VERSION ""

NS_ :

BS_:

BU_: TESTECU BIANSUXIANG SCR EBSECU DisPlay EngineECU
VAL_TABLE_ FMI 31 "Not available" 19 "Received network data in error" 18 "Below normal (moderately severe)" 17 "Below normal (least severe)" 16 "Above normal (moderately severe)" 15 "Above normal (least severe)" 14 "Special intstructions" 13 "Out of calibration" 12 "Bad intelligent device" 11 "Root cause not known" 10 "Abnormal rate of change" 9 "Abnormal update rate" 8 "Abnormal frequency" 7 "Mechanical system not responding" 6 "Current above normal" 5 "Current below normal" 4 "Voltage below normal" 3 "Voltage above normal" 2 "Data erratic" 1 "Below normal (most severe)" 0 "Above normal (most severe)" ;

BO_ 3221225472 VECTOR__INDEPENDENT_SIG_MSG: 0 Vector__XXX
 SG_ AETCTorqueValue : 0|16@1+ (1,0) [0|64255] "Nm" Vector__XXX
 SG_ TrailerWeight : 0|16@1+ (2,0) [0|128510] "kg" Vector__XXX
 SG_ ReferenceTirePressSetting : 0|8@1+ (8,0) [0|2000] "kPa" Vector__XXX
 SG_ ReferenceTirePress : 0|8@1+ (8,0) [0|2000] "kPa" Vector__XXX
 SG_ TirePressThresholdDetection : 0|3@1+ (1,0) [0|7] "" Vector__XXX
 SG_ TireAirLeakageRate : 0|16@1+ (0.1,0) [0|6425.5] "Pa/s" Vector__XXX
 SG_ CTIWheelEndElectricalFault : 0|2@1+ (1,0) [0|3] "" Vector__XXX
 SG_ CTITireStatus : 0|2@1+ (1,0) [0|3] "" Vector__XXX
 SG_ CTIWheelSensorStatus : 0|2@1+ (1,0) [0|3] "" Vector__XXX
 SG_ TireTemp : 0|16@1+ (0.03125,-273) [-273|1734.96875] "deg C" Vector__XXX
 SG_ TirePress : 0|8@1+ (4,0) [0|1000] "kPa" Vector__XXX
 SG_ EngTurningGearEngaged : 0|2@1+ (1,0) [0|3] "" Vector__XXX
 SG_ AETCSpeedValue : 0|16@1+ (0.125,0) [0|8031.875] "rpm" Vector__XXX
 SG_ FlashRedStopLamp : 0|2@1+ (1,0) [0|3] "" Vector__XXX
 SG_ FlashProtectLamp : 0|2@1+ (1,0) [0|3] "" Vector__XXX
 SG_ FlashMalfuncIndicatorLamp : 0|2@1+ (1,0) [0|3] "" Vector__XXX

 CM_ SG_ FlashAmberWarningLamp : 0|2@1+ (1,0) [0|3] "" Vector__XXX
 CM_ SG_ MalfunctionIndicatorLampStatus : 0|2@1+ (1,0) [0|3] "" Vector__XXX
 SG_ AmberWarningLampStatus : 0|2@1+ (1,0) [0|3] "" Vector__XXX
 SG_ RedStopLampState : 0|2@1+ (1,0) [0|3] "" Vector__XXX
 SG_ ProtectLampStatus : 0|2@1+ (1,0) [0|3] "" Vector__XXX
 SG_ DTC5 : 0|32@1+ (1,0) [0|4294967295] "" Vector__XXX
 SG_ DTC4 : 0|32@1+ (1,0) [0|4294967295] "" Vector__XXX
 SG_ DTC3 : 0|32@1+ (1,0) [0|4294967295] "" Vector__XXX
 SG_ DTC2 : 0|32@1+ (1,0) [0|4294967295] "" Vector__XXX
 SG_ DTC1 : 0|32@1+ (1,0) [0|4294967295] "" Vector__XXX
 SG_ FlashRedStopLamp : 0|2@1+ (1,0) [0|3] "" Vector__XXX
 SG_ FlashProtectLamp : 0|2@1+ (1,0) [0|3] "" Vector__XXX
 SG_ FlashMalfuncIndicatorLamp : 0|2@1+ (1,0) [0|3] "" Vector__XXX

 CM_ SG_ FlashAmberWarningLamp : 0|2@1+ (1,0) [0|3] "" Vector__XXX
 SG_ MalfunctionIndicatorLampStatus : 0|2@1+ (1,0) [0|3] "" Vector__XXX
 SG_ AmberWarningLampStatus : 0|2@1+ (1,0) [0|3] "" Vector__XXX
 SG_ RedStopLampState : 0|2@1+ (1,0) [0|3] "" Vector__XXX
 SG_ ProtectLampStatus : 0|2@1+ (1,0) [0|3] "" Vector__XXX
 SG_ DTC5 : 0|32@1+ (1,0) [0|4294967295] "" Vector__XXX
 SG_ DTC4 : 0|32@1+ (1,0) [0|4294967295] "" Vector__XXX
 SG_ DTC3 : 0|32@1+ (1,0) [0|4294967295] "" Vector__XXX
 SG_ DTC2 : 0|32@1+ (1,0) [0|4294967295] "" Vector__XXX
 SG_ DTC1 : 0|32@1+ (1,0) [0|4294967295] "" Vector__XXX
 SG_ DTC5 : 0|32@1+ (1,0) [0|4294967295] "" Vector__XXX
 SG_ DTC4 : 0|32@1+ (1,0) [0|4294967295] "" Vector__XXX
 SG_ DTC3 : 0|32@1+ (1,0) [0|4294967295] "" Vector__XXX
 SG_ DTC2 : 0|32@1+ (1,0) [0|4294967295] "" Vector__XXX
 SG_ DTC5 : 0|32@1+ (1,0) [0|4294967295] "" Vector__XXX
 SG_ DTC4 : 0|32@1+ (1,0) [0|4294967295] "" Vector__XXX
 SG_ DTC3 : 0|32@1+ (1,0) [0|4294967295] "" Vector__XXX
 SG_ DTC2 : 0|32@1+ (1,0) [0|4294967295] "" Vector__XXX

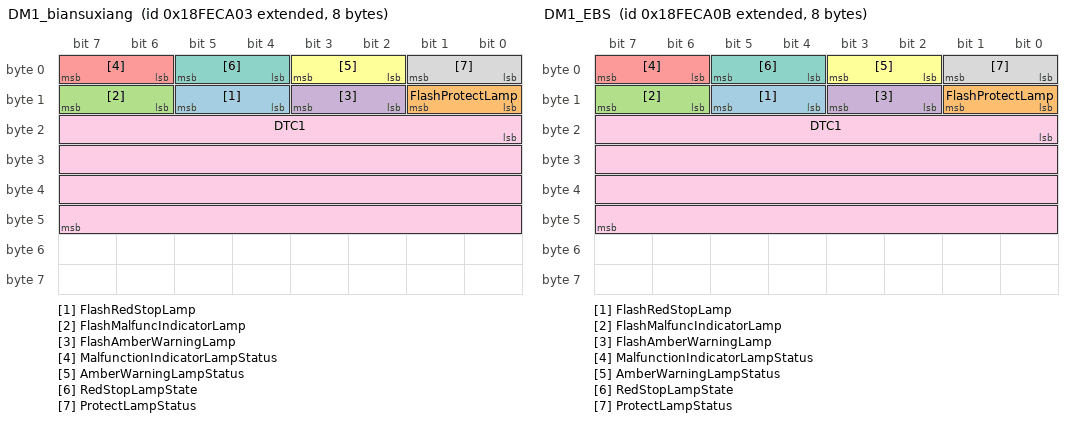
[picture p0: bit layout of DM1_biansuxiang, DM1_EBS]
BO_ 2566834691 DM1_biansuxiang: 8 BIANSUXIANG
 SG_ FlashRedStopLamp : 12|2@1+ (1,0) [0|3] "" Vector__XXX
 SG_ FlashProtectLamp : 8|2@1+ (1,0) [0|3] "" Vector__XXX
 SG_ FlashMalfuncIndicatorLamp : 14|2@1+ (1,0) [0|3] "" Vector__XXX
 SG_ FlashAmberWarningLamp : 10|2@1+ (1,0) [0|3] "" Vector__XXX
 SG_ MalfunctionIndicatorLampStatus : 6|2@1+ (1,0) [0|3] "" Vector__XXX
 SG_ AmberWarningLampStatus : 2|2@1+ (1,0) [0|3] "" Vector__XXX
 SG_ RedStopLampState : 4|2@1+ (1,0) [0|3] "" Vector__XXX
 SG_ ProtectLampStatus : 0|2@1+ (1,0) [0|3] "" Vector__XXX
 SG_ DTC1 : 16|32@1+ (1,0) [0|4294967295] "" Vector__XXX

BO_ 2415854369 Switch_event_3: 8 Vector__XXX

BO_ 2415857185 BOOT_Swtich3: 8 Vector__XXX

BO_ 2415854368 Switch_event_2: 8 Vector__XXX

BO_ 2415857184 BOOT_Swtich2: 8 Vector__XXX

BO_ 2415857406 BOOT_Swtich1: 8 Vector__XXX

BO_ 2415857407 BOOT: 8 Vector__XXX

BO_ 2415854590 Switch_event_1: 8 Vector__XXX

BO_ 2415854591 Switch_event: 8 Vector__XXX

BO_ 2566834699 DM1_EBS: 8 EBSECU
 SG_ FlashRedStopLamp : 12|2@1+ (1,0) [0|3] "" Vector__XXX
 SG_ FlashProtectLamp : 8|2@1+ (1,0) [0|3] "" Vector__XXX
 SG_ FlashMalfuncIndicatorLamp : 14|2@1+ (1,0) [0|3] "" Vector__XXX
 SG_ FlashAmberWarningLamp : 10|2@1+ (1,0) [0|3] "" Vector__XXX
 SG_ MalfunctionIndicatorLampStatus : 6|2@1+ (1,0) [0|3] "" Vector__XXX
 SG_ AmberWarningLampStatus : 2|2@1+ (1,0) [0|3] "" Vector__XXX
 SG_ RedStopLampState : 4|2@1+ (1,0) [0|3] "" Vector__XXX
 SG_ ProtectLampStatus : 0|2@1+ (1,0) [0|3] "" Vector__XXX
 SG_ DTC1 : 16|32@1+ (1,0) [0|4294967295] "" Vector__XXX

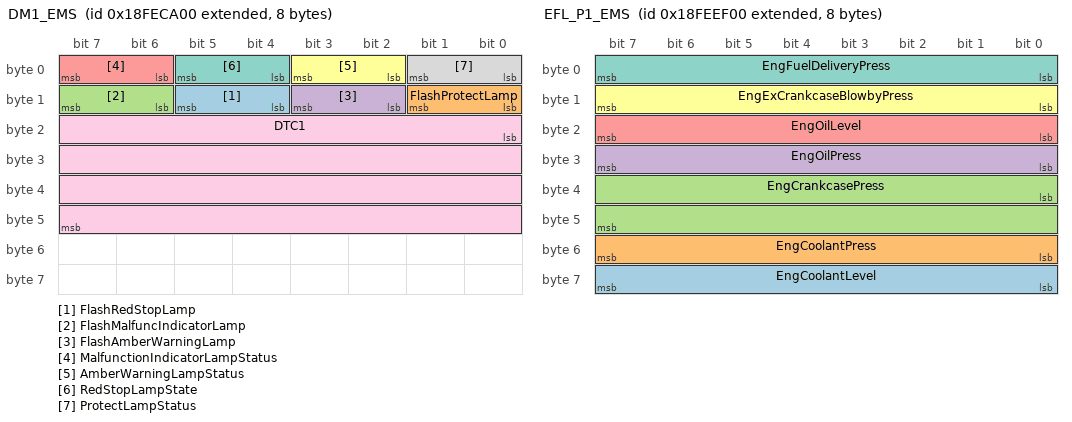
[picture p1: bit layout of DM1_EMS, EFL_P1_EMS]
BO_ 2566834688 DM1_EMS: 8 EngineECU
 SG_ FlashRedStopLamp : 12|2@1+ (1,0) [0|3] "" Vector__XXX
 SG_ FlashProtectLamp : 8|2@1+ (1,0) [0|3] "" Vector__XXX
 SG_ FlashMalfuncIndicatorLamp : 14|2@1+ (1,0) [0|3] "" Vector__XXX
 SG_ FlashAmberWarningLamp : 10|2@1+ (1,0) [0|3] "" Vector__XXX
 SG_ MalfunctionIndicatorLampStatus : 6|2@1+ (1,0) [0|3] "" Vector__XXX
 SG_ AmberWarningLampStatus : 2|2@1+ (1,0) [0|3] "" Vector__XXX
 SG_ RedStopLampState : 4|2@1+ (1,0) [0|3] "" Vector__XXX
 SG_ ProtectLampStatus : 0|2@1+ (1,0) [0|3] "" Vector__XXX
 SG_ DTC1 : 16|32@1+ (1,0) [0|4294967295] "" Vector__XXX

BO_ 2566910720 WCOI: 8 EngineECU
 SG_ WaterInFuelIndicator : 24|2@1+ (1,0) [0|3] ""  DisPlay

BO_ 2566805053 AT1T1I_SCR: 8 SCR
 SG_ Aftrtrtmnt1DslExhstFlidTankLevel : 0|8@1+ (0.4,0) [0|100] "%" Vector__XXX

BO_ 2566804992 AT1T1I_EMS: 8 EngineECU
 SG_ Aftrtrtmnt1DslExhstFlidTankLevel : 0|8@1+ (0.4,0) [0|100] "%"  DisPlay

BO_ 2566844160 EFL_P1_EMS: 8 EngineECU
 SG_ EngCoolantLevel : 56|8@1+ (0.4,0) [0|100] "%" Vector__XXX
 SG_ EngCoolantPress : 48|8@1+ (2,0) [0|500] "kPa" Vector__XXX
 SG_ EngCrankcasePress : 32|16@1+ (0.0078125,-250) [-250|251.99] "kPa" Vector__XXX
 SG_ EngOilPress : 24|8@1+ (4,0) [0|1000] "kPa"  DisPlay
 SG_ EngOilLevel : 16|8@1+ (0.4,0) [0|100] "%" Vector__XXX
 SG_ EngExCrankcaseBlowbyPress : 8|8@1+ (0.05,0) [0|12.5] "kPa" Vector__XXX
 SG_ EngFuelDeliveryPress : 0|8@1+ (4,0) [0|1000] "kPa" Vector__XXX

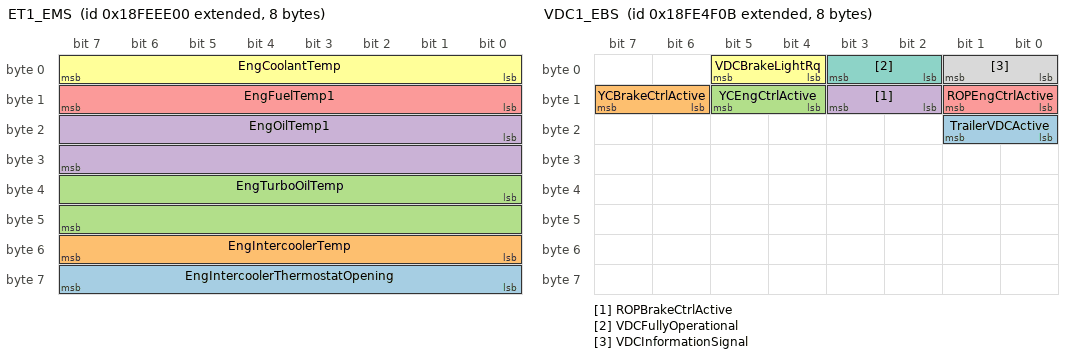
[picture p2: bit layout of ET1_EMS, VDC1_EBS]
BO_ 2566843904 ET1_EMS: 8 EngineECU
 SG_ EngIntercoolerThermostatOpening : 56|8@1+ (0.4,0) [0|100] "%" Vector__XXX
 SG_ EngIntercoolerTemp : 48|8@1+ (1,-40) [-40|210] "deg C" Vector__XXX
 SG_ EngTurboOilTemp : 32|16@1+ (0.03125,-273) [-273|1734.96875] "deg C" Vector__XXX
 SG_ EngOilTemp1 : 16|16@1+ (0.03125,-273) [-273|1734.96875] "deg C" Vector__XXX
 SG_ EngFuelTemp1 : 8|8@1+ (1,-40) [-40|210] "deg C" Vector__XXX
 SG_ EngCoolantTemp : 0|8@1+ (1,-40) [-40|210] "deg C" Vector__XXX

BO_ 2566844672 CCVS1_EMS: 8 EngineECU
 SG_ EngShutdownOverrideSwitch : 62|2@1+ (1,0) [0|3] "" Vector__XXX
 SG_ EngTestModeSwitch : 60|2@1+ (1,0) [0|3] "" Vector__XXX
 SG_ EngIdleDecrementSwitch : 58|2@1+ (1,0) [0|3] "" Vector__XXX
 SG_ EngIdleIncrementSwitch : 56|2@1+ (1,0) [0|3] "" Vector__XXX
 SG_ CruiseCtrlStates : 53|3@1+ (1,0) [0|7] "" Vector__XXX
 SG_ PTOGovernorState : 48|5@1+ (1,0) [0|31] "" Vector__XXX
 SG_ CruiseCtrlSetSpeed : 40|8@1+ (1,0) [0|250] "km/h" Vector__XXX
 SG_ CruiseCtrlAccelerateSwitch : 38|2@1+ (1,0) [0|3] "" Vector__XXX
 SG_ CruiseCtrlResumeSwitch : 36|2@1+ (1,0) [0|3] "" Vector__XXX
 SG_ CruiseCtrlCoastSwitch : 34|2@1+ (1,0) [0|3] "" Vector__XXX
 SG_ CruiseCtrlSetSwitch : 32|2@1+ (1,0) [0|3] "" Vector__XXX
 SG_ ClutchSwitch : 30|2@1+ (1,0) [0|3] "" Vector__XXX
 SG_ BrakeSwitch : 28|2@1+ (1,0) [0|3] "" Vector__XXX
 SG_ CruiseCtrlEnableSwitch : 26|2@1+ (1,0) [0|3] "" Vector__XXX
 SG_ CruiseCtrlActive : 24|2@1+ (1,0) [0|3] ""  DisPlay
 SG_ WheelBasedVehicleSpeed : 8|16@1+ (0.00390625,0) [0|250.996] "km/h" Vector__XXX
 SG_ ParkBrakeReleaseInhibitRq : 6|2@1+ (1,0) [0|3] "" Vector__XXX
 SG_ CruiseCtrlPauseSwitch : 4|2@1+ (1,0) [0|3] "" Vector__XXX
 SG_ ParkingBrakeSwitch : 2|2@1+ (1,0) [0|3] "" Vector__XXX
 SG_ TwoSpeedAxleSwitch : 0|2@1+ (1,0) [0|3] "" Vector__XXX

BO_ 2566841344 SHUTDN_EMS: 8 EngineECU
 SG_ ClntLvlEngPrtctionShutdownStatus : 60|2@1+ (1,0) [0|3] "" Vector__XXX
 SG_ PTOShutdownHasShutdownEng : 58|2@1+ (1,0) [0|3] "" Vector__XXX
 SG_ EngAirShutoffStatus : 56|2@1+ (1,0) [0|3] "" Vector__XXX
 SG_ EngOverspeedTest : 54|2@1+ (1,0) [0|3] "" Vector__XXX
 SG_ EngAirShutoffCmdStatus : 52|2@1+ (1,0) [0|3] "" Vector__XXX
 SG_ EngAlarmOutputCmdStatus : 50|2@1+ (1,0) [0|3] "" Vector__XXX
 SG_ EngAlarmAcknowledge : 48|2@1+ (1,0) [0|3] "" Vector__XXX
 SG_ EngProtectionSystemConfig : 46|2@1+ (1,0) [0|3] "" Vector__XXX
 SG_ EngProtectionSystemTimerState : 38|2@1+ (1,0) [0|3] "" Vector__XXX
 SG_ EngProtectionSystemTimerOverride : 36|2@1+ (1,0) [0|3] "" Vector__XXX
 SG_ EngPrtctnSystmApprachingShutdown : 34|2@1+ (1,0) [0|3] "" Vector__XXX
 SG_ EngPrtectionSystemHasShutdownEng : 32|2@1+ (1,0) [0|3] "" Vector__XXX
 SG_ EngWaitToStartLamp : 24|2@1+ (1,0) [0|3] ""  DisPlay
 SG_ RefrigerantHighPressSwitch : 20|2@1+ (1,0) [0|3] "" Vector__XXX
 SG_ RefrigerantLowPressSwitch : 18|2@1+ (1,0) [0|3] "" Vector__XXX
 SG_ A_CHighPressFanSwitch : 16|2@1+ (1,0) [0|3] "" Vector__XXX
 SG_ EngIdleShutdownTimerFunction : 14|2@1+ (1,0) [0|3] "" Vector__XXX
 SG_ EngIdleShutdownTimerState : 6|2@1+ (1,0) [0|3] "" Vector__XXX
 SG_ EngIdleShutdownTimerOverride : 4|2@1+ (1,0) [0|3] "" Vector__XXX
 SG_ EngIdleShutdownDriverAlertMode : 2|2@1+ (1,0) [0|3] "" Vector__XXX
 SG_ EngIdleShutdownHasShutdownEng : 0|2@1+ (1,0) [0|3] "" Vector__XXX

BO_ 2566803211 VDC1_EBS: 8 EBSECU
 SG_ TrailerVDCActive : 16|2@1+ (1,0) [0|3] "" Vector__XXX
 SG_ YCBrakeCtrlActive : 14|2@1+ (1,0) [0|3] "" Vector__XXX
 SG_ YCEngCtrlActive : 12|2@1+ (1,0) [0|3] "" Vector__XXX
 SG_ ROPBrakeCtrlActive : 10|2@1+ (1,0) [0|3] "" Vector__XXX
 SG_ ROPEngCtrlActive : 8|2@1+ (1,0) [0|3] "" Vector__XXX
 SG_ VDCBrakeLightRq : 4|2@1+ (1,0) [0|3] "" Vector__XXX
 SG_ VDCFullyOperational : 2|2@1+ (1,0) [0|3] "" Vector__XXX
 SG_ VDCInformationSignal : 0|2@1+ (1,0) [0|3] "" Vector__XXX

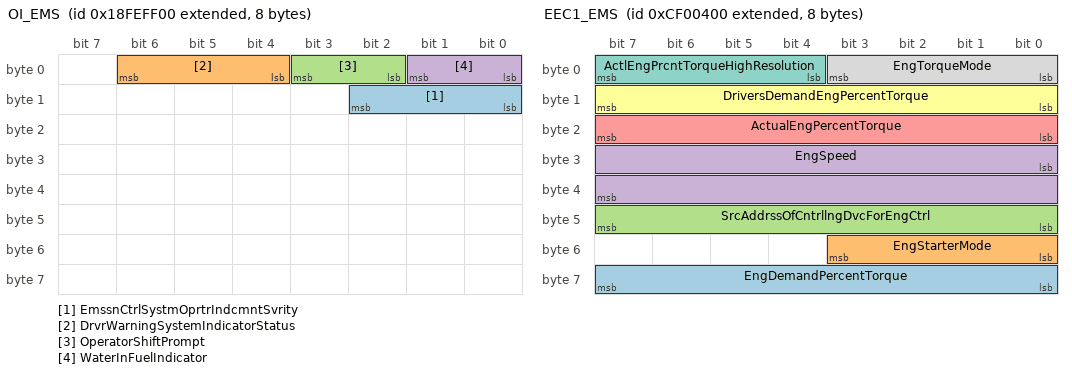
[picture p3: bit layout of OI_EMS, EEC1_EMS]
BO_ 2566848256 OI_EMS: 8 EngineECU
 SG_ EmssnCtrlSystmOprtrIndcmntSvrity : 8|3@1+ (1,0) [0|7] "" Vector__XXX
 SG_ DrvrWarningSystemIndicatorStatus : 4|3@1+ (1,0) [0|7] "" Vector__XXX
 SG_ OperatorShiftPrompt : 2|2@1+ (1,0) [0|3] "" Vector__XXX
 SG_ WaterInFuelIndicator : 0|2@1+ (1,0) [0|3] ""  DisPlay

BO_ 2364539904 EEC1_EMS: 8 EngineECU
 SG_ EngDemandPercentTorque : 56|8@1+ (1,-125) [-125|125] "%"  DisPlay
 SG_ EngStarterMode : 48|4@1+ (1,0) [0|15] ""  DisPlay
 SG_ SrcAddrssOfCntrllngDvcForEngCtrl : 40|8@1+ (1,0) [0|255] ""  DisPlay
 SG_ EngSpeed : 24|16@1+ (0.125,0) [0|8031.875] "rpm"  DisPlay
 SG_ ActualEngPercentTorque : 16|8@1+ (1,-125) [-125|125] "%"  DisPlay
 SG_ DriversDemandEngPercentTorque : 8|8@1+ (1,-125) [-125|125] "%"  DisPlay
 SG_ ActlEngPrcntTorqueHighResolution : 4|4@1+ (0.125,0) [0|0.875] "%"  DisPlay
 SG_ EngTorqueMode : 0|4@1+ (1,0) [0|15] ""  DisPlay

BO_ 2559835902 NM: 8 Vector__XXX
 SG_ NameChecksum m0 : 0|8@1+ (1,0) [0|0] "" Vector__XXX
 SG_ ErrorCode m4 : 0|8@1+ (1,0) [0|0] "" Vector__XXX
 SG_ CommandArbitraryAddressCapable m0 : 63|1@1+ (1,0) [0|1] "" Vector__XXX
 SG_ CommandVehicleSystemInstance m0 : 56|4@1+ (1,0) [0|15] "" Vector__XXX
 SG_ CommandIndustryGroup m0 : 60|3@1+ (1,0) [0|7] "" Vector__XXX
 SG_ CommandVehicleSystem m0 : 49|7@1+ (1,0) [0|127] "" Vector__XXX
 SG_ CommandFunction m0 : 40|8@1+ (1,0) [0|255] "" Vector__XXX
 SG_ CommandFunctionInstance m0 : 35|5@1+ (1,0) [0|31] "" Vector__XXX
 SG_ CommandECUInstance m0 : 32|3@1+ (1,0) [0|7] "" Vector__XXX
 SG_ CommandManufacturerCode m0 : 21|11@1+ (1,0) [0|2047] "" Vector__XXX
 SG_ NMControlModeIndicator M : 16|4@1+ (1,0) [0|15] "" Vector__XXX
 SG_ ArbitraryAddressCapableQualifier m0 : 15|1@1+ (1,0) [0|1] "" Vector__XXX
 SG_ IndustryGroupQualifierFlag m0 : 14|1@1+ (1,0) [0|1] "" Vector__XXX
 SG_ VehicleSystemInstanceQualifierFl m0 : 13|1@1+ (1,0) [0|1] "" Vector__XXX
 SG_ VehicleSystemQualifierFlag m0 : 12|1@1+ (1,0) [0|1] "" Vector__XXX
 SG_ FunctionQualifierFlag m0 : 11|1@1+ (1,0) [0|1] "" Vector__XXX
 SG_ FunctionInstanceQualifierFlag m0 : 10|1@1+ (1,0) [0|1] "" Vector__XXX
 SG_ ECUInstanceQualifierFlag m0 : 9|1@1+ (1,0) [0|1] "" Vector__XXX
 SG_ ManufacturerCodeQualifierFlag m0 : 8|1@1+ (1,0) [0|1] "" Vector__XXX

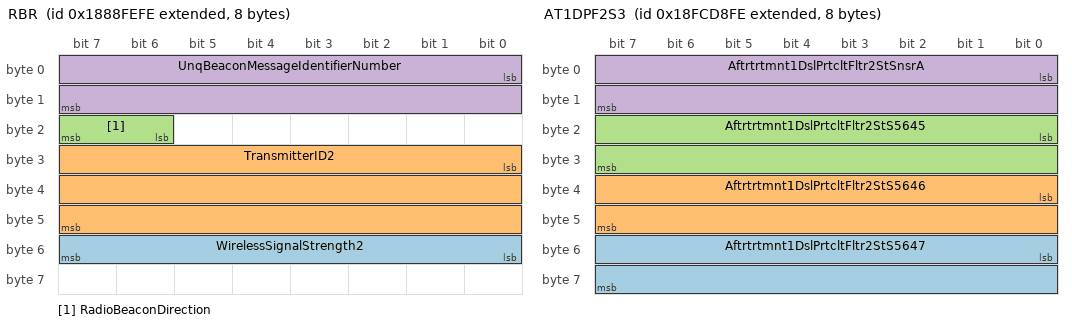
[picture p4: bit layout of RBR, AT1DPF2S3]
BO_ 2559115006 RBR: 8 Vector__XXX
 SG_ WirelessSignalStrength2 : 48|8@1+ (0.5,0) [-125|0] "dBm" Vector__XXX
 SG_ TransmitterID2 : 24|24@1+ (1,0) [0|16449635] "" Vector__XXX
 SG_ RadioBeaconDirection : 22|2@1+ (1,0) [0|3] "" Vector__XXX
 SG_ UnqBeaconMessageIdentifierNumber : 0|16@1+ (1,0) [0|64255] "" Vector__XXX

BO_ 2566707454 AT1DPF2S3: 8 Vector__XXX
 SG_ Aftrtrtmnt1DslPrtcltFltr2StS5647 : 48|16@1+ (0.1,0) [0|6425.5] "MHz" Vector__XXX
 SG_ Aftrtrtmnt1DslPrtcltFltr2StS5646 : 32|16@1+ (0.1,0) [0|6425.5] "MHz" Vector__XXX
 SG_ Aftrtrtmnt1DslPrtcltFltr2StS5645 : 16|16@1+ (0.1,0) [0|6425.5] "MHz" Vector__XXX
 SG_ Aftrtrtmnt1DslPrtcltFltr2StSnsrA : 0|16@1+ (0.1,0) [0|6425.5] "MHz" Vector__XXX

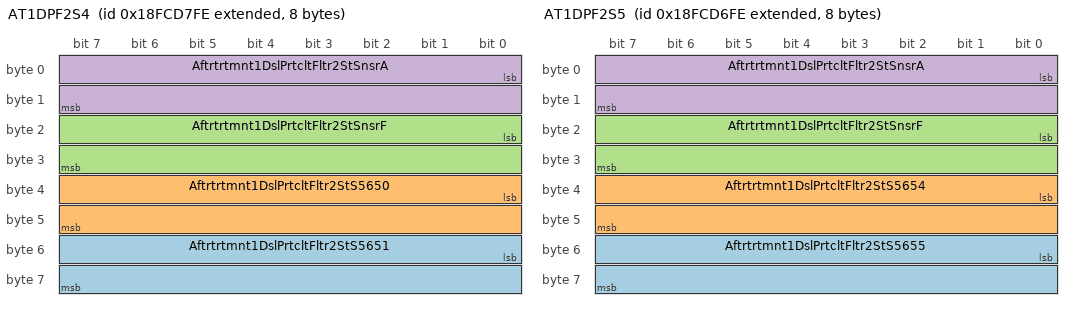
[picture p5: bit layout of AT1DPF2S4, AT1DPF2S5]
BO_ 2566707198 AT1DPF2S4: 8 Vector__XXX
 SG_ Aftrtrtmnt1DslPrtcltFltr2StS5651 : 48|16@1+ (0.0025,0) [0|160.6375] "%" Vector__XXX
 SG_ Aftrtrtmnt1DslPrtcltFltr2StS5650 : 32|16@1+ (0.1,0) [0|6425.5] "MHz" Vector__XXX
 SG_ Aftrtrtmnt1DslPrtcltFltr2StSnsrF : 16|16@1+ (0.0025,0) [0|160.6375] "%" Vector__XXX
 SG_ Aftrtrtmnt1DslPrtcltFltr2StSnsrA : 0|16@1+ (0.1,0) [0|6425.5] "MHz" Vector__XXX

BO_ 2566706942 AT1DPF2S5: 8 Vector__XXX
 SG_ Aftrtrtmnt1DslPrtcltFltr2StS5655 : 48|16@1+ (0.0025,0) [0|160.6375] "%" Vector__XXX
 SG_ Aftrtrtmnt1DslPrtcltFltr2StS5654 : 32|16@1+ (0.1,0) [0|6425.5] "MHz" Vector__XXX
 SG_ Aftrtrtmnt1DslPrtcltFltr2StSnsrF : 16|16@1+ (0.0025,0) [0|160.6375] "%" Vector__XXX
 SG_ Aftrtrtmnt1DslPrtcltFltr2StSnsrA : 0|16@1+ (0.1,0) [0|6425.5] "MHz" Vector__XXX

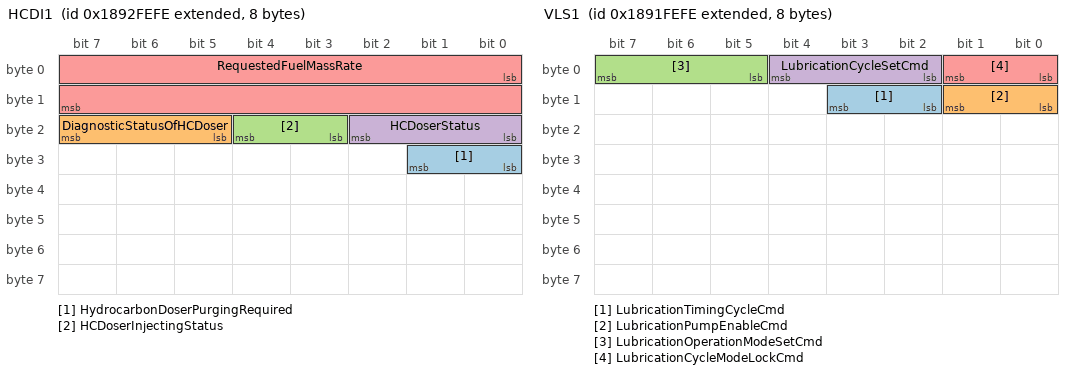
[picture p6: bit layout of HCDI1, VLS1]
BO_ 2559770366 HCDI1: 8 Vector__XXX
 SG_ HydrocarbonDoserPurgingRequired : 24|2@1+ (1,0) [0|3] "" Vector__XXX
 SG_ DiagnosticStatusOfHCDoser : 21|3@1+ (1,0) [0|7] "" Vector__XXX
 SG_ HCDoserInjectingStatus : 19|2@1+ (1,0) [0|3] "" Vector__XXX
 SG_ HCDoserStatus : 16|3@1+ (1,0) [0|7] "" Vector__XXX
 SG_ RequestedFuelMassRate : 0|16@1+ (0.05,0) [0|3212.75] "g/m" Vector__XXX

BO_ 2559704830 VLS1: 8 Vector__XXX
 SG_ LubricationTimingCycleCmd : 10|2@1+ (1,0) [0|3] "" Vector__XXX
 SG_ LubricationPumpEnableCmd : 8|2@1+ (1,0) [0|3] "" Vector__XXX
 SG_ LubricationOperationModeSetCmd : 5|3@1+ (1,0) [0|7] "" Vector__XXX
 SG_ LubricationCycleSetCmd : 2|3@1+ (1,0) [0|7] "" Vector__XXX
 SG_ LubricationCycleModeLockCmd : 0|2@1+ (1,0) [0|3] "" Vector__XXX

BO_ 2559639294 SFC: 8 Vector__XXX
 SG_ SupplementalFanPowerHold : 24|2@1+ (1,0) [0|3] "" Vector__XXX
 SG_ SupplementalFanSpeedCmd : 8|16@1+ (0.5,0) [0|32127.5] "rpm" Vector__XXX
 SG_ SupplementalFanDirectionCmd : 2|2@1+ (1,0) [0|3] "" Vector__XXX
 SG_ SupplementalFanEnableCmd : 0|2@1+ (1,0) [0|3] "" Vector__XXX

BO_ 2559573758 ECC: 8 Vector__XXX
 SG_ ClntLvlEngPrtctnShtdwnOvrrideCmd : 0|2@1+ (1,0) [0|3] "" Vector__XXX

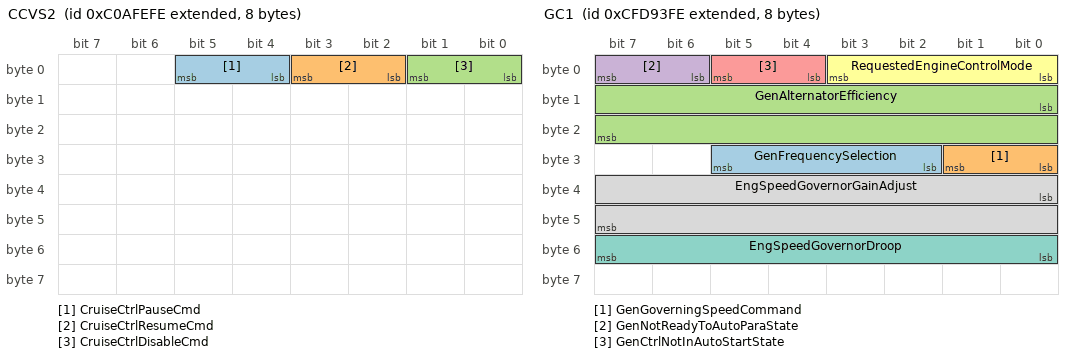
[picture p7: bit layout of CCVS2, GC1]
BO_ 2349530878 CCVS2: 8 Vector__XXX
 SG_ CruiseCtrlPauseCmd : 4|2@1+ (1,0) [0|3] "" Vector__XXX
 SG_ CruiseCtrlResumeCmd : 2|2@1+ (1,0) [0|3] "" Vector__XXX
 SG_ CruiseCtrlDisableCmd : 0|2@1+ (1,0) [0|3] "" Vector__XXX

BO_ 2559246078 RGE12: 8 Vector__XXX

BO_ 2559180542 RGE24: 8 Vector__XXX

BO_ 2365428734 GC1: 8 Vector__XXX
 SG_ GenFrequencySelection : 26|4@1+ (1,0) [0|15] "" Vector__XXX
 SG_ GenGoverningSpeedCommand : 24|2@1+ (1,0) [0|3] "" Vector__XXX
 SG_ GenAlternatorEfficiency : 8|16@1+ (0.0025,0) [0|163.8375] "%" Vector__XXX
 SG_ GenNotReadyToAutoParaState : 6|2@1+ (1,0) [0|0] "" Vector__XXX
 SG_ GenCtrlNotInAutoStartState : 4|2@1+ (1,0) [0|0] "" Vector__XXX
 SG_ RequestedEngineControlMode : 0|4@1+ (1,0) [0|0] "" Vector__XXX
 SG_ EngSpeedGovernorDroop : 48|8@1+ (0.04,0) [0|10] "%" Vector__XXX
 SG_ EngSpeedGovernorGainAdjust : 32|16@1+ (1,-32128) [-32128|32127] "" Vector__XXX

BO_ 2566702846 DM57: 8 Vector__XXX
 SG_ EngOBDWarmUpSequence : 0|2@1+ (1,0) [0|3] "" Vector__XXX

BO_ 2566703102 DM56: 208 Vector__XXX
 SG_ CertificationEngineFamilyName : 64|64@1+ (1,0) [0|255] "" Vector__XXX
 SG_ ModelYear : 0|64@1+ (1,0) [0|1.84467440737096E+019] "" Vector__XXX

BO_ 2566705918 DM54: 22 Vector__XXX
 SG_ DTC1 : 16|32@1+ (1,0) [0|4294967295] "" Vector__XXX
 SG_ FlashProtectLamp : 8|2@1+ (1,0) [0|3] "" Vector__XXX
 SG_ FlashAmberWarningLamp : 10|2@1+ (1,0) [0|3] "" Vector__XXX
 SG_ FlashRedStopLamp : 12|2@1+ (1,0) [0|3] "" Vector__XXX
 SG_ FlashMalfuncIndicatorLamp : 14|2@1+ (1,0) [0|3] "" Vector__XXX
 SG_ ProtectLampStatus : 0|2@1+ (1,0) [0|3] "" Vector__XXX
 SG_ AmberWarningLampStatus : 2|2@1+ (1,0) [0|3] "" Vector__XXX
 SG_ RedStopLampState : 4|2@1+ (1,0) [0|3] "" Vector__XXX
 SG_ MalfunctionIndicatorLampStatus : 6|2@1+ (1,0) [0|3] "" Vector__XXX
 SG_ DTC5 : 144|32@1+ (1,0) [0|4294967295] "" Vector__XXX
 SG_ DTC4 : 112|32@1+ (1,0) [0|4294967295] "" Vector__XXX
 SG_ DTC3 : 80|32@1+ (1,0) [0|4294967295] "" Vector__XXX
 SG_ DTC2 : 48|32@1+ (1,0) [0|4294967295] "" Vector__XXX

BO_ 2566705662 DM53: 22 Vector__XXX
 SG_ DTC1 : 16|32@1+ (1,0) [0|4294967295] "" Vector__XXX
 SG_ FlashProtectLamp : 8|2@1+ (1,0) [0|3] "" Vector__XXX
 SG_ FlashAmberWarningLamp : 10|2@1+ (1,0) [0|3] "" Vector__XXX
 SG_ FlashRedStopLamp : 12|2@1+ (1,0) [0|3] "" Vector__XXX
 SG_ FlashMalfuncIndicatorLamp : 14|2@1+ (1,0) [0|3] "" Vector__XXX
 SG_ ProtectLampStatus : 0|2@1+ (1,0) [0|3] "" Vector__XXX
 SG_ AmberWarningLampStatus : 2|2@1+ (1,0) [0|3] "" Vector__XXX
 SG_ RedStopLampState : 4|2@1+ (1,0) [0|3] "" Vector__XXX
 SG_ MalfunctionIndicatorLampStatus : 6|2@1+ (1,0) [0|3] "" Vector__XXX
 SG_ DTC5 : 144|32@1+ (1,0) [0|4294967295] "" Vector__XXX
 SG_ DTC4 : 112|32@1+ (1,0) [0|4294967295] "" Vector__XXX
 SG_ DTC3 : 80|32@1+ (1,0) [0|4294967295] "" Vector__XXX
 SG_ DTC2 : 48|32@1+ (1,0) [0|4294967295] "" Vector__XXX

BO_ 2566706174 DM55: 0 Vector__XXX

BO_ 2349465342 SRASI: 8 Vector__XXX
 SG_ StaticRollAngleStatus : 8|3@1+ (1,0) [0|7] "" Vector__XXX
 SG_ StaticRollAngle : 0|8@1+ (1,-125) [-125|125] "deg" Vector__XXX

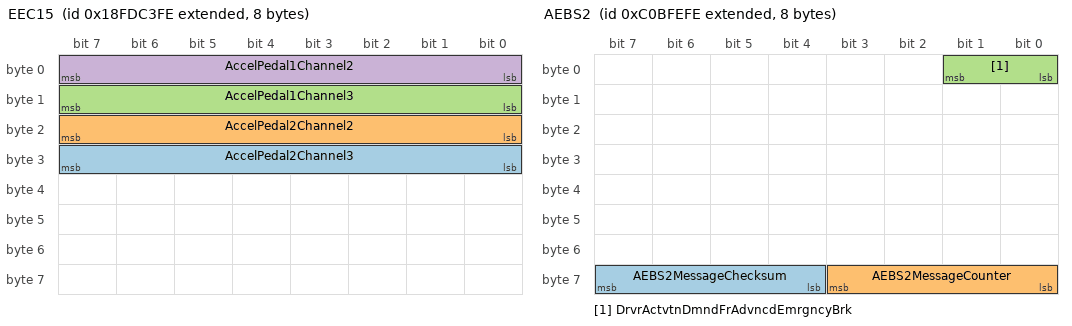
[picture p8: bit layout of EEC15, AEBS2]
BO_ 2566767614 EEC15: 8 Vector__XXX
 SG_ AccelPedal2Channel3 : 24|8@1+ (0.4,0) [0|100] "%" Vector__XXX
 SG_ AccelPedal2Channel2 : 16|8@1+ (0.4,0) [0|100] "%" Vector__XXX
 SG_ AccelPedal1Channel3 : 8|8@1+ (0.4,0) [0|100] "%" Vector__XXX
 SG_ AccelPedal1Channel2 : 0|8@1+ (0.4,0) [0|100] "%" Vector__XXX

BO_ 2559049470 ESR: 8 Vector__XXX
 SG_ DesiredEngFuelingState : 0|2@1+ (1,0) [0|3] "" Vector__XXX

BO_ 2349596414 AEBS2: 8 Vector__XXX
 SG_ AEBS2MessageChecksum : 60|4@1+ (1,0) [0|15] "" Vector__XXX
 SG_ AEBS2MessageCounter : 56|4@1+ (1,0) [0|15] "" Vector__XXX
 SG_ DrvrActvtnDmndFrAdvncdEmrgncyBrk : 0|2@1+ (1,0) [0|3] "" Vector__XXX

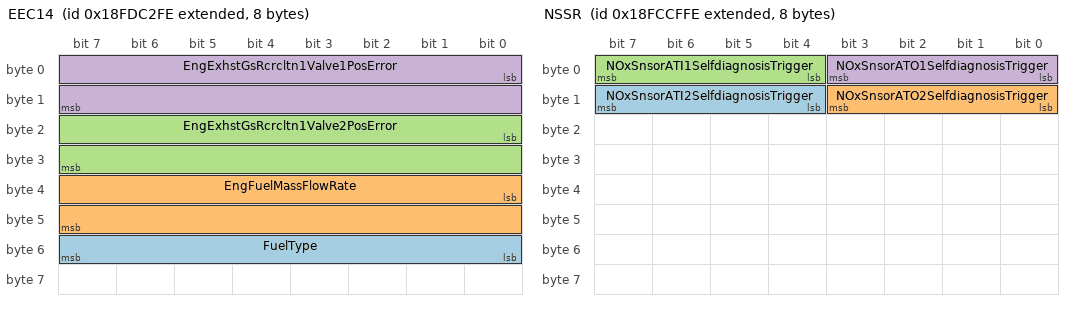
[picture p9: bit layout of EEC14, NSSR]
BO_ 2566767358 EEC14: 8 Vector__XXX
 SG_ FuelType : 48|8@1+ (1,0) [0|255] "" Vector__XXX
 SG_ EngFuelMassFlowRate : 32|16@1+ (0.005,0) [0|321.275] "g/s" Vector__XXX
 SG_ EngExhstGsRcrcltn1Valve2PosError : 16|16@1+ (0.004,-125) [-125|132.02] "%" Vector__XXX
 SG_ EngExhstGsRcrcltn1Valve1PosError : 0|16@1+ (0.004,-125) [-125|132.02] "%" Vector__XXX

BO_ 2566706686 AT1P1I: 8 Vector__XXX
 SG_ Aftrtrtmnt1DslExhstFldPumpHeater : 0|8@1+ (0.4,0) [0|100] "%" Vector__XXX

BO_ 2566705406 EPSI: 8 Vector__XXX
 SG_ Aftertreatment2ParticulateSensor : 16|16@1+ (0.0125,0) [0|803.1875] "mg/m^3" Vector__XXX
 SG_ Aftertreatment1ParticulateSensor : 0|16@1+ (0.0125,0) [0|803.1875] "mg/m^3" Vector__XXX

BO_ 2566705150 NSSR: 8 Vector__XXX
 SG_ NOxSnsorATI2SelfdiagnosisTrigger : 12|4@1+ (1,0) [0|15] "" Vector__XXX
 SG_ NOxSnsorATO2SelfdiagnosisTrigger : 8|4@1+ (1,0) [0|15] "" Vector__XXX
 SG_ NOxSnsorATI1SelfdiagnosisTrigger : 4|4@1+ (1,0) [0|15] "" Vector__XXX
 SG_ NOxSnsorATO1SelfdiagnosisTrigger : 0|4@1+ (1,0) [0|15] "" Vector__XXX

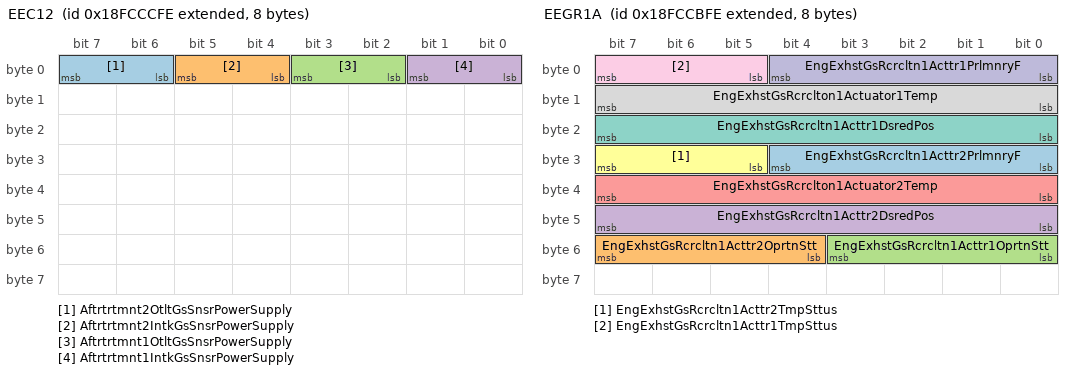
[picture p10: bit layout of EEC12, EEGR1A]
BO_ 2566704382 EEC12: 8 Vector__XXX
 SG_ Aftrtrtmnt2OtltGsSnsrPowerSupply : 6|2@1+ (1,0) [0|3] "" Vector__XXX
 SG_ Aftrtrtmnt2IntkGsSnsrPowerSupply : 4|2@1+ (1,0) [0|3] "" Vector__XXX
 SG_ Aftrtrtmnt1OtltGsSnsrPowerSupply : 2|2@1+ (1,0) [0|3] "" Vector__XXX
 SG_ Aftrtrtmnt1IntkGsSnsrPowerSupply : 0|2@1+ (1,0) [0|3] "" Vector__XXX

BO_ 2566704126 EEGR1A: 8 Vector__XXX
 SG_ EngExhstGsRcrcltn1Acttr2PrlmnryF : 24|5@1+ (1,0) [0|31] "" Vector__XXX
 SG_ EngExhstGsRcrcltn1Acttr2OprtnStt : 52|4@1+ (1,0) [0|15] "" Vector__XXX
 SG_ EngExhstGsRcrcltn1Acttr1OprtnStt : 48|4@1+ (1,0) [0|15] "" Vector__XXX
 SG_ EngExhstGsRcrcltn1Acttr2DsredPos : 40|8@1+ (0.4,0) [0|100] "%" Vector__XXX
 SG_ EngExhstGsRcrclton1Actuator2Temp : 32|8@1+ (1,-40) [-40|210] "deg C" Vector__XXX
 SG_ EngExhstGsRcrcltn1Acttr2TmpSttus : 29|3@1+ (1,0) [0|7] "" Vector__XXX
 SG_ EngExhstGsRcrcltn1Acttr1DsredPos : 16|8@1+ (0.4,0) [0|100] "%" Vector__XXX
 SG_ EngExhstGsRcrclton1Actuator1Temp : 8|8@1+ (1,-40) [-40|210] "deg C" Vector__XXX
 SG_ EngExhstGsRcrcltn1Acttr1TmpSttus : 5|3@1+ (1,0) [0|7] "" Vector__XXX
 SG_ EngExhstGsRcrcltn1Acttr1PrlmnryF : 0|5@1+ (1,0) [0|31] "" Vector__XXX

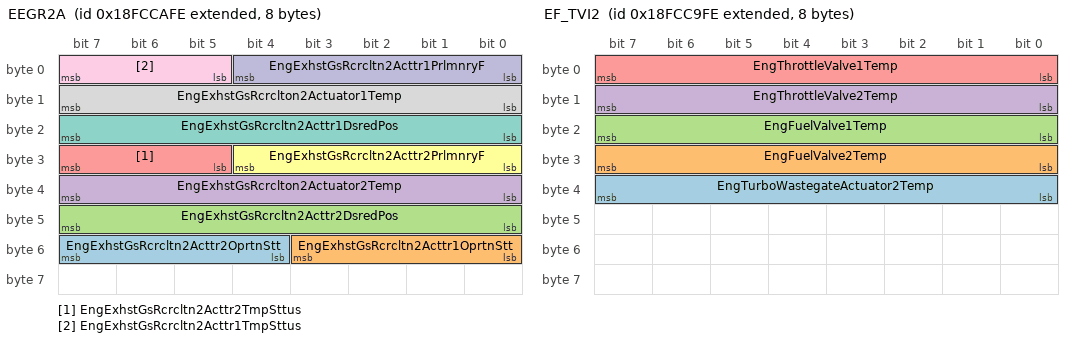
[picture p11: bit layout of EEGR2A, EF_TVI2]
BO_ 2566703870 EEGR2A: 8 Vector__XXX
 SG_ EngExhstGsRcrcltn2Acttr2OprtnStt : 52|4@1+ (1,0) [0|15] "" Vector__XXX
 SG_ EngExhstGsRcrcltn2Acttr1OprtnStt : 48|4@1+ (1,0) [0|15] "" Vector__XXX
 SG_ EngExhstGsRcrcltn2Acttr2DsredPos : 40|8@1+ (0.4,0) [0|100] "%" Vector__XXX
 SG_ EngExhstGsRcrclton2Actuator2Temp : 32|8@1+ (1,-40) [-40|210] "deg C" Vector__XXX
 SG_ EngExhstGsRcrcltn2Acttr2TmpSttus : 29|3@1+ (1,0) [0|7] "" Vector__XXX
 SG_ EngExhstGsRcrcltn2Acttr2PrlmnryF : 24|5@1+ (1,0) [0|31] "" Vector__XXX
 SG_ EngExhstGsRcrcltn2Acttr1DsredPos : 16|8@1+ (0.4,0) [0|100] "%" Vector__XXX
 SG_ EngExhstGsRcrclton2Actuator1Temp : 8|8@1+ (1,-40) [-40|210] "deg C" Vector__XXX
 SG_ EngExhstGsRcrcltn2Acttr1TmpSttus : 5|3@1+ (1,0) [0|7] "" Vector__XXX
 SG_ EngExhstGsRcrcltn2Acttr1PrlmnryF : 0|5@1+ (1,0) [0|31] "" Vector__XXX

BO_ 2566703614 EF_TVI2: 8 Vector__XXX
 SG_ EngTurboWastegateActuator2Temp : 32|8@1+ (1,-40) [-40|210] "deg C" Vector__XXX
 SG_ EngFuelValve2Temp : 24|8@1+ (1,-40) [-40|210] "deg C" Vector__XXX
 SG_ EngFuelValve1Temp : 16|8@1+ (1,-40) [-40|210] "deg C" Vector__XXX
 SG_ EngThrottleValve2Temp : 8|8@1+ (1,-40) [-40|210] "deg C" Vector__XXX
 SG_ EngThrottleValve1Temp : 0|8@1+ (1,-40) [-40|210] "deg C" Vector__XXX

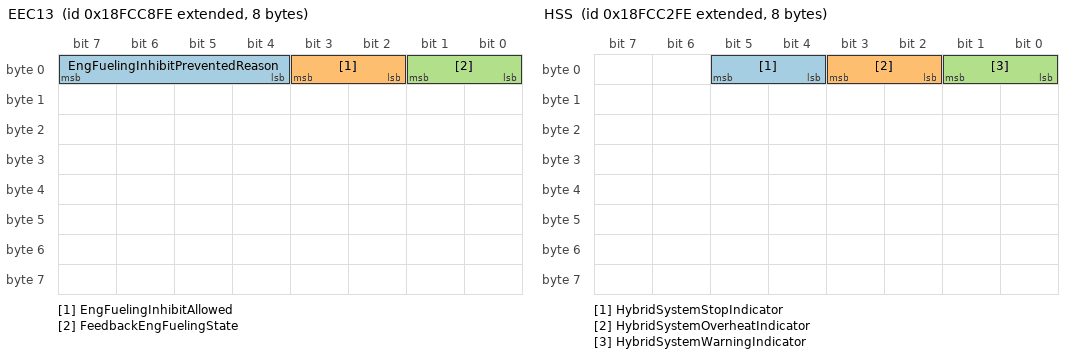
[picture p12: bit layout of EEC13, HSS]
BO_ 2566703358 EEC13: 8 Vector__XXX
 SG_ EngFuelingInhibitPreventedReason : 4|4@1+ (1,0) [0|15] "" Vector__XXX
 SG_ EngFuelingInhibitAllowed : 2|2@1+ (1,0) [0|3] "" Vector__XXX
 SG_ FeedbackEngFuelingState : 0|2@1+ (1,0) [0|3] "" Vector__XXX

BO_ 2566702590 A1SCREGT2: 8 Vector__XXX
 SG_ Aftrtrtmnt1SCRIntrmdtGsTmpPrlmnr : 16|5@1+ (1,0) [0|31] "" Vector__XXX
 SG_ Aftrtrtmnt1SCRIntrmediateGasTemp : 0|16@1+ (0.03125,-273) [-273|1734.96875] "deg C" Vector__XXX

BO_ 2566702334 A2SCREGT2: 8 Vector__XXX
 SG_ Aftrtrtmnt2SCRIntrmdtGsTmpPrlmnr : 16|5@1+ (1,0) [0|31] "" Vector__XXX
 SG_ Aftrtrtmnt2SCRIntrmediateGasTemp : 0|16@1+ (0.03125,-273) [-273|1734.96875] "deg C" Vector__XXX

BO_ 2566702078 GFI4: 8 Vector__XXX
 SG_ SupplyGasMethanePercentage : 0|16@1+ (0.0025,0) [0|160.6375] "%" Vector__XXX

BO_ 2566701822 HSS: 8 Vector__XXX
 SG_ HybridSystemStopIndicator : 4|2@1+ (1,0) [0|3] "" Vector__XXX
 SG_ HybridSystemOverheatIndicator : 2|2@1+ (1,0) [0|3] "" Vector__XXX
 SG_ HybridSystemWarningIndicator : 0|2@1+ (1,0) [0|3] "" Vector__XXX

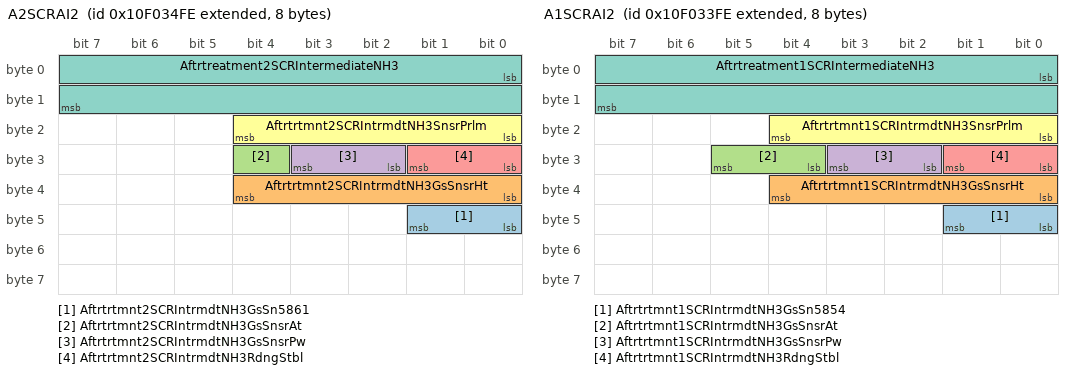
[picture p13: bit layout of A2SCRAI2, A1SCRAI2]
BO_ 2431661310 A2SCRAI2: 8 Vector__XXX
 SG_ Aftrtrtmnt2SCRIntrmdtNH3GsSn5861 : 40|2@1+ (1,0) [0|3] "" Vector__XXX
 SG_ Aftrtrtmnt2SCRIntrmdtNH3GsSnsrHt : 32|5@1+ (1,0) [0|31] "" Vector__XXX
 SG_ Aftrtrtmnt2SCRIntrmdtNH3GsSnsrAt : 28|1@1+ (1,0) [0|1] "" Vector__XXX
 SG_ Aftrtrtmnt2SCRIntrmdtNH3GsSnsrPw : 26|2@1+ (1,0) [0|3] "" Vector__XXX
 SG_ Aftrtrtmnt2SCRIntrmdtNH3RdngStbl : 24|2@1+ (1,0) [0|3] "" Vector__XXX
 SG_ Aftrtrtmnt2SCRIntrmdtNH3SnsrPrlm : 16|5@1+ (1,0) [0|31] "" Vector__XXX
 SG_ Aftrtreatment2SCRIntermediateNH3 : 0|16@1+ (0.1,-200) [-200|6225.5] "ppm" Vector__XXX

BO_ 2431661054 A1SCRAI2: 8 Vector__XXX
 SG_ Aftrtrtmnt1SCRIntrmdtNH3GsSn5854 : 40|2@1+ (1,0) [0|3] "" Vector__XXX
 SG_ Aftrtrtmnt1SCRIntrmdtNH3GsSnsrHt : 32|5@1+ (1,0) [0|31] "" Vector__XXX
 SG_ Aftrtrtmnt1SCRIntrmdtNH3GsSnsrAt : 28|2@1+ (1,0) [0|3] "" Vector__XXX
 SG_ Aftrtrtmnt1SCRIntrmdtNH3GsSnsrPw : 26|2@1+ (1,0) [0|3] "" Vector__XXX
 SG_ Aftrtrtmnt1SCRIntrmdtNH3RdngStbl : 24|2@1+ (1,0) [0|3] "" Vector__XXX
 SG_ Aftrtrtmnt1SCRIntrmdtNH3SnsrPrlm : 16|5@1+ (1,0) [0|31] "" Vector__XXX
 SG_ Aftrtreatment1SCRIntermediateNH3 : 0|16@1+ (0.1,-200) [-200|6225.5] "ppm" Vector__XXX

BO_ 2230334206 LDISP: 8 Vector__XXX
 SG_ LnrDsplcmntSnsrSnsrFigureOfMerit : 16|2@1+ (1,0) [0|3] "" Vector__XXX
 SG_ MeasuredLinearDisplacement : 0|16@1+ (0.1,0) [0|6425.5] "mm" Vector__XXX

BO_ 2230333950 WAND: 8 Vector__XXX
 SG_ WandSensorFigureOfMerit : 16|2@1+ (1,0) [0|3] "" Vector__XXX
 SG_ WandAngle : 0|16@1+ (0.002,-64) [-64|64.51] "deg" Vector__XXX

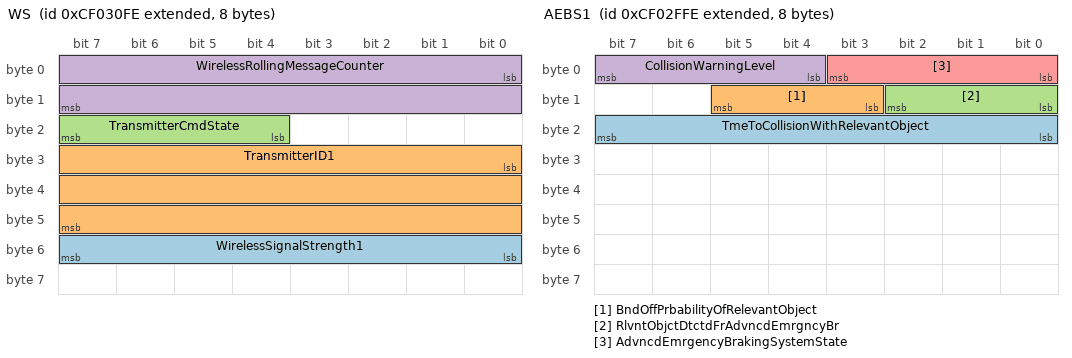
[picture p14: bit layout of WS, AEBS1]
BO_ 2364551422 WS: 8 Vector__XXX
 SG_ WirelessSignalStrength1 : 48|8@1+ (0.5,0) [-125|0] "dBm" Vector__XXX
 SG_ TransmitterID1 : 24|24@1+ (1,0) [0|16449635] "" Vector__XXX
 SG_ TransmitterCmdState : 20|4@1+ (1,0) [0|15] "" Vector__XXX
 SG_ WirelessRollingMessageCounter : 0|16@1+ (1,0) [0|64255] "" Vector__XXX

BO_ 2364551166 AEBS1: 8 Vector__XXX
 SG_ TmeToCollisionWithRelevantObject : 16|8@1+ (0.05,0) [0|12.5] "s" Vector__XXX
 SG_ BndOffPrbabilityOfRelevantObject : 11|3@1+ (1,0) [0|7] "" Vector__XXX
 SG_ RlvntObjctDtctdFrAdvncdEmrgncyBr : 8|3@1+ (1,0) [0|7] "" Vector__XXX
 SG_ CollisionWarningLevel : 4|4@1+ (1,0) [0|15] "" Vector__XXX
 SG_ AdvncdEmrgencyBrakingSystemState : 0|4@1+ (1,0) [0|15] "" Vector__XXX

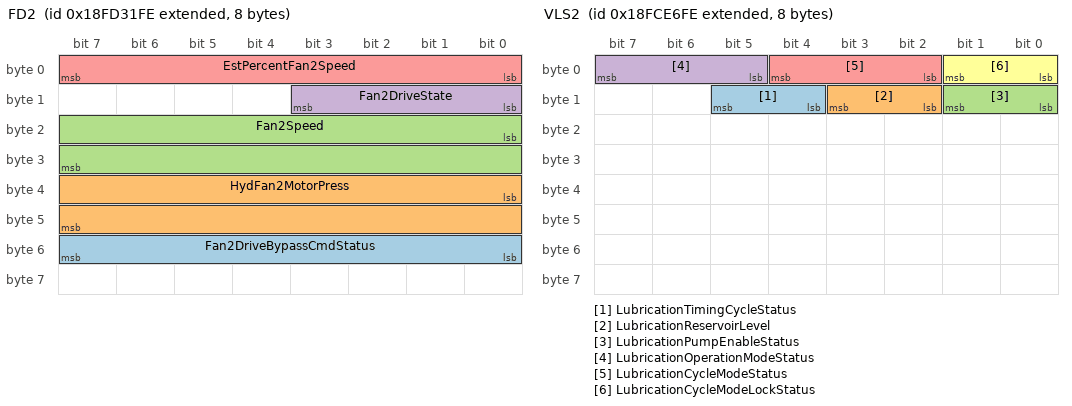
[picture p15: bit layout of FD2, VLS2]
BO_ 2566730238 FD2: 8 Vector__XXX
 SG_ Fan2DriveBypassCmdStatus : 48|8@1+ (0.4,0) [0|100] "%" Vector__XXX
 SG_ HydFan2MotorPress : 32|16@1+ (0.5,0) [0|32127.5] "kPa" Vector__XXX
 SG_ Fan2Speed : 16|16@1+ (0.125,0) [0|8031.875] "rpm" Vector__XXX
 SG_ Fan2DriveState : 8|4@1+ (1,0) [0|15] "" Vector__XXX
 SG_ EstPercentFan2Speed : 0|8@1+ (0.4,0) [0|100] "%" Vector__XXX

BO_ 2566711038 VLS2: 8 Vector__XXX
 SG_ LubricationTimingCycleStatus : 12|2@1+ (1,0) [0|3] "" Vector__XXX
 SG_ LubricationReservoirLevel : 10|2@1+ (1,0) [0|3] "" Vector__XXX
 SG_ LubricationPumpEnableStatus : 8|2@1+ (1,0) [0|3] "" Vector__XXX
 SG_ LubricationOperationModeStatus : 5|3@1+ (1,0) [0|7] "" Vector__XXX
 SG_ LubricationCycleModeStatus : 2|3@1+ (1,0) [0|7] "" Vector__XXX
 SG_ LubricationCycleModeLockStatus : 0|2@1+ (1,0) [0|3] "" Vector__XXX

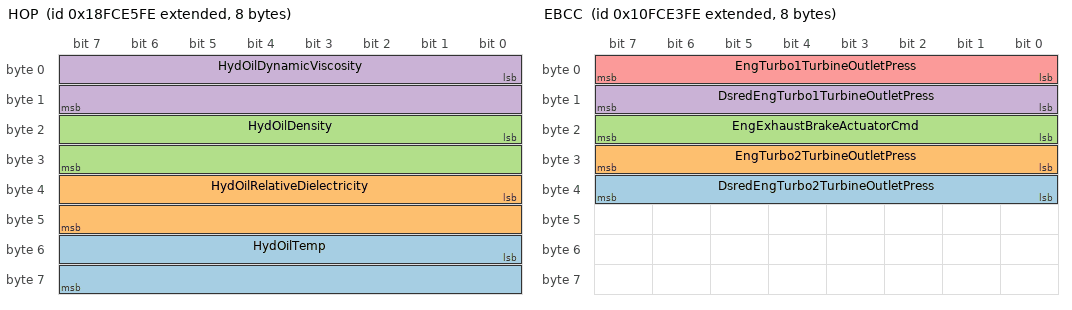
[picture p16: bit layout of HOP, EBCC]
BO_ 2566710782 HOP: 8 Vector__XXX
 SG_ HydOilTemp : 48|16@1+ (0.03125,-273) [-273|1734.96875] "deg C" Vector__XXX
 SG_ HydOilRelativeDielectricity : 32|16@1+ (0.0001220703125,0) [0|7.844] "" Vector__XXX
 SG_ HydOilDensity : 16|16@1+ (3.052E-005,0) [0|1.961] "g/cc" Vector__XXX
 SG_ HydOilDynamicViscosity : 0|16@1+ (0.015625,0) [0|1003.984375] "Cp" Vector__XXX

BO_ 2566710526 EFP: 8 Vector__XXX
 SG_ EngFuelTemp : 48|16@1+ (0.03125,-273) [-273|1734.96875] "deg C" Vector__XXX
 SG_ EngFuelDielectricity : 32|16@1+ (0.0001220703125,0) [0|7.844] "" Vector__XXX
 SG_ EngFuelDensity : 16|16@1+ (3.052E-005,0) [0|1.961] "g/cc" Vector__XXX
 SG_ EngFuelDynamicViscosity : 0|16@1+ (0.015625,0) [0|1003.984375] "Cp" Vector__XXX

BO_ 2432492542 EBCC: 8 Vector__XXX
 SG_ DsredEngTurbo2TurbineOutletPress : 32|8@1+ (2,0) [0|500] "kPa" Vector__XXX
 SG_ EngTurbo2TurbineOutletPress : 24|8@1+ (2,0) [0|500] "kPa" Vector__XXX
 SG_ EngExhaustBrakeActuatorCmd : 16|8@1+ (0.4,0) [0|100] "%" Vector__XXX
 SG_ DsredEngTurbo1TurbineOutletPress : 8|8@1+ (2,0) [0|500] "kPa" Vector__XXX
 SG_ EngTurbo1TurbineOutletPress : 0|8@1+ (2,0) [0|500] "kPa" Vector__XXX

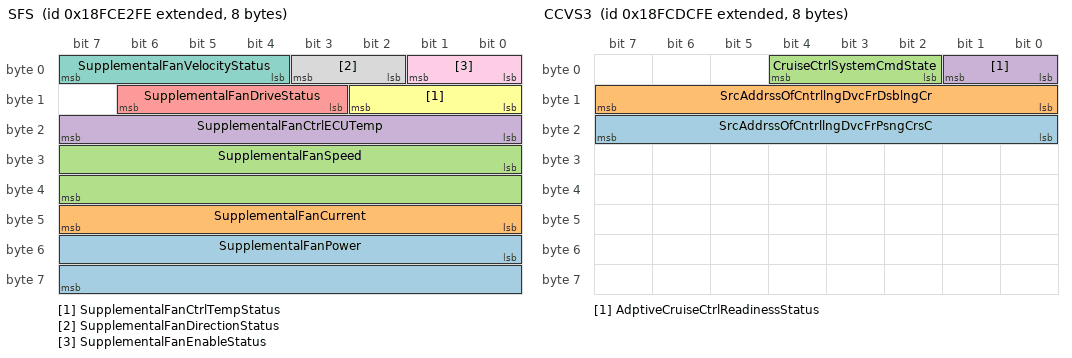
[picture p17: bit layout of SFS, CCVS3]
BO_ 2566710014 SFS: 8 Vector__XXX
 SG_ SupplementalFanPower : 48|16@1+ (0.5,0) [0|32127.5] "W" Vector__XXX
 SG_ SupplementalFanCurrent : 40|8@1+ (1,-125) [-125|125] "A" Vector__XXX
 SG_ SupplementalFanSpeed : 24|16@1+ (0.5,0) [0|32127.5] "rpm" Vector__XXX
 SG_ SupplementalFanCtrlECUTemp : 16|8@1+ (1,-40) [-40|210] "deg C" Vector__XXX
 SG_ SupplementalFanDriveStatus : 11|4@1+ (1,0) [0|15] "" Vector__XXX
 SG_ SupplementalFanCtrlTempStatus : 8|3@1+ (1,0) [0|7] "" Vector__XXX
 SG_ SupplementalFanVelocityStatus : 4|4@1+ (1,0) [0|15] "" Vector__XXX
 SG_ SupplementalFanDirectionStatus : 2|2@1+ (1,0) [0|3] "" Vector__XXX
 SG_ SupplementalFanEnableStatus : 0|2@1+ (1,0) [0|3] "" Vector__XXX

BO_ 2566709758 LFE2: 8 Vector__XXX
 SG_ HighResolutionEngFuelRate : 0|32@1+ (0.001,0) [0|4211081.215] "L/h" Vector__XXX

BO_ 2566709502 DPFC2: 8 Vector__XXX
 SG_ Aftertreatment2FuelMassRate : 48|16@1+ (0.05,0) [0|3212.75] "g/m" Vector__XXX
 SG_ Aftertreatment1FuelMassRate : 32|16@1+ (0.05,0) [0|3212.75] "g/m" Vector__XXX
 SG_ RelativeUnburnedFuelMassFromEng : 16|16@1+ (0.0025,0) [0|160.6375] "%" Vector__XXX
 SG_ Aftrtrtmnt1DslPrtcltFltrIntkTmpS : 0|16@1+ (0.03125,-273) [-273|1734.96875] "deg C" Vector__XXX

BO_ 2566709246 EFL_P12: 8 Vector__XXX
 SG_ EngFuelFilterDegradation : 24|8@1+ (1,0) [0|250] "%" Vector__XXX
 SG_ EngFilteredFuelDeliveryAbsPress : 16|8@1+ (4,0) [0|1000] "kPa" Vector__XXX
 SG_ EngFilteredFuelDeliveryPress : 8|8@1+ (4,0) [0|1000] "kPa" Vector__XXX
 SG_ EngFuelDeliveryAbsPress : 0|8@1+ (4,0) [0|1000] "kPa" Vector__XXX

BO_ 2566708990 AT1AC3: 8 Vector__XXX
 SG_ Aftertreatment1SecondAirAbsPress : 0|16@1+ (0.1,0) [0|6425.5] "kPa" Vector__XXX

BO_ 2566708734 AT2AC3: 8 Vector__XXX
 SG_ Aftertreatment2SecondAirAbsPress : 0|16@1+ (0.1,0) [0|6425.5] "kPa" Vector__XXX

BO_ 2566708478 CCVS3: 8 Vector__XXX
 SG_ SrcAddrssOfCntrllngDvcFrPsngCrsC : 16|8@1+ (1,0) [0|255] "" Vector__XXX
 SG_ SrcAddrssOfCntrllngDvcFrDsblngCr : 8|8@1+ (1,0) [0|255] "" Vector__XXX
 SG_ CruiseCtrlSystemCmdState : 2|3@1+ (1,0) [0|7] "" Vector__XXX
 SG_ AdptiveCruiseCtrlReadinessStatus : 0|2@1+ (1,0) [0|3] "" Vector__XXX

BO_ 2566708222 AT1DPF1S3: 8 Vector__XXX
 SG_ Aftrtrtmnt1DslPrtcltFltr1StS5635 : 48|16@1+ (0.1,0) [0|6425.5] "MHz" Vector__XXX
 SG_ Aftrtrtmnt1DslPrtcltFltr1StS5634 : 32|16@1+ (0.1,0) [0|6425.5] "MHz" Vector__XXX
 SG_ Aftrtrtmnt1DslPrtcltFltr1StS5633 : 16|16@1+ (0.1,0) [0|6425.5] "MHz" Vector__XXX
 SG_ Aftrtrtmnt1DslPrtcltFltr1StSnsrA : 0|16@1+ (0.1,0) [0|6425.5] "MHz" Vector__XXX

BO_ 2566707966 AT1DPF1S4: 8 Vector__XXX
 SG_ Aftrtrtmnt1DslPrtcltFltr1StS5639 : 48|16@1+ (0.0025,0) [0|160.6375] "%" Vector__XXX
 SG_ Aftrtrtmnt1DslPrtcltFltr1StS5638 : 32|16@1+ (0.1,0) [0|6425.5] "MHz" Vector__XXX
 SG_ Aftrtrtmnt1DslPrtcltFltr1StSnsrF : 16|16@1+ (0.0025,0) [0|160.6375] "%" Vector__XXX
 SG_ Aftrtrtmnt1DslPrtcltFltr1StSnsrA : 0|16@1+ (0.1,0) [0|6425.5] "MHz" Vector__XXX

BO_ 2566707710 AT1DPF1S5: 8 Vector__XXX
 SG_ Aftrtrtmnt1DslPrtcltFltr1StS5643 : 48|16@1+ (0.0025,0) [0|160.6375] "%" Vector__XXX
 SG_ Aftrtrtmnt1DslPrtcltFltr1StS5642 : 32|16@1+ (0.1,0) [0|6425.5] "MHz" Vector__XXX
 SG_ Aftrtrtmnt1DslPrtcltFltr1StSnsrF : 16|16@1+ (0.0025,0) [0|160.6375] "%" Vector__XXX
 SG_ Aftrtrtmnt1DslPrtcltFltr1StSnsrA : 0|16@1+ (0.1,0) [0|6425.5] "MHz" Vector__XXX

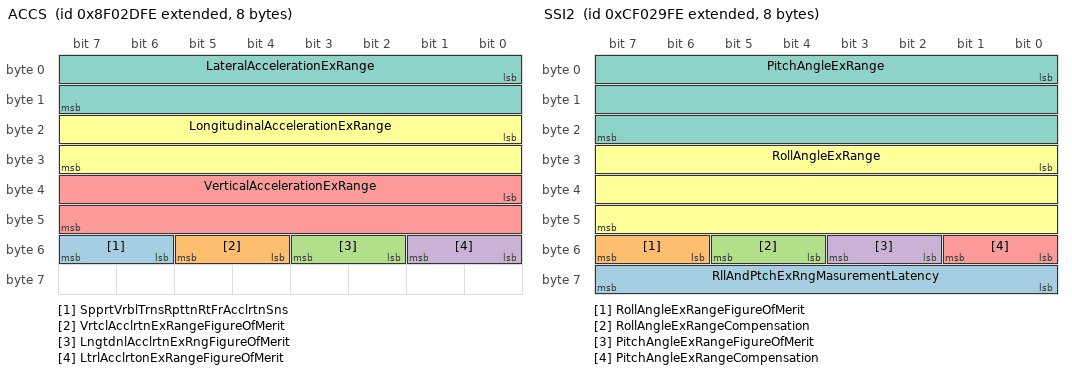
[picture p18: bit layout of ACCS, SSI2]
BO_ 2297441790 ACCS: 8 Vector__XXX
 SG_ SpprtVrblTrnsRpttnRtFrAcclrtnSns : 54|2@1+ (1,0) [0|3] "" Vector__XXX
 SG_ VrtclAcclrtnExRangeFigureOfMerit : 52|2@1+ (1,0) [0|3] "" Vector__XXX
 SG_ LngtdnlAcclrtnExRngFigureOfMerit : 50|2@1+ (1,0) [0|3] "" Vector__XXX
 SG_ LtrlAcclrtonExRangeFigureOfMerit : 48|2@1+ (1,0) [0|3] "" Vector__XXX
 SG_ VerticalAccelerationExRange : 32|16@1+ (0.01,-320) [-320|322.55] "m/s²" Vector__XXX
 SG_ LongitudinalAccelerationExRange : 16|16@1+ (0.01,-320) [-320|322.55] "m/s²" Vector__XXX
 SG_ LateralAccelerationExRange : 0|16@1+ (0.01,-320) [-320|322.55] "m/s²" Vector__XXX

BO_ 2566712062 VEP4: 8 Vector__XXX
 SG_ HybridBatteryPackRemainingCharge : 0|16@1+ (0.0025,0) [0|160.6375] "%" Vector__XXX

BO_ 2364549630 SSI2: 8 Vector__XXX
 SG_ RllAndPtchExRngMasurementLatency : 56|8@1+ (0.5,0) [0|125] "ms" Vector__XXX
 SG_ RollAngleExRangeFigureOfMerit : 54|2@1+ (1,0) [0|3] "" Vector__XXX
 SG_ RollAngleExRangeCompensation : 52|2@1+ (1,0) [0|3] "" Vector__XXX
 SG_ PitchAngleExRangeFigureOfMerit : 50|2@1+ (1,0) [0|3] "" Vector__XXX
 SG_ PitchAngleExRangeCompensation : 48|2@1+ (1,0) [0|3] "" Vector__XXX
 SG_ RollAngleExRange : 24|24@1+ (3.0517578125E-005,-250) [-250|250.9999] "deg" Vector__XXX
 SG_ PitchAngleExRange : 0|24@1+ (3.0517578125E-005,-250) [-250|250.9999] "deg" Vector__XXX

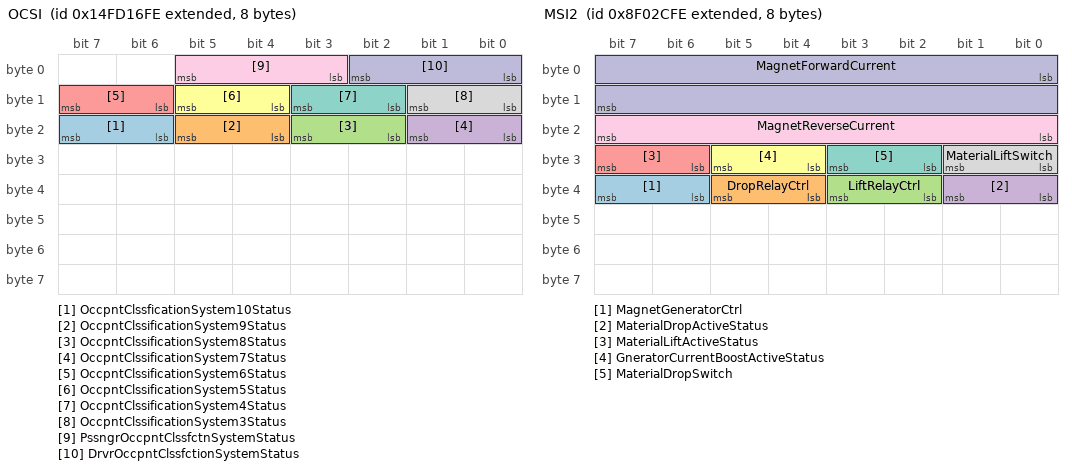
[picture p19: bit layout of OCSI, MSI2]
BO_ 2499614462 OCSI: 8 Vector__XXX
 SG_ OccpntClssficationSystem10Status : 22|2@1+ (1,0) [0|3] "" Vector__XXX
 SG_ OccpntClssificationSystem9Status : 20|2@1+ (1,0) [0|3] "" Vector__XXX
 SG_ OccpntClssificationSystem8Status : 18|2@1+ (1,0) [0|3] "" Vector__XXX
 SG_ OccpntClssificationSystem7Status : 16|2@1+ (1,0) [0|3] "" Vector__XXX
 SG_ OccpntClssificationSystem6Status : 14|2@1+ (1,0) [0|3] "" Vector__XXX
 SG_ OccpntClssificationSystem5Status : 12|2@1+ (1,0) [0|3] "" Vector__XXX
 SG_ OccpntClssificationSystem4Status : 10|2@1+ (1,0) [0|3] "" Vector__XXX
 SG_ OccpntClssificationSystem3Status : 8|2@1+ (1,0) [0|3] "" Vector__XXX
 SG_ PssngrOccpntClssfctnSystemStatus : 3|3@1+ (1,0) [0|7] "" Vector__XXX
 SG_ DrvrOccpntClssfctionSystemStatus : 0|3@1+ (1,0) [0|7] "" Vector__XXX

BO_ 2560098046 NCS: 8 Vector__XXX
 SG_ CabNoiseCtrlTuningStatus : 2|4@1+ (1,0) [0|15] "" Vector__XXX
 SG_ CabNoiseCtrlStatus : 0|2@1+ (1,0) [0|3] "" Vector__XXX

BO_ 2560163582 NC1: 8 Vector__XXX
 SG_ CabNoiseCtrlTuningCmd : 2|3@1+ (1,0) [0|7] "" Vector__XXX
 SG_ CabNoiseCtrlCmd : 0|2@1+ (1,0) [0|3] "" Vector__XXX

BO_ 2297441534 MSI2: 8 Vector__XXX
 SG_ MagnetGeneratorCtrl : 38|2@1+ (1,0) [0|3] "" Vector__XXX
 SG_ DropRelayCtrl : 36|2@1+ (1,0) [0|3] "" Vector__XXX
 SG_ LiftRelayCtrl : 34|2@1+ (1,0) [0|3] "" Vector__XXX
 SG_ MaterialDropActiveStatus : 32|2@1+ (1,0) [0|3] "" Vector__XXX
 SG_ MaterialLiftActiveStatus : 30|2@1+ (1,0) [0|3] "" Vector__XXX
 SG_ GneratorCurrentBoostActiveStatus : 28|2@1+ (1,0) [0|3] "" Vector__XXX
 SG_ MaterialDropSwitch : 26|2@1+ (1,0) [0|3] "" Vector__XXX
 SG_ MaterialLiftSwitch : 24|2@1+ (1,0) [0|3] "" Vector__XXX
 SG_ MagnetReverseCurrent : 16|8@1+ (1,0) [0|250] "A" Vector__XXX
 SG_ MagnetForwardCurrent : 0|16@1+ (1,0) [0|64255] "Amps" Vector__XXX

CM_ BO_ 3221225472 "This is a message for not used signals, created by Vector CANdb++ DBC OLE DB Provider.";
CM_ SG_ 3221225472 AETCTorqueValue "Engine torque value of the data points in PGN 64912 – Advertised Engine Torque Curve (AETC).";
CM_ SG_ 3221225472 TrailerWeight "Total mass of freight-carrying vehicle designed to be pulled by truck, including the weight of the contents.";
CM_ SG_ 3221225472 ReferenceTirePressSetting "Reference value of the tire pressure setting as basis for the tire pressure monitoring ...";
CM_ SG_ 3221225472 ReferenceTirePress "Reference value of the tire pressure as basis for the tire pressure monitoring ...";
CM_ SG_ 3221225472 TirePressThresholdDetection "Signal indicating the pressure level of the tire.  The levels defined represent different pressure conditions of the tire: 000 Extreme over pressure - The tire pressure is at a level where the safety of the vehicle may be jeopardised.";
CM_ SG_ 3221225472 TireAirLeakageRate "The pressure loss rate of a tire.";
CM_ SG_ 3221225472 CTIWheelEndElectricalFault "Indicates the status of electrical fault on CTI wheel interface.";
CM_ SG_ 3221225472 CTITireStatus "Indicates the status of the tire.";
CM_ SG_ 3221225472 CTIWheelSensorStatus "Indicates whether the wheel is being monitored by the CTI controller.";
CM_ SG_ 3221225472 TireTemp "Temperature at the surface of the tire sidewall.";
CM_ SG_ 3221225472 TirePress "Pressure at which air is contained in cavity formed by tire and rim.";
CM_ SG_ 3221225472 EngTurningGearEngaged "Status signal which indicates that the turning gear is engaged.  The turning gear is used to turn the flywheel/crankshaft, ...";
CM_ SG_ 3221225472 AETCSpeedValue "Engine speed value of the data points in PGN 64912 – Advertised Engine Torque Curve (AETC).";
CM_ SG_ 3221225472 FlashRedStopLamp "This parameter provides the capability to flash the RSL (SPN 3039).This parameter provides the capability to flash the RSL (SPN 3039).";
CM_ SG_ 3221225472 FlashProtectLamp "This parameter provides the capability to flash the engine protect lamp (SPN 3041).This parameter provides the capability to flash the engine protect lamp (SPN 3041).";
CM_ SG_ 3221225472 FlashMalfuncIndicatorLamp "This parameter provides the capability to flash the MIL (SPN 3038).This parameter provides the capability to flash the MIL (SPN 3038).";
CM_ SG_ 3221225472 FlashAmberWarningLamp "This parameter provides the capability to flash the AWL (SPN 3040). This parameter provides the capability to flash the AWL (SPN 3040). ";
CM_ SG_ 3221225472 MalfunctionIndicatorLampStatus "A lamp used to relay only emissions-related trouble code information.A lamp used to relay only emissions-related trouble code information.";
CM_ SG_ 3221225472 AmberWarningLampStatus "This lamp is used to relay trouble code information that is reporting a problem with the vehicle system but the vehicle need
not be immediately stopped.This lamp is used to relay trouble code information that is reporting a problem with the vehicle system but the vehicle need
not be immediately stopped.";
CM_ SG_ 3221225472 RedStopLampState "This lamp is uesed to relay trouble code information that is of a severe enought condition that it warrants stopping the vehicle.This lamp is uesed to relay trouble code information that is of a severe enought condition that it warrants stopping the vehicle.";
CM_ SG_ 3221225472 ProtectLampStatus "This lamp is used to relay trouble code informatio that is reporting a problem with a vehicle system that is most
probably not electronic subsystem related.This lamp is used to relay trouble code informatio that is reporting a problem with a vehicle system that is most
probably not electronic subsystem related.";
CM_ SG_ 3221225472 DTC5 "Diagnostic Trouble CodeDiagnostic Trouble CodeDiagnostic Trouble CodeDiagnostic Trouble Code";
CM_ SG_ 3221225472 DTC4 "Diagnostic Trouble CodeDiagnostic Trouble CodeDiagnostic Trouble CodeDiagnostic Trouble Code";
CM_ SG_ 3221225472 DTC3 "Diagnostic Trouble CodeDiagnostic Trouble CodeDiagnostic Trouble CodeDiagnostic Trouble Code";
CM_ SG_ 3221225472 DTC2 "Diagnostic Trouble CodeDiagnostic Trouble CodeDiagnostic Trouble CodeDiagnostic Trouble Code";
CM_ SG_ 3221225472 DTC1 "Diagnostic Trouble CodeDiagnostic Trouble Code";
CM_ BO_ 2566834691 "Active diagnostic trouble codes";
CM_ SG_ 2566834691 FlashRedStopLamp "This parameter provides the capability to flash the RSL (SPN 3039).";
CM_ SG_ 2566834691 FlashProtectLamp "This parameter provides the capability to flash the engine protect lamp (SPN 3041).";
CM_ SG_ 2566834691 FlashMalfuncIndicatorLamp "This parameter provides the capability to flash the MIL (SPN 3038).";
CM_ SG_ 2566834691 FlashAmberWarningLamp "This parameter provides the capability to flash the AWL (SPN 3040). ";
CM_ SG_ 2566834691 MalfunctionIndicatorLampStatus "A lamp used to relay only emissions-related trouble code information.";
CM_ SG_ 2566834691 AmberWarningLampStatus "This lamp is used to relay trouble code information that is reporting a problem with the vehicle system but the vehicle need
not be immediately stopped.";
CM_ SG_ 2566834691 RedStopLampState "This lamp is uesed to relay trouble code information that is of a severe enought condition that it warrants stopping the vehicle.";
CM_ SG_ 2566834691 ProtectLampStatus "This lamp is used to relay trouble code informatio that is reporting a problem with a vehicle system that is most
probably not electronic subsystem related.";
CM_ SG_ 2566834691 DTC1 "Diagnostic Trouble Code";
CM_ BO_ 2566834699 "Active diagnostic trouble codes";
CM_ SG_ 2566834699 FlashRedStopLamp "This parameter provides the capability to flash the RSL (SPN 3039).";
CM_ SG_ 2566834699 FlashProtectLamp "This parameter provides the capability to flash the engine protect lamp (SPN 3041).";
CM_ SG_ 2566834699 FlashMalfuncIndicatorLamp "This parameter provides the capability to flash the MIL (SPN 3038).";
CM_ SG_ 2566834699 FlashAmberWarningLamp "This parameter provides the capability to flash the AWL (SPN 3040). ";
CM_ SG_ 2566834699 MalfunctionIndicatorLampStatus "A lamp used to relay only emissions-related trouble code information.";
CM_ SG_ 2566834699 AmberWarningLampStatus "This lamp is used to relay trouble code information that is reporting a problem with the vehicle system but the vehicle need
not be immediately stopped.";
CM_ SG_ 2566834699 RedStopLampState "This lamp is uesed to relay trouble code information that is of a severe enought condition that it warrants stopping the vehicle.";
CM_ SG_ 2566834699 ProtectLampStatus "This lamp is used to relay trouble code informatio that is reporting a problem with a vehicle system that is most
probably not electronic subsystem related.";
CM_ SG_ 2566834699 DTC1 "Diagnostic Trouble Code";
CM_ BO_ 2566834688 "Active diagnostic trouble codes";
CM_ SG_ 2566834688 FlashRedStopLamp "This parameter provides the capability to flash the RSL (SPN 3039).";
CM_ SG_ 2566834688 FlashProtectLamp "This parameter provides the capability to flash the engine protect lamp (SPN 3041).";
CM_ SG_ 2566834688 FlashMalfuncIndicatorLamp "This parameter provides the capability to flash the MIL (SPN 3038).";
CM_ SG_ 2566834688 FlashAmberWarningLamp "This parameter provides the capability to flash the AWL (SPN 3040). ";
CM_ SG_ 2566834688 MalfunctionIndicatorLampStatus "A lamp used to relay only emissions-related trouble code information.";
CM_ SG_ 2566834688 AmberWarningLampStatus "This lamp is used to relay trouble code information that is reporting a problem with the vehicle system but the vehicle need
not be immediately stopped.";
CM_ SG_ 2566834688 RedStopLampState "This lamp is uesed to relay trouble code information that is of a severe enought condition that it warrants stopping the vehicle.";
CM_ SG_ 2566834688 ProtectLampStatus "This lamp is used to relay trouble code informatio that is reporting a problem with a vehicle system that is most
probably not electronic subsystem related.";
CM_ SG_ 2566834688 DTC1 "Diagnostic Trouble Code";
CM_ SG_ 2566910720 WaterInFuelIndicator "Signal which indicates the presence of water in the fuel.";
CM_ BO_ 2566805053 "Contains information on various tank levels ...";
CM_ SG_ 2566805053 Aftrtrtmnt1DslExhstFlidTankLevel "Ratio of volume of diesel exhaust fluid to the total volume of diesel exhaust fluid storage container.";
CM_ BO_ 2566804992 "Contains information on various tank levels ...";
CM_ SG_ 2566804992 Aftrtrtmnt1DslExhstFlidTankLevel "Ratio of volume of diesel exhaust fluid to the total volume of diesel exhaust fluid storage container.";
CM_ BO_ 2566844160 "PGN which identifies parameters that are either measuring various pressures within the engine or identifying engine fluid ...";
CM_ SG_ 2566844160 EngCoolantLevel "Ratio of volume of liquid found in engine cooling system to total cooling system volume.  Typical monitoring location is in ...";
CM_ SG_ 2566844160 EngCoolantPress "Gage pressure of liquid found in engine cooling system.";
CM_ SG_ 2566844160 EngCrankcasePress "Gage pressure inside engine crankcase.";
CM_ SG_ 2566844160 EngOilPress "Gage pressure of oil in engine lubrication system as provided by oil pump.";
CM_ SG_ 2566844160 EngOilLevel "Ratio of current volume of engine sump oil to maximum required volume.";
CM_ SG_ 2566844160 EngExCrankcaseBlowbyPress "Differential crankcase blow-by pressure as measured through a tube with a venturi.";
CM_ SG_ 2566844160 EngFuelDeliveryPress "Gage pressure of fuel in system as delivered from supply pump to the injection pump.  See also SPN 5578 for Fuel ...";
CM_ SG_ 2566843904 EngIntercoolerThermostatOpening "The current position of the thermostat used to regulate the temperature of the engine intercooler.  A value of 0% ...";
CM_ SG_ 2566843904 EngIntercoolerTemp "Temperature of liquid found in the intercooler located after the turbocharger.";
CM_ SG_ 2566843904 EngTurboOilTemp "Temperature of the turbocharger lubricant.";
CM_ SG_ 2566843904 EngOilTemp1 "Temperature of the engine lubricant.";
CM_ SG_ 2566843904 EngFuelTemp1 "Temperature of fuel (or gas) passing through the first fuel control system.  See SPN 3468 for the second control system ...";
CM_ SG_ 2566843904 EngCoolantTemp "Temperature of liquid found in engine cooling system.";
CM_ BO_ 2566844672 "Cruise Control/Vehicle Speed 1 ...";
CM_ SG_ 2566844672 EngShutdownOverrideSwitch "Switch signal which indicates the position of the engine shutdown override switch.  This switch function allows the ...";
CM_ SG_ 2566844672 EngTestModeSwitch "Switch signal which indicates the position of the engine test mode switch.";
CM_ SG_ 2566844672 EngIdleDecrementSwitch "Switch signal which indicates the position of the idle decrement switch.";
CM_ SG_ 2566844672 EngIdleIncrementSwitch "Switch signal which indicates the position of the idle increment switch.";
CM_ SG_ 2566844672 CruiseCtrlStates "This parameter is used to indicate the current state, or mode, of operation by the cruise control device.  This is a status ...";
CM_ SG_ 2566844672 PTOGovernorState "This parameter is used to indicate the current state or mode of operation by the power takeoff (PTO) governor.  In lieu of ...";
CM_ SG_ 2566844672 CruiseCtrlSetSpeed "Value of set (chosen) velocity of velocity control system.";
CM_ SG_ 2566844672 CruiseCtrlAccelerateSwitch "Switch signal of the cruise control activator which indicates that the activator is in the position “accelerate.” ...";
CM_ SG_ 2566844672 CruiseCtrlResumeSwitch "Switch signal of the cruise control activator which indicates that the activator is in the position “resume.” ...";
CM_ SG_ 2566844672 CruiseCtrlCoastSwitch "Switch signal of the cruise control activator which indicates that the activator is in the position “coast (decelerate).” ...";
CM_ SG_ 2566844672 CruiseCtrlSetSwitch "Switch signal of the cruise control activator which indicates that the activator is in the position “set.” ...";
CM_ SG_ 2566844672 ClutchSwitch "Switch signal which indicates that the clutch pedal is being pressed. It is necessary for a safe drivetrain behavior that the ...";
CM_ SG_ 2566844672 BrakeSwitch "Switch signal which indicates that the driver operated brake foot pedal is being pressed.  This brake foot pedal is ...";
CM_ SG_ 2566844672 CruiseCtrlEnableSwitch "Switch signal which indicates that it is possible to manage the cruise control function.";
CM_ SG_ 2566844672 CruiseCtrlActive "Cruise control is switched on.  It is not ensured that the engine is controlled by cruise control, as in the case of a large ...";
CM_ SG_ 2566844672 WheelBasedVehicleSpeed "Speed of the vehicle as calculated from wheel or tailshaft speed.";
CM_ SG_ 2566844672 ParkBrakeReleaseInhibitRq "Park Brake Release Inhibit Request signals the desire that an applied park brake remain applied and limit the ability of the ...";
CM_ SG_ 2566844672 CruiseCtrlPauseSwitch "Switch signal which indicates the position of the Cruise Control Pause Switch used on Remote Cruise Control ...";
CM_ SG_ 2566844672 ParkingBrakeSwitch "Switch signal which indicates when the parking brake is set. In general the switch actuated by the operator's park brake ...";
CM_ SG_ 2566844672 TwoSpeedAxleSwitch "Switch signal which indicates the current axle range.";
CM_ SG_ 2566841344 ClntLvlEngPrtctionShutdownStatus "Parameter which indicates the configuration of the coolant level engine protection shutdown.";
CM_ SG_ 2566841344 PTOShutdownHasShutdownEng "Status signal which identifies whether or not the engine has been shutdown by the PTO shutdown system.";
CM_ SG_ 2566841344 EngAirShutoffStatus "State signal which indicates the actual measured position of the Air Shutoff.";
CM_ SG_ 2566841344 EngOverspeedTest "The engine overspeed test signal as measured by the reporting ECM.  Engine Overspeed Test is a mechanism to ...";
CM_ SG_ 2566841344 EngAirShutoffCmdStatus "State signal which indicates when the Air Shutoff  driver output is being driven. Disabled means controller wants air ...";
CM_ SG_ 2566841344 EngAlarmOutputCmdStatus "State signal which indicates when the Alarm driver output is being driven. Not active means the Controller has no alarm ...";
CM_ SG_ 2566841344 EngAlarmAcknowledge "The Engine Alarm Acknowledge Input signal as measured by the reporting ECM.  The Engine Alarm Acknowledge is a ...";
CM_ SG_ 2566841344 EngProtectionSystemConfig "Parameter which indicates the configuration of the engine shutdown system.";
CM_ SG_ 2566841344 EngProtectionSystemTimerState "Status signal which indicates the current mode of the engine protection system timer system.  See Figure SPN1107_A.";
CM_ SG_ 2566841344 EngProtectionSystemTimerOverride "Status signal which indicates the status of the override feature of the engine protection system timer. See Figure ...";
CM_ SG_ 2566841344 EngPrtctnSystmApprachingShutdown "Status signal which indicates that engine shutdown is imminent.  This engine protection signal can be a result of different ...";
CM_ SG_ 2566841344 EngPrtectionSystemHasShutdownEng "Status signal which indicates whether or not the engine protection system has shutdown the engine.  See Figure ...";
CM_ SG_ 2566841344 EngWaitToStartLamp "Lamp signal which indicates that the engine is too cold to start and the operator should wait until the signal becomes ...";
CM_ SG_ 2566841344 RefrigerantHighPressSwitch "Switch signal which indicates the position of the high pressure switch in the coolant circuit of an air conditioning system.";
CM_ SG_ 2566841344 RefrigerantLowPressSwitch "Switch signal which indicates the position of the low pressure switch in the coolant circuit of an air conditioning system.";
CM_ SG_ 2566841344 A_CHighPressFanSwitch "Switch signal which indicates that the pressure in the coolant circuit of an air conditioning system is high and the fan may ...";
CM_ SG_ 2566841344 EngIdleShutdownTimerFunction "Parameter which indicates the configuration of the idle shutdown timer system.";
CM_ SG_ 2566841344 EngIdleShutdownTimerState "Status signal which indicates the current mode of operation of the idle shutdown timer system.  See Figure SPN590_A.";
CM_ SG_ 2566841344 EngIdleShutdownTimerOverride "Status signal which indicates the status of the override feature of the idle shutdown timer system.  See Figure SPN590_A.";
CM_ SG_ 2566841344 EngIdleShutdownDriverAlertMode "Status signal which indicates the status of the driver alert mode of the idle shutdown timer system.  While the driver alert ...";
CM_ SG_ 2566841344 EngIdleShutdownHasShutdownEng "Status signal which identifies whether or not the engine has been shutdown by the idle shutdown timer system.  See ...";
CM_ BO_ 2566803211 "Contains information which relates to the VDC system status.";
CM_ SG_ 2566803211 TrailerVDCActive "The trailer-VDC (Vehicle Dynamic Control) is an electronic vehicle stability function within the (semi) trailer braking ...";
CM_ SG_ 2566803211 YCBrakeCtrlActive "State signal which indicates that Yaw Control (YC) has activated brake control. Active means that YC actually controls ...";
CM_ SG_ 2566803211 YCEngCtrlActive "State Signal which indicates that the Yaw Control (YC) has commanded engine control to be active. Within the physical ...";
CM_ SG_ 2566803211 ROPBrakeCtrlActive "State signal which indicates that Roll over Prevention (ROP) has activated brake control. Active means that ROP actually ...";
CM_ SG_ 2566803211 ROPEngCtrlActive "State Signal which indicates that the Roll Over Prevention (ROP) has commanded engine control to be active. Within the ...";
CM_ SG_ 2566803211 VDCBrakeLightRq "Indicates whether VDC requests to turn the vehicle brake lights on ...";
CM_ SG_ 2566803211 VDCFullyOperational "Signal that indicates whether VDC is fully operational or whether its functionality is reduced by a permanent or temporary ...";
CM_ SG_ 2566803211 VDCInformationSignal "This parameter commands the VDC information signal, for example a dash lamp.";
CM_ BO_ 2566848256 "Water in Fuel Indicator";
CM_ SG_ 2566848256 EmssnCtrlSystmOprtrIndcmntSvrity "Severity status of the operator inducement system for anomalies with the emission control system, such as tampering, ...";
CM_ SG_ 2566848256 DrvrWarningSystemIndicatorStatus "The desired illumination of the Euro VI defined driver warning system indicator for relevant malfunctions and diesel ...";
CM_ SG_ 2566848256 OperatorShiftPrompt "Command to activate an indicator that advises the operator to shift to a different gear.  Typically this would be used as ...";
CM_ SG_ 2566848256 WaterInFuelIndicator "Signal which indicates the presence of water in the fuel.";
CM_ BO_ 2364539904 "Engine related parameters ...";
CM_ SG_ 2364539904 EngDemandPercentTorque "The requested torque output of the engine by all dynamic internal inputs, including smoke control, noise control and low ...";
CM_ SG_ 2364539904 EngStarterMode "There are several phases in a starting action and different reasons why a start cannot take place.";
CM_ SG_ 2364539904 SrcAddrssOfCntrllngDvcForEngCtrl "The source address of the SAE J1939 device currently controlling the engine.  It is used to expand the torque mode ...";
CM_ SG_ 2364539904 EngSpeed "Actual engine speed which is calculated over a minimum crankshaft angle of 720 degrees divided by the number of ...";
CM_ SG_ 2364539904 ActualEngPercentTorque "The calculated output torque of the engine.  The data is transmitted in indicated torque as a percent of reference engine ...";
CM_ SG_ 2364539904 DriversDemandEngPercentTorque "The requested torque output of the engine by the driver. It is based on input from the following requestors external to the ...";
CM_ SG_ 2364539904 ActlEngPrcntTorqueHighResolution "This parameter displays an additional torque in percent of the reference engine torque.";
CM_ SG_ 2364539904 EngTorqueMode "State signal which indicates which engine torque mode is currently generating, limiting, or controlling the torque.  Note ...";
CM_ BO_ 2559115006 "Message used to request the wireless transceiver to transmit a special beacon signal and to report ...";
CM_ SG_ 2559115006 WirelessSignalStrength2 "The absolute received signal strength of the special beacon signal received from the off-board transmitter. The signal ...";
CM_ SG_ 2559115006 TransmitterID2 "The ID of the off-board transmitter that sent the incoming special beacon message received by the wireless transceiver.";
CM_ SG_ 2559115006 RadioBeaconDirection "Indicates the function of a particular instance of the Radio Beacon Request message. The 'Beacon Request' state ...";
CM_ SG_ 2559115006 UnqBeaconMessageIdentifierNumber "The number is used to identify a wireless message originating from a device on a particular machine. Within a beacon ...";
CM_ BO_ 2566707454 "This message is used to specify up to 4 soot sensor analysis frequencies to request the soot sensor signal data ...";
CM_ SG_ 2566707454 Aftrtrtmnt1DslPrtcltFltr2StS5647 "Fourth requested analysis frequency for the diesel particulate filter 2 soot sensor.";
CM_ SG_ 2566707454 Aftrtrtmnt1DslPrtcltFltr2StS5646 "Third requested analysis frequency for the diesel particulate filter 2 soot sensor.";
CM_ SG_ 2566707454 Aftrtrtmnt1DslPrtcltFltr2StS5645 "Second requested analysis frequency for the diesel particulate filter 2 soot sensor.";
CM_ SG_ 2566707454 Aftrtrtmnt1DslPrtcltFltr2StSnsrA "First requested analysis frequency for the diesel particulate filter 2 soot sensor.";
CM_ BO_ 2566707198 "This message is used report the analysis frequency and associated soot sensor signal data for two of the requested ...";
CM_ SG_ 2566707198 Aftrtrtmnt1DslPrtcltFltr2StS5651 "The soot signal attenuation measurement for analysis frequency 2 for the diesel particulate filter 2 soot sensor.  See SPN ...";
CM_ SG_ 2566707198 Aftrtrtmnt1DslPrtcltFltr2StS5650 "The analysis frequency associated with the frequency 2 soot signal for the diesel particulate filter 2 soot sensor.  See ...";
CM_ SG_ 2566707198 Aftrtrtmnt1DslPrtcltFltr2StSnsrF "The soot signal attenuation measurement for analysis frequency 1 for the diesel particulate filter 2 soot sensor.  See SPN ...";
CM_ SG_ 2566707198 Aftrtrtmnt1DslPrtcltFltr2StSnsrA "The analysis frequency associated with the frequency 1 soot signal for the diesel particulate filter 2 soot sensor.  See ...";
CM_ BO_ 2566706942 "Diesel particulate filter soot parameters for the aftertreatment 1 diesel particulate filter 2.";
CM_ SG_ 2566706942 Aftrtrtmnt1DslPrtcltFltr2StS5655 "The soot signal attenuation measurement for analysis frequency 4 for the diesel particulate filter 2 soot sensor.  See SPN ...";
CM_ SG_ 2566706942 Aftrtrtmnt1DslPrtcltFltr2StS5654 "The analysis frequency associated with the frequency 4 soot signal for the diesel particulate filter 2 soot sensor.  See ...";
CM_ SG_ 2566706942 Aftrtrtmnt1DslPrtcltFltr2StSnsrF "The soot signal attenuation measurement for analysis frequency 3 for the diesel particulate filter 2 soot sensor.  See SPN ...";
CM_ SG_ 2566706942 Aftrtrtmnt1DslPrtcltFltr2StSnsrA "The analysis frequency associated with the frequency 3 soot signal for the diesel particulate filter 2 soot sensor.  See ...";
CM_ BO_ 2559770366 "This PGN contains information about the HC Doser and the Diesel Particulate Filter ...";
CM_ SG_ 2559770366 HydrocarbonDoserPurgingRequired "Purging of the Hydrocarbon Doser (HCD) is required.  Request could come from the HCD system.";
CM_ SG_ 2559770366 DiagnosticStatusOfHCDoser "Indicates whether an error is active in the Hydrocarbon Doser (HCD) or whether the internal cyclic system test of the HCD ...";
CM_ SG_ 2559770366 HCDoserInjectingStatus "Indicates whether the Hydrocarbon Doser (HCD) is presently injecting diesel fuel into the exhaust pipe.";
CM_ SG_ 2559770366 HCDoserStatus "Indicates whether the HC Doser/ HC Dosing system is enabled or is waiting for regeneration.";
CM_ SG_ 2559770366 RequestedFuelMassRate "Requested fuel dosing quantity from hydrocarbon doser.";
CM_ BO_ 2559704830 "Used to command a vehicle/chassis lubrication system ...";
CM_ SG_ 2559704830 LubricationTimingCycleCmd "Command signal to enable or pause the lubrication activation clock ...";
CM_ SG_ 2559704830 LubricationPumpEnableCmd "Command signal to reset the lubrication pump.  It allows the operator and/or technician to reset the paused lubrication ...";
CM_ SG_ 2559704830 LubricationOperationModeSetCmd "Command signal to change lubrication system operational mode. The mode set command gives the operator and/or ...";
CM_ SG_ 2559704830 LubricationCycleSetCmd "Command signal to change the lubrication cycle. It gives the operator or technician the ability to the change the frequency ...";
CM_ SG_ 2559704830 LubricationCycleModeLockCmd "Command signal to lock or unlock the ability to change the lubrication cycle mode.  Locking the lubrication mode would ...";
CM_ BO_ 2559639294 "Command message to control the speed and direction of Supplemental Fan for additional cooling beyond that of the ...";
CM_ SG_ 2559639294 SupplementalFanPowerHold "Command to allow the supplemental fan controller to remain alive independently of the electrical enable input to the fan.";
CM_ SG_ 2559639294 SupplementalFanSpeedCmd "Speed command to Supplemental Fan.";
CM_ SG_ 2559639294 SupplementalFanDirectionCmd "Direction command to the Supplemental Fan. Fan can be commanded to run forward or reverse.";
CM_ SG_ 2559639294 SupplementalFanEnableCmd "Enable/Disable command to Supplemental Fan.";
CM_ BO_ 2559573758 "This PGN contains parameters that are used to configure engine operation.";
CM_ SG_ 2559573758 ClntLvlEngPrtctnShtdwnOvrrideCmd "Overrides the engine protection shutdown functionality due to low coolant level.";
CM_ BO_ 2349530878 "Cruise Control / Vehicle Speed 2 ...";
CM_ SG_ 2349530878 CruiseCtrlPauseCmd "This parameter is used to temporarily disable cruise control from a source other than the driver controlled switch if cruise ...";
CM_ SG_ 2349530878 CruiseCtrlResumeCmd "This parameter is used to request the cruise control to resume operation from a source other than the driver controlled ...";
CM_ SG_ 2349530878 CruiseCtrlDisableCmd "This parameter is used to disable cruise control from a source other than the driver controlled switch if cruise control is ...";
CM_ BO_ 2365428734 "Message for the generator set control to change or report the status of the generator system.";
CM_ SG_ 2365428734 GenFrequencySelection "Command  from  user  and/or  generator  control  system  for  the  genset (engine) to target operations for 50 Hz, 60 Hz, or 400 Hz.";
CM_ SG_ 2365428734 GenGoverningSpeedCommand "Command from user and/or generator control system for the genset (engine) to govern to low idle or rated base speed setpoints.";
CM_ SG_ 2365428734 GenAlternatorEfficiency "Measured,  calculated,  and/or  estimated  operating  efficiency  of  the  generator  alternator.";
CM_ SG_ 2365428734 GenNotReadyToAutoParaState "This parameter indicates whether or not all systems required to start the engine and close to the bus are prepared to operate automatically.";
CM_ SG_ 2365428734 GenCtrlNotInAutoStartState "This parameter indicates whether or not the generator set is in a condition to automatically start up and provide power.";
CM_ SG_ 2365428734 RequestedEngineControlMode "This parameter is used to request a change to the engine control mode.";
CM_ SG_ 2365428734 EngSpeedGovernorDroop "This is the percent speed droop adjustment relative to rated speed setpoint. The Engine Speed Droop is equal to the ...";
CM_ SG_ 2365428734 EngSpeedGovernorGainAdjust "This parameter is used to adjust multiple gains at same time to attain engine stability across a broader range of ...";
CM_ BO_ 2566702846 "OBD Information.";
CM_ SG_ 2566702846 EngOBDWarmUpSequence "Engine warm-up as defined by the applicable region's regulatory agency.";
CM_ BO_ 2566703102 "Model Year and Certification Engine Family.";
CM_ SG_ 2566703102 CertificationEngineFamilyName "The regulated family name per the applicable certification agency.";
CM_ SG_ 2566703102 ModelYear "The compliance model year of the OBD system of the engine and or vehicle.";
CM_ BO_ 2566705918 "Previously Active Service Only DTCs.";
CM_ SG_ 2566705918 DTC1 "Diagnostic Trouble Code";
CM_ SG_ 2566705918 FlashProtectLamp "This parameter provides the capability to flash the engine protect lamp (SPN 3041).";
CM_ SG_ 2566705918 FlashAmberWarningLamp "This parameter provides the capability to flash the AWL (SPN 3040). ";
CM_ SG_ 2566705918 FlashRedStopLamp "This parameter provides the capability to flash the RSL (SPN 3039).";
CM_ SG_ 2566705918 FlashMalfuncIndicatorLamp "This parameter provides the capability to flash the MIL (SPN 3038).";
CM_ SG_ 2566705918 ProtectLampStatus "This lamp is used to relay trouble code informatio that is reporting a problem with a vehicle system that is most
probably not electronic subsystem related.";
CM_ SG_ 2566705918 AmberWarningLampStatus "This lamp is used to relay trouble code information that is reporting a problem with the vehicle system but the vehicle need
not be immediately stopped.";
CM_ SG_ 2566705918 RedStopLampState "This lamp is uesed to relay trouble code information that is of a severe enought condition that it warrants stopping the vehicle.";
CM_ SG_ 2566705918 MalfunctionIndicatorLampStatus "A lamp used to relay only emissions-related trouble code information.";
CM_ SG_ 2566705918 DTC5 "Diagnostic Trouble Code";
CM_ SG_ 2566705918 DTC4 "Diagnostic Trouble Code";
CM_ SG_ 2566705918 DTC3 "Diagnostic Trouble Code";
CM_ SG_ 2566705918 DTC2 "Diagnostic Trouble Code";
CM_ BO_ 2566705662 "Active Service Only DTCs.";
CM_ SG_ 2566705662 DTC1 "Diagnostic Trouble Code";
CM_ SG_ 2566705662 FlashProtectLamp "This parameter provides the capability to flash the engine protect lamp (SPN 3041).";
CM_ SG_ 2566705662 FlashAmberWarningLamp "This parameter provides the capability to flash the AWL (SPN 3040). ";
CM_ SG_ 2566705662 FlashRedStopLamp "This parameter provides the capability to flash the RSL (SPN 3039).";
CM_ SG_ 2566705662 FlashMalfuncIndicatorLamp "This parameter provides the capability to flash the MIL (SPN 3038).";
CM_ SG_ 2566705662 ProtectLampStatus "This lamp is used to relay trouble code informatio that is reporting a problem with a vehicle system that is most
probably not electronic subsystem related.";
CM_ SG_ 2566705662 AmberWarningLampStatus "This lamp is used to relay trouble code information that is reporting a problem with the vehicle system but the vehicle need
not be immediately stopped.";
CM_ SG_ 2566705662 RedStopLampState "This lamp is uesed to relay trouble code information that is of a severe enought condition that it warrants stopping the vehicle.";
CM_ SG_ 2566705662 MalfunctionIndicatorLampStatus "A lamp used to relay only emissions-related trouble code information.";
CM_ SG_ 2566705662 DTC5 "Diagnostic Trouble Code";
CM_ SG_ 2566705662 DTC4 "Diagnostic Trouble Code";
CM_ SG_ 2566705662 DTC3 "Diagnostic Trouble Code";
CM_ SG_ 2566705662 DTC2 "Diagnostic Trouble Code";
CM_ BO_ 2566706174 "Diagnostic Data Clear/Reset for All Service Only DTCs.";
CM_ BO_ 2349465342 "Contains Static Roll Angle Data and Status of the Static Roll Angle Sensor ...";
CM_ SG_ 2349465342 StaticRollAngleStatus "Status of the transmitted roll angle data.";
CM_ SG_ 2349465342 StaticRollAngle "The measured static roll angle between the vehicle y-axis and the ground plane about the X-axis.  The sign of the roll ...";
CM_ SG_ 2566767614 AccelPedal2Channel3 "Sensor output 3 for the accelerator pedal #2 position when using a redundant-style sensor.  The ratio of actual ...";
CM_ SG_ 2566767614 AccelPedal2Channel2 "Sensor output 2 for the accelerator pedal #2 position when using a redundant-style sensor.  The ratio of actual ...";
CM_ SG_ 2566767614 AccelPedal1Channel3 "Sensor output 3 for the accelerator pedal #1 position when using a redundant-style sensor.  The ratio of actual ...";
CM_ SG_ 2566767614 AccelPedal1Channel2 "Sensor output 2 for the accelerator pedal #1 position when using a redundant-style sensor.  The ratio of actual ...";
CM_ SG_ 2559049470 DesiredEngFuelingState "Devices send this request to the engine controller to: (a) Shut off engine fueling, but remain prepared to re-start quickly by not shutting down the control system, or ...";
CM_ BO_ 2349596414 "Advanced Emergency Braking System message 2.";
CM_ SG_ 2349596414 AEBS2MessageChecksum "Used to check the message checksum of the transmitting (HMI) unit within the AEBS2 system.";
CM_ SG_ 2349596414 AEBS2MessageCounter "The message counter is increased with every transmitted AEBS2 message.  After reaching a value of 0xF the next value ...";
CM_ SG_ 2349596414 DrvrActvtnDmndFrAdvncdEmrgncyBrk "According to the Vienna world convention on road traffic the driver must be provided with means to deactivate an ...";
CM_ SG_ 2566767358 FuelType "Type of fuel currently being utilized by the vehicle ...";
CM_ SG_ 2566767358 EngFuelMassFlowRate "Mass of fuel consumed by engine per unit of time.";
CM_ SG_ 2566767358 EngExhstGsRcrcltn1Valve2PosError "The position error of the Exhaust Gas Recirculation 1 valve 2, determined as the actual position (SPN 3821) minus the ...";
CM_ SG_ 2566767358 EngExhstGsRcrcltn1Valve1PosError "The position error of the Exhaust Gas Recirculation 1 valve, determined as the actual position (SPN 2791) minus the ...";
CM_ BO_ 2566706686 "Contains information on Diesel Exhaust Fluid Pumps ...";
CM_ SG_ 2566706686 Aftrtrtmnt1DslExhstFldPumpHeater "Percentage of heating applied to the aftertreatment 1 diesel exhaust fluid pump heater. A value of 0% means no heating ...";
CM_ SG_ 2566705406 Aftertreatment2ParticulateSensor "The particulate sensor measures the mass concentration of particulate matter in the exhaust downstream of the DPF in ...";
CM_ SG_ 2566705406 Aftertreatment1ParticulateSensor "The particulate sensor measures the mass concentration of particulate matter in the exhaust downstream of the DPF in ...";
CM_ BO_ 2566705150 "Request to initiate the self-diagnosis of the NOx sensors implemented in the system.";
CM_ SG_ 2566705150 NOxSnsorATI2SelfdiagnosisTrigger "Signal to trigger the self-diagnosis of NOx sensor ATI2 (Aftertreatment Intake Bank 2) ...";
CM_ SG_ 2566705150 NOxSnsorATO2SelfdiagnosisTrigger "Signal to trigger the self-diagnosis of NOx sensor ATO2 (Aftertreatment Outlet Bank 2) ...";
CM_ SG_ 2566705150 NOxSnsorATI1SelfdiagnosisTrigger "Signal to trigger the self-diagnosis of NOx sensor ATI1 (Aftertreatment Intake Bank 1) ...";
CM_ SG_ 2566705150 NOxSnsorATO1SelfdiagnosisTrigger "Signal to trigger the self-diagnosis of NOx sensor ATO1 (Aftertreatment Outlet Bank 1) ...";
CM_ BO_ 2566704382 "Engine Related Parameters ...";
CM_ SG_ 2566704382 Aftrtrtmnt2OtltGsSnsrPowerSupply "State signal which indicates when the Aftertreatment 2 Outlet Gas Sensor driver output is being driven.  On means the ...";
CM_ SG_ 2566704382 Aftrtrtmnt2IntkGsSnsrPowerSupply "State signal which indicates when the Aftertreatment 2 Intake Gas Sensor driver output is being driven.  On means the ...";
CM_ SG_ 2566704382 Aftrtrtmnt1OtltGsSnsrPowerSupply "State signal which indicates when the Aftertreatment 1 Outlet Gas Sensor driver output is being driven.  On means the ...";
CM_ SG_ 2566704382 Aftrtrtmnt1IntkGsSnsrPowerSupply "State signal which indicates when the Aftertreatment 1 Intake Gas Sensor driver output is being driven.  On means the ...";
CM_ BO_ 2566704126 "Engine Exhaust Gas Recirculation 1 Actuator related parameters ...";
CM_ SG_ 2566704126 EngExhstGsRcrcltn1Acttr2PrlmnryF "Used to identify the applicable J1939-73 FMI detected in the Engine Exhaust Gas Recirculation 1 Actuator 2 by the ...";
CM_ SG_ 2566704126 EngExhstGsRcrcltn1Acttr2OprtnStt "Used to identify the status of Exhaust Gas Recirculation 1 Actuator 2 ...";
CM_ SG_ 2566704126 EngExhstGsRcrcltn1Acttr1OprtnStt "Used to identify the status of Exhaust Gas Recirculation 1 Actuator 1 ...";
CM_ SG_ 2566704126 EngExhstGsRcrcltn1Acttr2DsredPos "The requested position of the Engine Exhaust Gas Recirculation 1 Actuator 2 by the engine ECU, where 0% represents ...";
CM_ SG_ 2566704126 EngExhstGsRcrclton1Actuator2Temp "Temperature of the Engine Exhaust Gas Recirculation 1 Actuator 2 drive circuitry.  Temperature excursions may affect ...";
CM_ SG_ 2566704126 EngExhstGsRcrcltn1Acttr2TmpSttus "Used to identify the status of the Engine Exhaust Gas Recirculation 1 Actuator 2 drive circuitry temperature.  Temperature ...";
CM_ SG_ 2566704126 EngExhstGsRcrcltn1Acttr1DsredPos "The requested position of the Engine Exhaust Gas Recirculation 1 Actuator 1 by the engine ECU, where 0% represents ...";
CM_ SG_ 2566704126 EngExhstGsRcrclton1Actuator1Temp "Temperature of the Engine Exhaust Gas Recirculation 1 Actuator 1 drive circuitry.  Temperature excursions may affect ...";
CM_ SG_ 2566704126 EngExhstGsRcrcltn1Acttr1TmpSttus "Used to identify the status of the Engine Exhaust Gas Recirculation 1 Actuator 1 drive circuitry temperature.  Temperature ...";
CM_ SG_ 2566704126 EngExhstGsRcrcltn1Acttr1PrlmnryF "Used to identify the applicable J1939-73 FMI detected in the Engine Exhaust Gas Recirculation 1 Actuator 1 by the ...";
CM_ BO_ 2566703870 "Engine Exhaust Gas Recirculation 2 Actuator related parameters ...";
CM_ SG_ 2566703870 EngExhstGsRcrcltn2Acttr2OprtnStt "Used to identify the status of Exhaust Gas Recirculation 2 Actuator 2 ...";
CM_ SG_ 2566703870 EngExhstGsRcrcltn2Acttr1OprtnStt "Used to identify the status of Exhaust Gas Recirculation 2 Actuator 1 ...";
CM_ SG_ 2566703870 EngExhstGsRcrcltn2Acttr2DsredPos "The requested position of the Engine Exhaust Gas Recirculation 2 Actuator 2 by the engine ECU, where 0% represents ...";
CM_ SG_ 2566703870 EngExhstGsRcrclton2Actuator2Temp "Temperature of the Engine Exhaust Gas Recirculation 2 Actuator 2 drive circuitry.  Temperature excursions may affect ...";
CM_ SG_ 2566703870 EngExhstGsRcrcltn2Acttr2TmpSttus "Used to identify the status of the Engine Exhaust Gas Recirculation 2 Actuator 2 drive circuitry temperature.  Temperature ...";
CM_ SG_ 2566703870 EngExhstGsRcrcltn2Acttr2PrlmnryF "Used to identify the applicable J1939-73 FMI detected in the Engine Exhaust Gas Recirculation 2 Actuator 2 by the ...";
CM_ SG_ 2566703870 EngExhstGsRcrcltn2Acttr1DsredPos "The requested position of the Engine Exhaust Gas Recirculation 2 Actuator 1 by the engine ECU, where 0% represents ...";
CM_ SG_ 2566703870 EngExhstGsRcrclton2Actuator1Temp "Temperature of the Engine Exhaust Gas Recirculation 2 Actuator 1 drive circuitry.  Temperature excursions may affect ...";
CM_ SG_ 2566703870 EngExhstGsRcrcltn2Acttr1TmpSttus "Used to identify the status of the Engine Exhaust Gas Recirculation 2 Actuator 1 drive circuitry temperature.  Temperature ...";
CM_ SG_ 2566703870 EngExhstGsRcrcltn2Acttr1PrlmnryF "Used to identify the applicable J1939-73 FMI detected in the Engine Exhaust Gas Recirculation 2 Actuator 1 by the ...";
CM_ BO_ 2566703614 "This PGN will be used to transmit the Feedback information from the Engine Throttle and Fuel Actuator.";
CM_ SG_ 2566703614 EngTurboWastegateActuator2Temp "Temperature of the Engine Turbocharger Wastegate Actuator 2 drive circuitry.  Temperature excursions may affect the ...";
CM_ SG_ 2566703614 EngFuelValve2Temp "Temperature of the Engine Fuel Valve 2 drive circuitry. Temperature excursions may affect the torque output.";
CM_ SG_ 2566703614 EngFuelValve1Temp "Temperature of the Engine Fuel Valve 1 drive circuitry. Temperature excursions may affect the torque output.";
CM_ SG_ 2566703614 EngThrottleValve2Temp "Temperature of the engine throttle valve 2 drive circuitry (SPN 3783).  Temperature excursions may affect the torque ...";
CM_ SG_ 2566703614 EngThrottleValve1Temp "Temperature of the engine throttle valve 1 drive circuitry (SPN 53).  Temperature excursions may affect the torque output.";
CM_ SG_ 2566703358 EngFuelingInhibitPreventedReason "If Engine Fueling Inhibit Allowed (SPN 5795) indicates that the engine will not inhibit fueling, then this parameter will ...";
CM_ SG_ 2566703358 EngFuelingInhibitAllowed "This parameter is broadcast by the engine control system, and indicates to other devices on the network whether or not it ...";
CM_ SG_ 2566703358 FeedbackEngFuelingState "This parameter provides feedback to the network that SPN 5793 Desired Engine Fueling State was honored.";
CM_ BO_ 2566702590 "This message contains SCR catalyst gas temperature information for aftertreatment system 1 (or bank 1).";
CM_ SG_ 2566702590 Aftrtrtmnt1SCRIntrmdtGsTmpPrlmnr "Used to identify the applicable J1939-73 FMI detected in the aftertreatment SCR intermediate gas temperature sensor by ...";
CM_ SG_ 2566702590 Aftrtrtmnt1SCRIntrmediateGasTemp "Temperature of engine combustion byproducts at an intermediate point in the SCR component in exhaust bank 1.";
CM_ BO_ 2566702334 "This message contains SCR catalyst gas temperature information for aftertreatment system 2 (or bank 2).";
CM_ SG_ 2566702334 Aftrtrtmnt2SCRIntrmdtGsTmpPrlmnr "Used to identify the applicable J1939-73 FMI detected in the aftertreatment SCR intermediate gas temperature sensor by ...";
CM_ SG_ 2566702334 Aftrtrtmnt2SCRIntrmediateGasTemp "Temperature of engine combustion byproducts at an intermediate point in the SCR component in exhaust bank 2.";
CM_ BO_ 2566702078 "Gaseous fuel information 4 ...";
CM_ SG_ 2566702078 SupplyGasMethanePercentage "The percentage of methane in the gas supplied to the engine.";
CM_ BO_ 2566701822 "Status information of a hybrid system.";
CM_ SG_ 2566701822 HybridSystemStopIndicator "Signal from a hybrid system indicating that some aspect of its operation is not functioning correctly, and as a result, the ...";
CM_ SG_ 2566701822 HybridSystemOverheatIndicator "Signal from a hybrid system indicating that at least one of its monitored temperatures is above normal acceptable limits, ...";
CM_ SG_ 2566701822 HybridSystemWarningIndicator "Signal from a hybrid system indicating that some aspect of its operation is not functioning correctly, and as a result, hybrid ...";
CM_ BO_ 2431661310 "This message contains aftertreatment intermediate ammonia information for aftertreatment system 2 (or bank 2).";
CM_ SG_ 2431661310 Aftrtrtmnt2SCRIntrmdtNH3GsSn5861 "Indicates the heater status in the warm-up process. Upon receiving a power-up command, the NH3 gas sensor ramps up ...";
CM_ SG_ 2431661310 Aftrtrtmnt2SCRIntrmdtNH3GsSnsrHt "Used to identify the applicable J1939-73 FMI detected in the heater of the SCR intermediate NH3 exhaust gas sensor by ...";
CM_ SG_ 2431661310 Aftrtrtmnt2SCRIntrmdtNH3GsSnsrAt "Indicates that the heater element of the aftertreatment SCR intermediate NH3 gas sensor is within the manufacturer’s ...";
CM_ SG_ 2431661310 Aftrtrtmnt2SCRIntrmdtNH3GsSnsrPw "Indicates that the power supplied to the aftertreatment SCR intermediate NH3 gas sensor is within the manufacturer’s ...";
CM_ SG_ 2431661310 Aftrtrtmnt2SCRIntrmdtNH3RdngStbl "Indicates that the NH3 reading of the aftertreatment SCR intermediate NH3 sensor is stable as determined by the ...";
CM_ SG_ 2431661310 Aftrtrtmnt2SCRIntrmdtNH3SnsrPrlm "Used to identify the applicable J1939-73 FMI detected in the aftertreatment SCR intermediate NH3 sensor by the ...";
CM_ SG_ 2431661310 Aftrtreatment2SCRIntermediateNH3 "The amount of NH3 in the exhaust aftertreatment system measured by a NH3 sensor at an intermediate point in the SCR ...";
CM_ BO_ 2431661054 "This message contains aftertreatment intermediate ammonia information for aftertreatment system 1 (or bank 1).";
CM_ SG_ 2431661054 Aftrtrtmnt1SCRIntrmdtNH3GsSn5854 "Indicates the heater status in the warm-up process. Upon receiving a power-up command, the NH3 gas sensor ramps up ...";
CM_ SG_ 2431661054 Aftrtrtmnt1SCRIntrmdtNH3GsSnsrHt "Used to identify the applicable J1939-73 FMI detected in the heater of the outlet NH3 exhaust gas sensor by the ...";
CM_ SG_ 2431661054 Aftrtrtmnt1SCRIntrmdtNH3GsSnsrAt "Indicates that the heater element of the aftertreatment SCR intermediate NH3 gas sensor is within the manufacturer’s ...";
CM_ SG_ 2431661054 Aftrtrtmnt1SCRIntrmdtNH3GsSnsrPw "Indicates that the power supplied to the aftertreatment SCR intermediate NH3 gas sensor is within the manufacturer’s ...";
CM_ SG_ 2431661054 Aftrtrtmnt1SCRIntrmdtNH3RdngStbl "Indicates that the NH3 reading of the aftertreatment SCR intermediate NH3 sensor is stable as determined by the ...";
CM_ SG_ 2431661054 Aftrtrtmnt1SCRIntrmdtNH3SnsrPrlm "Used to identify the applicable J1939-73 FMI detected in the aftertreatment SCR intermediate NH3 sensor by the ...";
CM_ SG_ 2431661054 Aftrtreatment1SCRIntermediateNH3 "The amount of NH3 in the exhaust aftertreatment system measured by a NH3 sensor at an intermediate point in the SCR ...";
CM_ BO_ 2230334206 "The Linear Displacement Sensor is an electromechanical sensor that detects the distance of an object from the body of ...";
CM_ SG_ 2230334206 LnrDsplcmntSnsrSnsrFigureOfMerit "Figure of Merit sensor status of Linear Displacement Sensor.";
CM_ SG_ 2230334206 MeasuredLinearDisplacement "Distance to target as measured by the Linear Displacement Sensor.";
CM_ BO_ 2230333950 "The wand sensor is an electromechanical sensor that detects the angle of deflection of a wand.";
CM_ SG_ 2230333950 WandSensorFigureOfMerit "Figure of Merit sensor status for a wand sensor.";
CM_ SG_ 2230333950 WandAngle "A wand sensor measures the angle of deflection of a wand from its null position. This parameter reports the measured ...";
CM_ BO_ 2364551422 "Carries commands received by the wireless transceiver from an off-board transmitter and conveys ...";
CM_ SG_ 2364551422 WirelessSignalStrength1 "The absolute received signal strength of the signal received from the off-board transmitter. The signal strength is reported ...";
CM_ SG_ 2364551422 TransmitterID1 "The ID of the off-board transmitter that sent the incoming message received by the wireless transceiver.";
CM_ SG_ 2364551422 TransmitterCmdState "The command contained in the signal received by the wireless transceiver from an off-board transmitter.";
CM_ SG_ 2364551422 WirelessRollingMessageCounter "A counter incremented with each instance of the Wireless Status message. The counter shall increment from 0 to 64255, ...";
CM_ BO_ 2364551166 "Advanced Emergency Braking System message 1.";
CM_ SG_ 2364551166 TmeToCollisionWithRelevantObject "The time to collision is the duration after which the predicted travelling paths of host vehicle and relevant object lead to a ...";
CM_ SG_ 2364551166 BndOffPrbabilityOfRelevantObject "Probabilty if monitored relevant object might start a turning maneuver, which could clear the travelling path of the host ...";
CM_ SG_ 2364551166 RlvntObjctDtctdFrAdvncdEmrgncyBr "Indication if the advanced emergency braking system (AEBS) is monitoring a relevant object ...";
CM_ SG_ 2364551166 CollisionWarningLevel "To implement different HMI (human machine interface) concepts, e.g. visual only, visual/audible, different warning tones ...";
CM_ SG_ 2364551166 AdvncdEmrgencyBrakingSystemState "Current operational state of advanced emergency braking system ...";
CM_ BO_ 2566730238 "This parameter group transfers status and measured information for a second engine coolant fan.  For systems with a ...";
CM_ SG_ 2566730238 Fan2DriveBypassCmdStatus "Status of the Fan Drive Bypass Command for the second fan as being commanded by the ECU.  The fan drive bypass ...";
CM_ SG_ 2566730238 HydFan2MotorPress "The hydraulic pressure used to drive the second fan system, sensed before the hydraulic fan motor.";
CM_ SG_ 2566730238 Fan2Speed "The speed of the second fan associated with engine coolant system.";
CM_ SG_ 2566730238 Fan2DriveState "This parameter is used to indicate the current state or mode of operation by the second fan drive.";
CM_ SG_ 2566730238 EstPercentFan2Speed "Estimated fan speed as a ratio of the fan drive (current speed) to the fully engaged fan drive (maximum fan speed).  A two ...";
CM_ BO_ 2566711038 "Reports vehicle/chassis lubrication systems status ...";
CM_ SG_ 2566711038 LubricationTimingCycleStatus "Reports the status of the lubrication activation clock.";
CM_ SG_ 2566711038 LubricationReservoirLevel "Reports the status of the lubrication system reservior level.  The lubrication reservoir stores the grease for the lubrication ...";
CM_ SG_ 2566711038 LubricationPumpEnableStatus "Reports the operational status of the lubrication system pump.  In the disabled state, the lubrication pump will not run a ...";
CM_ SG_ 2566711038 LubricationOperationModeStatus "Reports the current operational mode status of the lubrication system.";
CM_ SG_ 2566711038 LubricationCycleModeStatus "Reports the current lubrication cycle mode of the lubrication system ...";
CM_ SG_ 2566711038 LubricationCycleModeLockStatus "Reports status of the ability to change the lubrication cycle mode.  Locking the lubrication mode would prevent the ...";
CM_ BO_ 2566710782 "Hydraulic Oil Properties.  This hydraulic fluid is for the entire hydraulics system of a piece of equipment.";
CM_ SG_ 2566710782 HydOilTemp "Hydraulic Oil Temperature.  This hydraulic fluid is for the entire hydraulics system of a piece of equipment.";
CM_ SG_ 2566710782 HydOilRelativeDielectricity "Hydraulic oil relative dielectricity used to describe the hydraulic oil quality.  This hydraulic fluid is for the entire hydraulics ...";
CM_ SG_ 2566710782 HydOilDensity "Density of hydraulic oil.  This hydraulic fluid is for the entire hydraulics system of a piece of equipment.";
CM_ SG_ 2566710782 HydOilDynamicViscosity "Dynamic viscosity of hydraulic oil.  This hydraulic fluid is for the entire hydraulics system of a piece of equipment.";
CM_ BO_ 2566710526 "Engine Fuel Properties ...";
CM_ SG_ 2566710526 EngFuelTemp "Engine Fuel Temperature.  See also SPNs 174 or 3468 for alternate resolution.";
CM_ SG_ 2566710526 EngFuelDielectricity "Engine fuel relative dielectricity.";
CM_ SG_ 2566710526 EngFuelDensity "Density of engine fuel ...";
CM_ SG_ 2566710526 EngFuelDynamicViscosity "Dynamic viscosity of engine fuel ...";
CM_ BO_ 2432492542 "Contains information about the engine exhaust brake system control.";
CM_ SG_ 2432492542 DsredEngTurbo2TurbineOutletPress "The desired gage pressure of the combustion by-products exiting the turbine side of the turbocharger 5 at the current ...";
CM_ SG_ 2432492542 EngTurbo2TurbineOutletPress "Gage pressure of the combustion by-products exiting the turbine side of the turbocharger 2.";
CM_ SG_ 2432492542 EngExhaustBrakeActuatorCmd "The control command applied to the engine exhaust brake actuator, where 0% represents no braking and 100% ...";
CM_ SG_ 2432492542 DsredEngTurbo1TurbineOutletPress "The desired gage pressure of the combustion by-products exiting the turbine side of the turbocharger 1 at the current ...";
CM_ SG_ 2432492542 EngTurbo1TurbineOutletPress "Gage pressure of the combustion by-products exiting the turbine side of the turbocharger 1.";
CM_ BO_ 2566710014 "The status of Supplemental Fan. This is a supplemental fan used for additional cooling beyond that of the primary cooling ...";
CM_ SG_ 2566710014 SupplementalFanPower "Estimated Power output of Supplemental Fan ...";
CM_ SG_ 2566710014 SupplementalFanCurrent "Measured electrical current of supplemental fan drive.";
CM_ SG_ 2566710014 SupplementalFanSpeed "Measured speed of supplemental fan.";
CM_ SG_ 2566710014 SupplementalFanCtrlECUTemp "Measured temperature of Supplemental Fan Controller ECU.";
CM_ SG_ 2566710014 SupplementalFanDriveStatus "The drive status of the Supplemental Fan. This status parameter indicates the overall health of the fan drive. It will ...";
CM_ SG_ 2566710014 SupplementalFanCtrlTempStatus "Internal Controller Temperature Status of Supplemental Fan.";
CM_ SG_ 2566710014 SupplementalFanVelocityStatus "Status of the rotational velocity of Supplemental Fan. Used to indicate if the fan is spinning at the desired speed. If fan is ...";
CM_ SG_ 2566710014 SupplementalFanDirectionStatus "Rotational Direction of Supplemental Fan. Fan could be spinning forward or reverse.";
CM_ SG_ 2566710014 SupplementalFanEnableStatus "Enable/Disable Status of Supplemental Fan.";
CM_ SG_ 2566709758 HighResolutionEngFuelRate "Amount of fuel consumed by engine per unit of time.";
CM_ BO_ 2566709502 "The purpose of this PGN is to group parameters about the diesel particulate filter regeneration control.";
CM_ SG_ 2566709502 Aftertreatment2FuelMassRate "Mass rate of total fuel being delivered to Atertreatment 2 for DPF regeneration.";
CM_ SG_ 2566709502 Aftertreatment1FuelMassRate "Mass rate of total fuel being delivered to aftertreatment 1 for DPF regeneration.";
CM_ SG_ 2566709502 RelativeUnburnedFuelMassFromEng "The unburned amount of diesel fuel coming out of the engine. This fuel increases the temperature while oxidated in the ...";
CM_ SG_ 2566709502 Aftrtrtmnt1DslPrtcltFltrIntkTmpS "Set point temperature for the particulate filter (DPF) regeneration at the intake to the DPF for Exhaust bank 1.";
CM_ BO_ 2566709246 "12th PGN which identifies parameters that are either measuring various pressures within the engine or identifying engine ...";
CM_ SG_ 2566709246 EngFuelFilterDegradation "The estimated percentage relative to the useful life of the engine fuel filter.";
CM_ SG_ 2566709246 EngFilteredFuelDeliveryAbsPress "Absolute pressure of fuel in system as delivered from supply pump to the injection pump after the pressure side fuel filter.";
CM_ SG_ 2566709246 EngFilteredFuelDeliveryPress "Gage pressure of fuel in system as delivered from supply pump to the injection pump after the pressure side fuel filter.";
CM_ SG_ 2566709246 EngFuelDeliveryAbsPress "Absolute pressure of fuel in system as delivered from supply pump to the injection pump.  See also SPN 94 for Fuel ...";
CM_ BO_ 2566708990 "This PGN contains information about the Aftertreatment 1 Air Control.";
CM_ SG_ 2566708990 Aftertreatment1SecondAirAbsPress "Absolute pressure of the secondary air for aftertreatment 1. Secondary air is air provided to the exhaust system (per SAE ...";
CM_ BO_ 2566708734 "This PGN contains information about the Aftertreatment 2 Air Control.";
CM_ SG_ 2566708734 Aftertreatment2SecondAirAbsPress "Absolute pressure of the secondary air for aftertreatment 2. Secondary air is air provided to the exhaust system (per SAE ...";
CM_ BO_ 2566708478 "Cruise Control / Vehicle Speed 3 ...";
CM_ SG_ 2566708478 SrcAddrssOfCntrllngDvcFrPsngCrsC "The source address of the SAE J1939 device that is currently sending the Cruise Control Pause Command (SPN 5605).";
CM_ SG_ 2566708478 SrcAddrssOfCntrllngDvcFrDsblngCr "The source address of the SAE J1939 device that is currently sending the Cruise Control Disable Command (SPN 5603).";
CM_ SG_ 2566708478 CruiseCtrlSystemCmdState "Indicates the current state of the cruise control system due to the Cruise Control System Commands, which include ...";
CM_ SG_ 2566708478 AdptiveCruiseCtrlReadinessStatus "This parameter is used to indicate an application's state of readiness for responding to commands from an adaptive ...";
CM_ BO_ 2566708222 "This message is used to specify up to 4 soot sensor analysis frequencies to request the soot sensor signal data ...";
CM_ SG_ 2566708222 Aftrtrtmnt1DslPrtcltFltr1StS5635 "Fourth requested analysis frequency for the diesel particulate filter 1 soot sensor.";
CM_ SG_ 2566708222 Aftrtrtmnt1DslPrtcltFltr1StS5634 "Third requested analysis frequency for the diesel particulate filter 1 soot sensor.";
CM_ SG_ 2566708222 Aftrtrtmnt1DslPrtcltFltr1StS5633 "Second requested analysis frequency for the diesel particulate filter 1 soot sensor.";
CM_ SG_ 2566708222 Aftrtrtmnt1DslPrtcltFltr1StSnsrA "First requested analysis frequency for the diesel particulate filter 1 soot sensor.";
CM_ BO_ 2566707966 "This message is used report the analysis frequency and associated soot sensor signal data for two of the requested ...";
CM_ SG_ 2566707966 Aftrtrtmnt1DslPrtcltFltr1StS5639 "The soot signal attenuation measurement for analysis frequency 2 for the diesel particulate filter 1 soot sensor.  See SPN ...";
CM_ SG_ 2566707966 Aftrtrtmnt1DslPrtcltFltr1StS5638 "The analysis frequency associated with the frequency 2 soot signal for the diesel particulate filter 1 soot sensor.  See ...";
CM_ SG_ 2566707966 Aftrtrtmnt1DslPrtcltFltr1StSnsrF "The soot signal attenuation measurement for analysis frequency 1 for the diesel particulate filter 1 soot sensor.  See SPN ...";
CM_ SG_ 2566707966 Aftrtrtmnt1DslPrtcltFltr1StSnsrA "The analysis frequency associated with the frequency 1 soot signal for the diesel particulate filter 1 soot sensor.  See ...";
CM_ BO_ 2566707710 "This message is used report the analysis frequency and associated soot sensor signal data for two of the requested ...";
CM_ SG_ 2566707710 Aftrtrtmnt1DslPrtcltFltr1StS5643 "The soot signal attenuation measurement for analysis frequency 4 for the diesel particulate filter 1 soot sensor.  See SPN ...";
CM_ SG_ 2566707710 Aftrtrtmnt1DslPrtcltFltr1StS5642 "The analysis frequency associated with the frequency 4 soot signal for the diesel particulate filter 1 soot sensor.  See ...";
CM_ SG_ 2566707710 Aftrtrtmnt1DslPrtcltFltr1StSnsrF "The soot signal attenuation measurement for analysis frequency 3 for the diesel particulate filter 1 soot sensor.  See SPN ...";
CM_ SG_ 2566707710 Aftrtrtmnt1DslPrtcltFltr1StSnsrA "The analysis frequency associated with the frequency 3 soot signal for the diesel particulate filter 1 soot sensor.  See ...";
CM_ BO_ 2297441790 "The acceleration sensor message shall provide a measurement of the vehicle's acceleration in the lateral, longitudinal, ...";
CM_ SG_ 2297441790 SpprtVrblTrnsRpttnRtFrAcclrtnSns "Indicates which acceleration transmission rate are supported by the ECU in addition to the required 10 ms transmission ...";
CM_ SG_ 2297441790 VrtclAcclrtnExRangeFigureOfMerit "Figure of merit for vertical acceleration measurement.";
CM_ SG_ 2297441790 LngtdnlAcclrtnExRngFigureOfMerit "Figure of merit for longitudinal acceleration measurement.";
CM_ SG_ 2297441790 LtrlAcclrtonExRangeFigureOfMerit "Figure of merit for lateral acceleration measurement.";
CM_ SG_ 2297441790 VerticalAccelerationExRange "Indicates vertical acceleration of the vehicle and the effect of gravity (the component of vehicle acceleration vector along ...";
CM_ SG_ 2297441790 LongitudinalAccelerationExRange "Indicates longitudinal acceleration of the vehicle (the component of vehicle acceleration vector along the X-axis).  A ...";
CM_ SG_ 2297441790 LateralAccelerationExRange "Indicates lateral acceleration of the vehicle (the component of vehicle acceleration vector along the Y-axis).  A positive ...";
CM_ BO_ 2566712062 "Hybrid system voltage information.";
CM_ SG_ 2566712062 HybridBatteryPackRemainingCharge "Indicates the hybrid battery pack remaining charge. 0% means no charge remaining, 100% means full charge remaining.";
CM_ BO_ 2364549630 "The Slope Sensor Information 2 message shall provide a measurement of the vehicle's extended pitch angle and a ...";
CM_ SG_ 2364549630 RllAndPtchExRngMasurementLatency "Time between start of sensor processing and CAN transmission ...";
CM_ SG_ 2364549630 RollAngleExRangeFigureOfMerit "Figure of merit for roll angle measurement.";
CM_ SG_ 2364549630 RollAngleExRangeCompensation "Compensated mode for the roll angle measurement.  Compensation is the use of multiple sensors together to enhance ...";
CM_ SG_ 2364549630 PitchAngleExRangeFigureOfMerit "Figure of merit for pitch angle measurement.";
CM_ SG_ 2364549630 PitchAngleExRangeCompensation "Compensated mode for the pitch measurement.  Compensation is the use of multiple sensors together to enhance the ...";
CM_ SG_ 2364549630 RollAngleExRange "The angle between the vehicle y-axis and the ground plane (i.e. rotation about the X-axis).  The roll angle for a roll to the ...";
CM_ SG_ 2364549630 PitchAngleExRange "The angle between the vehicle x-axis and the ground plane (i.e. rotation about the vehicle Y-axis).  The pitch angle for an ...";
CM_ BO_ 2499614462 "Message containing status of Occupant Classification System for driver, passenger and rear seating positions. The PGN ...";
CM_ SG_ 2499614462 OccpntClssficationSystem10Status "State of Occupant Classification System for seat position 10.";
CM_ SG_ 2499614462 OccpntClssificationSystem9Status "State of Occupant Classification System for seat position 9.";
CM_ SG_ 2499614462 OccpntClssificationSystem8Status "State of Occupant Classification System for seat position 8.";
CM_ SG_ 2499614462 OccpntClssificationSystem7Status "State of Occupant Classification System for seat position 7.";
CM_ SG_ 2499614462 OccpntClssificationSystem6Status "State of Occupant Classification System for seat position 6.";
CM_ SG_ 2499614462 OccpntClssificationSystem5Status "State of Occupant Classification System for seat position 5.";
CM_ SG_ 2499614462 OccpntClssificationSystem4Status "State of Occupant Classification System for seat position 4.";
CM_ SG_ 2499614462 OccpntClssificationSystem3Status "State of Occupant Classification System for seat position 3.";
CM_ SG_ 2499614462 PssngrOccpntClssfctnSystemStatus "State of Occupant Classification System for passenger.";
CM_ SG_ 2499614462 DrvrOccpntClssfctionSystemStatus "State of Occupant Classification System for driver.";
CM_ BO_ 2560098046 "Used to report the current state of the Noise Control System.";
CM_ SG_ 2560098046 CabNoiseCtrlTuningStatus "This parameter returns the current status of tuning function of the Cab Noise Control system.    When the tuning state is ...";
CM_ SG_ 2560098046 CabNoiseCtrlStatus "This parameter returns the current status of the Cab Noise Control system.";
CM_ BO_ 2560163582 "Used to issue commands to the Noise Control System.  This command PGN typically originates from either a Cab control ...";
CM_ SG_ 2560163582 CabNoiseCtrlTuningCmd "Command values for the Tuning State of the Cab Noise Control System.  The Tuning State allows the Cab Noise Control ...";
CM_ SG_ 2560163582 CabNoiseCtrlCmd "Command signal to change the state of the Cab Noise Control System to on-line or off-line ...";
CM_ BO_ 2297441534 "This message carries data related to the status of the magnetic material handling system, possibly including the generator ...";
CM_ SG_ 2297441534 MagnetGeneratorCtrl "Command signal used to Enable and Disable the Generator controlling a Magnet.";
CM_ SG_ 2297441534 DropRelayCtrl "Command signal used to Engage and Disengage the Drop Relay controlling a Steady-State Magnet.";
CM_ SG_ 2297441534 LiftRelayCtrl "Command signal used to Engage and Disengage the Lift Relay controlling a Steady-State Magnet.";
CM_ SG_ 2297441534 MaterialDropActiveStatus "The status of Material Drop Relay. When it is on, the generator generates reverse direction current so that the material ...";
CM_ SG_ 2297441534 MaterialLiftActiveStatus "The status of Material Lift Relay. When it is on, the generator generates forward direction current so that the material ...";
CM_ SG_ 2297441534 GneratorCurrentBoostActiveStatus "Status of generator current boost relay that can boost the generator output current for picking-up material operations.";
CM_ SG_ 2297441534 MaterialDropSwitch "This is a switch that can be used to enable the drop functionality of the Material Handler machine.";
CM_ SG_ 2297441534 MaterialLiftSwitch "This is a switch that can be used to enable the lift functionality of the Material Handler machine. When it is activated, the ...";
CM_ SG_ 2297441534 MagnetReverseCurrent "A reverse current being supplied to the electric magnet to reduce the forward current generated magnet field as quick as ...";
CM_ SG_ 2297441534 MagnetForwardCurrent "The forward current being supplied by the generator to the electric magnet to create a magnet field to lift material.";
BA_DEF_ SG_  "SigType" ENUM  "Default","Range","RangeSigned","ASCII","Discrete","Control","ReferencePGN","DTC","StringDelimiter","StringLength","StringLengthControl";
BA_DEF_ SG_  "GenSigStartValue" INT 0 10000;
BA_DEF_ SG_  "GenSigSendType" ENUM  "Cyclic","OnWrite","OnWriteWithRepetition","OnChange","OnChangeWithRepetition","IfActive","IfActiveWithRepetition","NoSigSendType";
BA_DEF_ SG_  "GenSigILSupport" ENUM  "No","Yes";
BA_DEF_ SG_  "GenSigEVName" STRING ;
BA_DEF_ SG_  "SPN" INT 0 524287;
BA_DEF_ BO_  "GenMsgStartDelayTime" INT 0 100000;
BA_DEF_ BO_  "GenMsgILSupport" ENUM  "No","Yes";
BA_DEF_ BO_  "GenMsgRequestable" INT 0 1;
BA_DEF_ BO_  "GenMsgSendType" ENUM  "cyclic","NotUsed","NotUsed","NotUsed","NotUsed","NotUsed","NotUsed","IfActive","noMsgSendType";
BA_DEF_ BO_  "VFrameFormat" ENUM  "StandardCAN","ExtendedCAN","reserved","J1939PG";
BA_DEF_ BO_  "GenMsgCycleTime" INT 0 3600000;
BA_DEF_ BU_  "NmStationAddress" INT 0 255;
BA_DEF_  "SAE_J1939_81_SpecVersion" STRING ;
BA_DEF_  "DatabaseVersion" STRING ;
BA_DEF_  "BusType" STRING ;
BA_DEF_  "ProtocolType" STRING ;
BA_DEF_  "SAE_J1939_75_SpecVersion" STRING ;
BA_DEF_  "SAE_J1939_21_SpecVersion" STRING ;
BA_DEF_  "SAE_J1939_73_SpecVersion" STRING ;
BA_DEF_  "SAE_J1939_71_SpecVersion" STRING ;
BA_DEF_ SG_  "SystemSignalLongSymbol" STRING ;
BA_DEF_DEF_  "SigType" "Default";
BA_DEF_DEF_  "GenSigStartValue" 0;
BA_DEF_DEF_  "GenSigSendType" "NoSigSendType";
BA_DEF_DEF_  "GenSigILSupport" "Yes";
BA_DEF_DEF_  "GenSigEVName" "Env@Nodename_@Signame";
BA_DEF_DEF_  "SPN" 0;
BA_DEF_DEF_  "GenMsgStartDelayTime" 0;
BA_DEF_DEF_  "GenMsgILSupport" "Yes";
BA_DEF_DEF_  "GenMsgRequestable" 1;
BA_DEF_DEF_  "GenMsgSendType" "noMsgSendType";
BA_DEF_DEF_  "VFrameFormat" "J1939PG";
BA_DEF_DEF_  "GenMsgCycleTime" 0;
BA_DEF_DEF_  "NmStationAddress" 254;
BA_DEF_DEF_  "SAE_J1939_81_SpecVersion" "";
BA_DEF_DEF_  "DatabaseVersion" "";
BA_DEF_DEF_  "BusType" "";
BA_DEF_DEF_  "ProtocolType" "";
BA_DEF_DEF_  "SAE_J1939_75_SpecVersion" "";
BA_DEF_DEF_  "SAE_J1939_21_SpecVersion" "";
BA_DEF_DEF_  "SAE_J1939_73_SpecVersion" "";
BA_DEF_DEF_  "SAE_J1939_71_SpecVersion" "";
BA_DEF_DEF_  "SystemSignalLongSymbol" "";
BA_ "SAE_J1939_81_SpecVersion" "2012-05";
BA_ "DatabaseVersion" "8.0";
BA_ "BusType" "CAN";
BA_ "ProtocolType" "J1939";
BA_ "SAE_J1939_75_SpecVersion" "2012-05";
BA_ "SAE_J1939_21_SpecVersion" "2006-10";
BA_ "SAE_J1939_73_SpecVersion" "2012-10";
BA_ "SAE_J1939_71_SpecVersion" "2012-10";
BA_ "NmStationAddress" BU_ TESTECU 53;
BA_ "NmStationAddress" BU_ BIANSUXIANG 3;
BA_ "NmStationAddress" BU_ SCR 61;
BA_ "NmStationAddress" BU_ EBSECU 11;
BA_ "NmStationAddress" BU_ DisPlay 1;
BA_ "NmStationAddress" BU_ EngineECU 0;
BA_ "GenMsgSendType" BO_ 2566834691 0;
BA_ "GenMsgCycleTime" BO_ 2566834691 1000;
BA_ "GenMsgCycleTime" BO_ 2566834699 1000;
BA_ "GenMsgSendType" BO_ 2566834699 0;
BA_ "GenMsgSendType" BO_ 2566834688 0;
BA_ "GenMsgCycleTime" BO_ 2566834688 1000;
BA_ "GenMsgSendType" BO_ 2566910720 0;
BA_ "GenMsgCycleTime" BO_ 2566910720 10000;
BA_ "GenMsgCycleTime" BO_ 2566805053 1000;
BA_ "GenMsgSendType" BO_ 2566844160 0;
BA_ "GenMsgCycleTime" BO_ 2566844160 500;
BA_ "GenMsgCycleTime" BO_ 2566843904 1000;
BA_ "GenMsgSendType" BO_ 2566843904 0;
BA_ "GenMsgSendType" BO_ 2566844672 0;
BA_ "GenMsgCycleTime" BO_ 2566844672 100;
BA_ "GenMsgSendType" BO_ 2566841344 0;
BA_ "GenMsgCycleTime" BO_ 2566841344 1000;
BA_ "GenMsgCycleTime" BO_ 2566803211 100;
BA_ "GenMsgCycleTime" BO_ 2566848256 10000;
BA_ "GenMsgSendType" BO_ 2566848256 0;
BA_ "GenMsgSendType" BO_ 2364539904 0;
BA_ "GenMsgCycleTime" BO_ 2364539904 10;
BA_ "GenMsgSendType" BO_ 2566707454 0;
BA_ "GenMsgCycleTime" BO_ 2566707454 1000;
BA_ "GenMsgSendType" BO_ 2566707198 0;
BA_ "GenMsgCycleTime" BO_ 2566707198 1000;
BA_ "GenMsgSendType" BO_ 2566706942 0;
BA_ "GenMsgCycleTime" BO_ 2566706942 1000;
BA_ "GenMsgSendType" BO_ 2559770366 0;
BA_ "GenMsgCycleTime" BO_ 2559770366 100;
BA_ "GenMsgSendType" BO_ 2559639294 0;
BA_ "GenMsgCycleTime" BO_ 2559639294 1000;
BA_ "GenMsgSendType" BO_ 2559573758 0;
BA_ "GenMsgCycleTime" BO_ 2559573758 10000;
BA_ "GenMsgSendType" BO_ 2349530878 0;
BA_ "GenMsgCycleTime" BO_ 2349530878 100;
BA_ "GenMsgSendType" BO_ 2365428734 0;
BA_ "GenMsgCycleTime" BO_ 2365428734 100;
BA_ "GenMsgSendType" BO_ 2349465342 0;
BA_ "GenMsgCycleTime" BO_ 2349465342 100;
BA_ "GenMsgSendType" BO_ 2559049470 0;
BA_ "GenMsgCycleTime" BO_ 2559049470 1000;
BA_ "GenMsgSendType" BO_ 2566706686 0;
BA_ "GenMsgCycleTime" BO_ 2566706686 500;
BA_ "GenMsgSendType" BO_ 2566704126 0;
BA_ "GenMsgCycleTime" BO_ 2566704126 100;
BA_ "GenMsgSendType" BO_ 2566703870 0;
BA_ "GenMsgCycleTime" BO_ 2566703870 100;
BA_ "GenMsgSendType" BO_ 2566703614 0;
BA_ "GenMsgCycleTime" BO_ 2566703614 100;
BA_ "GenMsgSendType" BO_ 2566703358 0;
BA_ "GenMsgCycleTime" BO_ 2566703358 1000;
BA_ "GenMsgSendType" BO_ 2566702590 0;
BA_ "GenMsgCycleTime" BO_ 2566702590 500;
BA_ "GenMsgSendType" BO_ 2566702334 0;
BA_ "GenMsgCycleTime" BO_ 2566702334 500;
BA_ "GenMsgSendType" BO_ 2566702078 0;
BA_ "GenMsgCycleTime" BO_ 2566702078 200;
BA_ "GenMsgSendType" BO_ 2566701822 0;
BA_ "GenMsgCycleTime" BO_ 2566701822 1000;
BA_ "GenMsgSendType" BO_ 2431661310 0;
BA_ "GenMsgCycleTime" BO_ 2431661310 50;
BA_ "GenMsgSendType" BO_ 2431661054 0;
BA_ "GenMsgCycleTime" BO_ 2431661054 50;
BA_ "GenMsgSendType" BO_ 2230334206 0;
BA_ "GenMsgCycleTime" BO_ 2230334206 20;
BA_ "GenMsgSendType" BO_ 2230333950 0;
BA_ "GenMsgCycleTime" BO_ 2230333950 20;
BA_ "GenMsgSendType" BO_ 2364551422 0;
BA_ "GenMsgCycleTime" BO_ 2364551422 50;
BA_ "GenMsgSendType" BO_ 2566730238 0;
BA_ "GenMsgCycleTime" BO_ 2566730238 1000;
BA_ "GenMsgSendType" BO_ 2566711038 0;
BA_ "GenMsgCycleTime" BO_ 2566711038 500;
BA_ "GenMsgSendType" BO_ 2566710782 0;
BA_ "GenMsgCycleTime" BO_ 2566710782 30000;
BA_ "GenMsgSendType" BO_ 2566710526 0;
BA_ "GenMsgCycleTime" BO_ 2566710526 30000;
BA_ "GenMsgSendType" BO_ 2432492542 0;
BA_ "GenMsgCycleTime" BO_ 2432492542 100;
BA_ "GenMsgSendType" BO_ 2566710014 0;
BA_ "GenMsgCycleTime" BO_ 2566710014 1000;
BA_ "GenMsgSendType" BO_ 2566709758 0;
BA_ "GenMsgCycleTime" BO_ 2566709758 100;
BA_ "GenMsgSendType" BO_ 2566709502 0;
BA_ "GenMsgCycleTime" BO_ 2566709502 100;
BA_ "GenMsgSendType" BO_ 2566709246 0;
BA_ "GenMsgCycleTime" BO_ 2566709246 500;
BA_ "GenMsgSendType" BO_ 2566708990 0;
BA_ "GenMsgCycleTime" BO_ 2566708990 500;
BA_ "GenMsgSendType" BO_ 2566708734 0;
BA_ "GenMsgCycleTime" BO_ 2566708734 500;
BA_ "GenMsgSendType" BO_ 2566708478 0;
BA_ "GenMsgCycleTime" BO_ 2566708478 1000;
BA_ "GenMsgSendType" BO_ 2566708222 0;
BA_ "GenMsgCycleTime" BO_ 2566708222 1000;
BA_ "GenMsgSendType" BO_ 2566707966 0;
BA_ "GenMsgCycleTime" BO_ 2566707966 1000;
BA_ "GenMsgSendType" BO_ 2566707710 0;
BA_ "GenMsgCycleTime" BO_ 2566707710 1000;
BA_ "GenMsgSendType" BO_ 2297441790 0;
BA_ "GenMsgCycleTime" BO_ 2297441790 10;
BA_ "GenMsgSendType" BO_ 2364549630 0;
BA_ "GenMsgCycleTime" BO_ 2364549630 10;
BA_ "GenMsgSendType" BO_ 2499614462 0;
BA_ "GenMsgCycleTime" BO_ 2499614462 5000;
BA_ "GenMsgSendType" BO_ 2560098046 0;
BA_ "GenMsgCycleTime" BO_ 2560098046 10000;
BA_ "GenMsgSendType" BO_ 2560163582 0;
BA_ "GenMsgCycleTime" BO_ 2560163582 10000;
BA_ "GenMsgSendType" BO_ 2297441534 0;
BA_ "GenMsgCycleTime" BO_ 2297441534 50;
BA_ "SigType" SG_ 3221225472 AETCTorqueValue 1;
BA_ "SPN" SG_ 3221225472 AETCTorqueValue 3561;
BA_ "SigType" SG_ 3221225472 TrailerWeight 1;
BA_ "SPN" SG_ 3221225472 TrailerWeight 180;
BA_ "SPN" SG_ 3221225472 ReferenceTirePressSetting 3193;
BA_ "SPN" SG_ 3221225472 ReferenceTirePress 3191;
BA_ "SPN" SG_ 3221225472 TirePressThresholdDetection 2587;
BA_ "SigType" SG_ 3221225472 TireAirLeakageRate 1;
BA_ "SPN" SG_ 3221225472 TireAirLeakageRate 2586;
BA_ "SigType" SG_ 3221225472 CTIWheelEndElectricalFault 4;
BA_ "SPN" SG_ 3221225472 CTIWheelEndElectricalFault 1697;
BA_ "SigType" SG_ 3221225472 CTITireStatus 4;
BA_ "SPN" SG_ 3221225472 CTITireStatus 1698;
BA_ "SigType" SG_ 3221225472 CTIWheelSensorStatus 4;
BA_ "SPN" SG_ 3221225472 CTIWheelSensorStatus 1699;
BA_ "SigType" SG_ 3221225472 TireTemp 1;
BA_ "SPN" SG_ 3221225472 TireTemp 242;
BA_ "SigType" SG_ 3221225472 TirePress 1;
BA_ "SPN" SG_ 3221225472 TirePress 241;
BA_ "SigType" SG_ 3221225472 EngTurningGearEngaged 4;
BA_ "SPN" SG_ 3221225472 EngTurningGearEngaged 1206;
BA_ "SigType" SG_ 3221225472 AETCSpeedValue 1;
BA_ "SPN" SG_ 3221225472 AETCSpeedValue 3560;
BA_ "SigType" SG_ 3221225472 FlashRedStopLamp 4;
BA_ "SPN" SG_ 3221225472 FlashRedStopLamp 3039;
BA_ "SigType" SG_ 3221225472 FlashProtectLamp 4;
BA_ "SPN" SG_ 3221225472 FlashProtectLamp 3041;
BA_ "SigType" SG_ 3221225472 FlashMalfuncIndicatorLamp 4;
BA_ "SPN" SG_ 3221225472 FlashMalfuncIndicatorLamp 3038;
BA_ "SigType" SG_ 3221225472 FlashAmberWarningLamp 4;
BA_ "SPN" SG_ 3221225472 FlashAmberWarningLamp 3040;
BA_ "SigType" SG_ 3221225472 MalfunctionIndicatorLampStatus 4;
BA_ "SPN" SG_ 3221225472 MalfunctionIndicatorLampStatus 1213;
BA_ "SigType" SG_ 3221225472 AmberWarningLampStatus 4;
BA_ "SPN" SG_ 3221225472 AmberWarningLampStatus 624;
BA_ "SigType" SG_ 3221225472 RedStopLampState 4;
BA_ "SPN" SG_ 3221225472 RedStopLampState 623;
BA_ "SigType" SG_ 3221225472 ProtectLampStatus 4;
BA_ "SPN" SG_ 3221225472 ProtectLampStatus 987;
BA_ "SigType" SG_ 3221225472 DTC5 7;
BA_ "SigType" SG_ 3221225472 DTC4 7;
BA_ "SigType" SG_ 3221225472 DTC3 7;
BA_ "SigType" SG_ 3221225472 DTC2 7;
BA_ "SigType" SG_ 3221225472 DTC1 7;
BA_ "SigType" SG_ 2566834691 FlashRedStopLamp 4;
BA_ "SPN" SG_ 2566834691 FlashRedStopLamp 3039;
BA_ "SigType" SG_ 2566834691 FlashProtectLamp 4;
BA_ "SPN" SG_ 2566834691 FlashProtectLamp 3041;
BA_ "SigType" SG_ 2566834691 FlashMalfuncIndicatorLamp 4;
BA_ "SPN" SG_ 2566834691 FlashMalfuncIndicatorLamp 3038;
BA_ "SigType" SG_ 2566834691 FlashAmberWarningLamp 4;
BA_ "SPN" SG_ 2566834691 FlashAmberWarningLamp 3040;
BA_ "SigType" SG_ 2566834691 MalfunctionIndicatorLampStatus 4;
BA_ "SPN" SG_ 2566834691 MalfunctionIndicatorLampStatus 1213;
BA_ "SigType" SG_ 2566834691 AmberWarningLampStatus 4;
BA_ "SPN" SG_ 2566834691 AmberWarningLampStatus 624;
BA_ "SigType" SG_ 2566834691 RedStopLampState 4;
BA_ "SPN" SG_ 2566834691 RedStopLampState 623;
BA_ "SigType" SG_ 2566834691 ProtectLampStatus 4;
BA_ "SPN" SG_ 2566834691 ProtectLampStatus 987;
BA_ "SigType" SG_ 2566834691 DTC1 7;
BA_ "SigType" SG_ 2566834699 FlashRedStopLamp 4;
BA_ "SPN" SG_ 2566834699 FlashRedStopLamp 3039;
BA_ "SigType" SG_ 2566834699 FlashProtectLamp 4;
BA_ "SPN" SG_ 2566834699 FlashProtectLamp 3041;
BA_ "SigType" SG_ 2566834699 FlashMalfuncIndicatorLamp 4;
BA_ "SPN" SG_ 2566834699 FlashMalfuncIndicatorLamp 3038;
BA_ "SigType" SG_ 2566834699 FlashAmberWarningLamp 4;
BA_ "SPN" SG_ 2566834699 FlashAmberWarningLamp 3040;
BA_ "SigType" SG_ 2566834699 MalfunctionIndicatorLampStatus 4;
BA_ "SPN" SG_ 2566834699 MalfunctionIndicatorLampStatus 1213;
BA_ "SigType" SG_ 2566834699 AmberWarningLampStatus 4;
BA_ "SPN" SG_ 2566834699 AmberWarningLampStatus 624;
BA_ "SigType" SG_ 2566834699 RedStopLampState 4;
BA_ "SPN" SG_ 2566834699 RedStopLampState 623;
BA_ "SigType" SG_ 2566834699 ProtectLampStatus 4;
BA_ "SPN" SG_ 2566834699 ProtectLampStatus 987;
BA_ "SigType" SG_ 2566834699 DTC1 7;
BA_ "SigType" SG_ 2566834688 FlashRedStopLamp 4;
BA_ "SPN" SG_ 2566834688 FlashRedStopLamp 3039;
BA_ "SigType" SG_ 2566834688 FlashProtectLamp 4;
BA_ "SPN" SG_ 2566834688 FlashProtectLamp 3041;
BA_ "SigType" SG_ 2566834688 FlashMalfuncIndicatorLamp 4;
BA_ "SPN" SG_ 2566834688 FlashMalfuncIndicatorLamp 3038;
BA_ "SigType" SG_ 2566834688 FlashAmberWarningLamp 4;
BA_ "SPN" SG_ 2566834688 FlashAmberWarningLamp 3040;
BA_ "SigType" SG_ 2566834688 MalfunctionIndicatorLampStatus 4;
BA_ "SPN" SG_ 2566834688 MalfunctionIndicatorLampStatus 1213;
BA_ "SigType" SG_ 2566834688 AmberWarningLampStatus 4;
BA_ "SPN" SG_ 2566834688 AmberWarningLampStatus 624;
BA_ "SigType" SG_ 2566834688 RedStopLampState 4;
BA_ "SPN" SG_ 2566834688 RedStopLampState 623;
BA_ "SigType" SG_ 2566834688 ProtectLampStatus 4;
BA_ "SPN" SG_ 2566834688 ProtectLampStatus 987;
BA_ "SigType" SG_ 2566834688 DTC1 7;
BA_ "SigType" SG_ 2566910720 WaterInFuelIndicator 4;
BA_ "SPN" SG_ 2566910720 WaterInFuelIndicator 97;
BA_ "SigType" SG_ 2566805053 Aftrtrtmnt1DslExhstFlidTankLevel 1;
BA_ "SPN" SG_ 2566805053 Aftrtrtmnt1DslExhstFlidTankLevel 1761;
BA_ "SigType" SG_ 2566804992 Aftrtrtmnt1DslExhstFlidTankLevel 1;
BA_ "SPN" SG_ 2566804992 Aftrtrtmnt1DslExhstFlidTankLevel 1761;
BA_ "SigType" SG_ 2566844160 EngCoolantLevel 1;
BA_ "SPN" SG_ 2566844160 EngCoolantLevel 111;
BA_ "SigType" SG_ 2566844160 EngCoolantPress 1;
BA_ "SPN" SG_ 2566844160 EngCoolantPress 109;
BA_ "SigType" SG_ 2566844160 EngCrankcasePress 1;
BA_ "SPN" SG_ 2566844160 EngCrankcasePress 101;
BA_ "SigType" SG_ 2566844160 EngOilPress 1;
BA_ "SPN" SG_ 2566844160 EngOilPress 100;
BA_ "SigType" SG_ 2566844160 EngOilLevel 1;
BA_ "SPN" SG_ 2566844160 EngOilLevel 98;
BA_ "SigType" SG_ 2566844160 EngExCrankcaseBlowbyPress 1;
BA_ "SPN" SG_ 2566844160 EngExCrankcaseBlowbyPress 22;
BA_ "SigType" SG_ 2566844160 EngFuelDeliveryPress 1;
BA_ "SPN" SG_ 2566844160 EngFuelDeliveryPress 94;
BA_ "SigType" SG_ 2566843904 EngIntercoolerThermostatOpening 1;
BA_ "SPN" SG_ 2566843904 EngIntercoolerThermostatOpening 1134;
BA_ "SigType" SG_ 2566843904 EngIntercoolerTemp 1;
BA_ "SPN" SG_ 2566843904 EngIntercoolerTemp 52;
BA_ "SigType" SG_ 2566843904 EngTurboOilTemp 1;
BA_ "SPN" SG_ 2566843904 EngTurboOilTemp 176;
BA_ "SigType" SG_ 2566843904 EngOilTemp1 1;
BA_ "SPN" SG_ 2566843904 EngOilTemp1 175;
BA_ "SigType" SG_ 2566843904 EngFuelTemp1 1;
BA_ "SPN" SG_ 2566843904 EngFuelTemp1 174;
BA_ "SigType" SG_ 2566843904 EngCoolantTemp 1;
BA_ "SPN" SG_ 2566843904 EngCoolantTemp 110;
BA_ "SigType" SG_ 2566844672 EngShutdownOverrideSwitch 4;
BA_ "SPN" SG_ 2566844672 EngShutdownOverrideSwitch 1237;
BA_ "SigType" SG_ 2566844672 EngTestModeSwitch 4;
BA_ "SPN" SG_ 2566844672 EngTestModeSwitch 966;
BA_ "SigType" SG_ 2566844672 EngIdleDecrementSwitch 4;
BA_ "SPN" SG_ 2566844672 EngIdleDecrementSwitch 967;
BA_ "SigType" SG_ 2566844672 EngIdleIncrementSwitch 4;
BA_ "SPN" SG_ 2566844672 EngIdleIncrementSwitch 968;
BA_ "SPN" SG_ 2566844672 CruiseCtrlStates 527;
BA_ "SPN" SG_ 2566844672 PTOGovernorState 976;
BA_ "SigType" SG_ 2566844672 CruiseCtrlSetSpeed 1;
BA_ "SPN" SG_ 2566844672 CruiseCtrlSetSpeed 86;
BA_ "SigType" SG_ 2566844672 CruiseCtrlAccelerateSwitch 4;
BA_ "SPN" SG_ 2566844672 CruiseCtrlAccelerateSwitch 602;
BA_ "SigType" SG_ 2566844672 CruiseCtrlResumeSwitch 4;
BA_ "SPN" SG_ 2566844672 CruiseCtrlResumeSwitch 601;
BA_ "SigType" SG_ 2566844672 CruiseCtrlCoastSwitch 4;
BA_ "SPN" SG_ 2566844672 CruiseCtrlCoastSwitch 600;
BA_ "SigType" SG_ 2566844672 CruiseCtrlSetSwitch 4;
BA_ "SPN" SG_ 2566844672 CruiseCtrlSetSwitch 599;
BA_ "SigType" SG_ 2566844672 ClutchSwitch 4;
BA_ "SPN" SG_ 2566844672 ClutchSwitch 598;
BA_ "SigType" SG_ 2566844672 BrakeSwitch 4;
BA_ "SPN" SG_ 2566844672 BrakeSwitch 597;
BA_ "SigType" SG_ 2566844672 CruiseCtrlEnableSwitch 4;
BA_ "SPN" SG_ 2566844672 CruiseCtrlEnableSwitch 596;
BA_ "SigType" SG_ 2566844672 CruiseCtrlActive 4;
BA_ "SPN" SG_ 2566844672 CruiseCtrlActive 595;
BA_ "SigType" SG_ 2566844672 WheelBasedVehicleSpeed 1;
BA_ "SPN" SG_ 2566844672 WheelBasedVehicleSpeed 84;
BA_ "SigType" SG_ 2566844672 ParkBrakeReleaseInhibitRq 5;
BA_ "SPN" SG_ 2566844672 ParkBrakeReleaseInhibitRq 3807;
BA_ "SigType" SG_ 2566844672 CruiseCtrlPauseSwitch 4;
BA_ "SPN" SG_ 2566844672 CruiseCtrlPauseSwitch 1633;
BA_ "SigType" SG_ 2566844672 ParkingBrakeSwitch 4;
BA_ "SPN" SG_ 2566844672 ParkingBrakeSwitch 70;
BA_ "SigType" SG_ 2566844672 TwoSpeedAxleSwitch 4;
BA_ "SPN" SG_ 2566844672 TwoSpeedAxleSwitch 69;
BA_ "SigType" SG_ 2566841344 ClntLvlEngPrtctionShutdownStatus 5;
BA_ "SPN" SG_ 2566841344 ClntLvlEngPrtctionShutdownStatus 5566;
BA_ "SigType" SG_ 2566841344 PTOShutdownHasShutdownEng 5;
BA_ "SPN" SG_ 2566841344 PTOShutdownHasShutdownEng 5404;
BA_ "SigType" SG_ 2566841344 EngAirShutoffStatus 5;
BA_ "SPN" SG_ 2566841344 EngAirShutoffStatus 3667;
BA_ "SigType" SG_ 2566841344 EngOverspeedTest 4;
BA_ "SPN" SG_ 2566841344 EngOverspeedTest 2812;
BA_ "SigType" SG_ 2566841344 EngAirShutoffCmdStatus 5;
BA_ "SPN" SG_ 2566841344 EngAirShutoffCmdStatus 2813;
BA_ "SigType" SG_ 2566841344 EngAlarmOutputCmdStatus 5;
BA_ "SPN" SG_ 2566841344 EngAlarmOutputCmdStatus 2814;
BA_ "SigType" SG_ 2566841344 EngAlarmAcknowledge 4;
BA_ "SPN" SG_ 2566841344 EngAlarmAcknowledge 2815;
BA_ "SigType" SG_ 2566841344 EngProtectionSystemConfig 5;
BA_ "SPN" SG_ 2566841344 EngProtectionSystemConfig 1111;
BA_ "SigType" SG_ 2566841344 EngProtectionSystemTimerState 5;
BA_ "SPN" SG_ 2566841344 EngProtectionSystemTimerState 1107;
BA_ "SigType" SG_ 2566841344 EngProtectionSystemTimerOverride 5;
BA_ "SPN" SG_ 2566841344 EngProtectionSystemTimerOverride 1108;
BA_ "SigType" SG_ 2566841344 EngPrtctnSystmApprachingShutdown 5;
BA_ "SPN" SG_ 2566841344 EngPrtctnSystmApprachingShutdown 1109;
BA_ "SigType" SG_ 2566841344 EngPrtectionSystemHasShutdownEng 5;
BA_ "SPN" SG_ 2566841344 EngPrtectionSystemHasShutdownEng 1110;
BA_ "SigType" SG_ 2566841344 EngWaitToStartLamp 5;
BA_ "SPN" SG_ 2566841344 EngWaitToStartLamp 1081;
BA_ "SigType" SG_ 2566841344 RefrigerantHighPressSwitch 4;
BA_ "SPN" SG_ 2566841344 RefrigerantHighPressSwitch 605;
BA_ "SigType" SG_ 2566841344 RefrigerantLowPressSwitch 4;
BA_ "SPN" SG_ 2566841344 RefrigerantLowPressSwitch 875;
BA_ "SigType" SG_ 2566841344 A_CHighPressFanSwitch 4;
BA_ "SPN" SG_ 2566841344 A_CHighPressFanSwitch 985;
BA_ "SigType" SG_ 2566841344 EngIdleShutdownTimerFunction 4;
BA_ "SPN" SG_ 2566841344 EngIdleShutdownTimerFunction 591;
BA_ "SigType" SG_ 2566841344 EngIdleShutdownTimerState 5;
BA_ "SPN" SG_ 2566841344 EngIdleShutdownTimerState 590;
BA_ "SigType" SG_ 2566841344 EngIdleShutdownTimerOverride 5;
BA_ "SPN" SG_ 2566841344 EngIdleShutdownTimerOverride 592;
BA_ "SigType" SG_ 2566841344 EngIdleShutdownDriverAlertMode 5;
BA_ "SPN" SG_ 2566841344 EngIdleShutdownDriverAlertMode 594;
BA_ "SigType" SG_ 2566841344 EngIdleShutdownHasShutdownEng 5;
BA_ "SPN" SG_ 2566841344 EngIdleShutdownHasShutdownEng 593;
BA_ "SigType" SG_ 2566803211 TrailerVDCActive 5;
BA_ "SPN" SG_ 2566803211 TrailerVDCActive 5624;
BA_ "SigType" SG_ 2566803211 YCBrakeCtrlActive 5;
BA_ "SPN" SG_ 2566803211 YCBrakeCtrlActive 1819;
BA_ "SigType" SG_ 2566803211 YCEngCtrlActive 5;
BA_ "SPN" SG_ 2566803211 YCEngCtrlActive 1817;
BA_ "SigType" SG_ 2566803211 ROPBrakeCtrlActive 5;
BA_ "SPN" SG_ 2566803211 ROPBrakeCtrlActive 1818;
BA_ "SigType" SG_ 2566803211 ROPEngCtrlActive 5;
BA_ "SPN" SG_ 2566803211 ROPEngCtrlActive 1816;
BA_ "SigType" SG_ 2566803211 VDCBrakeLightRq 5;
BA_ "SPN" SG_ 2566803211 VDCBrakeLightRq 1815;
BA_ "SigType" SG_ 2566803211 VDCFullyOperational 5;
BA_ "SPN" SG_ 2566803211 VDCFullyOperational 1814;
BA_ "SigType" SG_ 2566803211 VDCInformationSignal 5;
BA_ "SPN" SG_ 2566803211 VDCInformationSignal 1813;
BA_ "SPN" SG_ 2566848256 EmssnCtrlSystmOprtrIndcmntSvrity 5826;
BA_ "SPN" SG_ 2566848256 DrvrWarningSystemIndicatorStatus 5825;
BA_ "SigType" SG_ 2566848256 OperatorShiftPrompt 5;
BA_ "SPN" SG_ 2566848256 OperatorShiftPrompt 5675;
BA_ "SigType" SG_ 2566848256 WaterInFuelIndicator 4;
BA_ "SPN" SG_ 2566848256 WaterInFuelIndicator 97;
BA_ "SigType" SG_ 2364539904 EngDemandPercentTorque 1;
BA_ "SPN" SG_ 2364539904 EngDemandPercentTorque 2432;
BA_ "SPN" SG_ 2364539904 EngStarterMode 1675;
BA_ "SPN" SG_ 2364539904 SrcAddrssOfCntrllngDvcForEngCtrl 1483;
BA_ "SigType" SG_ 2364539904 EngSpeed 1;
BA_ "SPN" SG_ 2364539904 EngSpeed 190;
BA_ "SigType" SG_ 2364539904 ActualEngPercentTorque 1;
BA_ "SPN" SG_ 2364539904 ActualEngPercentTorque 513;
BA_ "SigType" SG_ 2364539904 DriversDemandEngPercentTorque 1;
BA_ "SPN" SG_ 2364539904 DriversDemandEngPercentTorque 512;
BA_ "SPN" SG_ 2364539904 ActlEngPrcntTorqueHighResolution 4154;
BA_ "SPN" SG_ 2364539904 EngTorqueMode 899;
BA_ "SystemSignalLongSymbol" SG_ 2559835902 ArbitraryAddressCapableQualifier "ArbitraryAddressCapableQualifierFlag";
BA_ "SystemSignalLongSymbol" SG_ 2559835902 VehicleSystemInstanceQualifierFl "VehicleSystemInstanceQualifierFlag";
BA_ "SigType" SG_ 2559115006 WirelessSignalStrength2 1;
BA_ "SPN" SG_ 2559115006 WirelessSignalStrength2 5757;
BA_ "SPN" SG_ 2559115006 TransmitterID2 5756;
BA_ "SigType" SG_ 2559115006 RadioBeaconDirection 5;
BA_ "SPN" SG_ 2559115006 RadioBeaconDirection 5755;
BA_ "SPN" SG_ 2559115006 UnqBeaconMessageIdentifierNumber 5754;
BA_ "SPN" SG_ 2566707454 Aftrtrtmnt1DslPrtcltFltr2StS5647 5647;
BA_ "SPN" SG_ 2566707454 Aftrtrtmnt1DslPrtcltFltr2StS5646 5646;
BA_ "SPN" SG_ 2566707454 Aftrtrtmnt1DslPrtcltFltr2StS5645 5645;
BA_ "SPN" SG_ 2566707454 Aftrtrtmnt1DslPrtcltFltr2StSnsrA 5644;
BA_ "SPN" SG_ 2566707198 Aftrtrtmnt1DslPrtcltFltr2StS5651 5651;
BA_ "SPN" SG_ 2566707198 Aftrtrtmnt1DslPrtcltFltr2StS5650 5650;
BA_ "SPN" SG_ 2566707198 Aftrtrtmnt1DslPrtcltFltr2StSnsrF 5649;
BA_ "SPN" SG_ 2566707198 Aftrtrtmnt1DslPrtcltFltr2StSnsrA 5648;
BA_ "SPN" SG_ 2566706942 Aftrtrtmnt1DslPrtcltFltr2StS5655 5655;
BA_ "SPN" SG_ 2566706942 Aftrtrtmnt1DslPrtcltFltr2StS5654 5654;
BA_ "SPN" SG_ 2566706942 Aftrtrtmnt1DslPrtcltFltr2StSnsrF 5653;
BA_ "SPN" SG_ 2566706942 Aftrtrtmnt1DslPrtcltFltr2StSnsrA 5652;
BA_ "SigType" SG_ 2559770366 HydrocarbonDoserPurgingRequired 5;
BA_ "SPN" SG_ 2559770366 HydrocarbonDoserPurgingRequired 5509;
BA_ "SPN" SG_ 2559770366 DiagnosticStatusOfHCDoser 5508;
BA_ "SigType" SG_ 2559770366 HCDoserInjectingStatus 5;
BA_ "SPN" SG_ 2559770366 HCDoserInjectingStatus 5507;
BA_ "SPN" SG_ 2559770366 HCDoserStatus 5506;
BA_ "SigType" SG_ 2559770366 RequestedFuelMassRate 1;
BA_ "SPN" SG_ 2559770366 RequestedFuelMassRate 5505;
BA_ "SigType" SG_ 2559704830 LubricationTimingCycleCmd 5;
BA_ "SPN" SG_ 2559704830 LubricationTimingCycleCmd 5514;
BA_ "SigType" SG_ 2559704830 LubricationPumpEnableCmd 5;
BA_ "SPN" SG_ 2559704830 LubricationPumpEnableCmd 5513;
BA_ "SPN" SG_ 2559704830 LubricationOperationModeSetCmd 5512;
BA_ "SPN" SG_ 2559704830 LubricationCycleSetCmd 5511;
BA_ "SigType" SG_ 2559704830 LubricationCycleModeLockCmd 5;
BA_ "SPN" SG_ 2559704830 LubricationCycleModeLockCmd 5510;
BA_ "SigType" SG_ 2559639294 SupplementalFanPowerHold 5;
BA_ "SPN" SG_ 2559639294 SupplementalFanPowerHold 5555;
BA_ "SPN" SG_ 2559639294 SupplementalFanSpeedCmd 5554;
BA_ "SigType" SG_ 2559639294 SupplementalFanDirectionCmd 5;
BA_ "SPN" SG_ 2559639294 SupplementalFanDirectionCmd 5553;
BA_ "SigType" SG_ 2559639294 SupplementalFanEnableCmd 5;
BA_ "SPN" SG_ 2559639294 SupplementalFanEnableCmd 5552;
BA_ "SigType" SG_ 2559573758 ClntLvlEngPrtctnShtdwnOvrrideCmd 5;
BA_ "SPN" SG_ 2559573758 ClntLvlEngPrtctnShtdwnOvrrideCmd 5565;
BA_ "SigType" SG_ 2349530878 CruiseCtrlPauseCmd 5;
BA_ "SPN" SG_ 2349530878 CruiseCtrlPauseCmd 5605;
BA_ "SigType" SG_ 2349530878 CruiseCtrlResumeCmd 5;
BA_ "SPN" SG_ 2349530878 CruiseCtrlResumeCmd 5604;
BA_ "SigType" SG_ 2349530878 CruiseCtrlDisableCmd 5;
BA_ "SPN" SG_ 2349530878 CruiseCtrlDisableCmd 5603;
BA_ "SPN" SG_ 2365428734 GenFrequencySelection 4080;
BA_ "SigType" SG_ 2365428734 GenGoverningSpeedCommand 5;
BA_ "SPN" SG_ 2365428734 GenGoverningSpeedCommand 4079;
BA_ "SigType" SG_ 2365428734 GenAlternatorEfficiency 1;
BA_ "SPN" SG_ 2365428734 GenAlternatorEfficiency 4078;
BA_ "SigType" SG_ 2365428734 GenNotReadyToAutoParaState 4;
BA_ "SPN" SG_ 2365428734 GenNotReadyToAutoParaState 3568;
BA_ "SigType" SG_ 2365428734 GenCtrlNotInAutoStartState 4;
BA_ "SPN" SG_ 2365428734 GenCtrlNotInAutoStartState 3567;
BA_ "SigType" SG_ 2365428734 RequestedEngineControlMode 4;
BA_ "SPN" SG_ 2365428734 RequestedEngineControlMode 3542;
BA_ "SPN" SG_ 2365428734 EngSpeedGovernorDroop 5568;
BA_ "SPN" SG_ 2365428734 EngSpeedGovernorGainAdjust 5567;
BA_ "SigType" SG_ 2566702846 EngOBDWarmUpSequence 5;
BA_ "SPN" SG_ 2566702846 EngOBDWarmUpSequence 5843;
BA_ "SigType" SG_ 2566703102 CertificationEngineFamilyName 8;
BA_ "SPN" SG_ 2566703102 CertificationEngineFamilyName 5845;
BA_ "SigType" SG_ 2566703102 ModelYear 3;
BA_ "SPN" SG_ 2566703102 ModelYear 5844;
BA_ "SigType" SG_ 2566705918 DTC1 7;
BA_ "SigType" SG_ 2566705918 FlashProtectLamp 4;
BA_ "SPN" SG_ 2566705918 FlashProtectLamp 3041;
BA_ "SigType" SG_ 2566705918 FlashAmberWarningLamp 4;
BA_ "SPN" SG_ 2566705918 FlashAmberWarningLamp 3040;
BA_ "SigType" SG_ 2566705918 FlashRedStopLamp 4;
BA_ "SPN" SG_ 2566705918 FlashRedStopLamp 3039;
BA_ "SigType" SG_ 2566705918 FlashMalfuncIndicatorLamp 4;
BA_ "SPN" SG_ 2566705918 FlashMalfuncIndicatorLamp 3038;
BA_ "SigType" SG_ 2566705918 ProtectLampStatus 4;
BA_ "SPN" SG_ 2566705918 ProtectLampStatus 987;
BA_ "SigType" SG_ 2566705918 AmberWarningLampStatus 4;
BA_ "SPN" SG_ 2566705918 AmberWarningLampStatus 624;
BA_ "SigType" SG_ 2566705918 RedStopLampState 4;
BA_ "SPN" SG_ 2566705918 RedStopLampState 623;
BA_ "SigType" SG_ 2566705918 MalfunctionIndicatorLampStatus 4;
BA_ "SPN" SG_ 2566705918 MalfunctionIndicatorLampStatus 1213;
BA_ "SigType" SG_ 2566705918 DTC5 7;
BA_ "SigType" SG_ 2566705918 DTC4 7;
BA_ "SigType" SG_ 2566705918 DTC3 7;
BA_ "SigType" SG_ 2566705918 DTC2 7;
BA_ "SigType" SG_ 2566705662 DTC1 7;
BA_ "SigType" SG_ 2566705662 FlashProtectLamp 4;
BA_ "SPN" SG_ 2566705662 FlashProtectLamp 3041;
BA_ "SigType" SG_ 2566705662 FlashAmberWarningLamp 4;
BA_ "SPN" SG_ 2566705662 FlashAmberWarningLamp 3040;
BA_ "SigType" SG_ 2566705662 FlashRedStopLamp 4;
BA_ "SPN" SG_ 2566705662 FlashRedStopLamp 3039;
BA_ "SigType" SG_ 2566705662 FlashMalfuncIndicatorLamp 4;
BA_ "SPN" SG_ 2566705662 FlashMalfuncIndicatorLamp 3038;
BA_ "SigType" SG_ 2566705662 ProtectLampStatus 4;
BA_ "SPN" SG_ 2566705662 ProtectLampStatus 987;
BA_ "SigType" SG_ 2566705662 AmberWarningLampStatus 4;
BA_ "SPN" SG_ 2566705662 AmberWarningLampStatus 624;
BA_ "SigType" SG_ 2566705662 RedStopLampState 4;
BA_ "SPN" SG_ 2566705662 RedStopLampState 623;
BA_ "SigType" SG_ 2566705662 MalfunctionIndicatorLampStatus 4;
BA_ "SPN" SG_ 2566705662 MalfunctionIndicatorLampStatus 1213;
BA_ "SigType" SG_ 2566705662 DTC5 7;
BA_ "SigType" SG_ 2566705662 DTC4 7;
BA_ "SigType" SG_ 2566705662 DTC3 7;
BA_ "SigType" SG_ 2566705662 DTC2 7;
BA_ "SPN" SG_ 2349465342 StaticRollAngleStatus 5583;
BA_ "SigType" SG_ 2349465342 StaticRollAngle 1;
BA_ "SPN" SG_ 2349465342 StaticRollAngle 5582;
BA_ "SigType" SG_ 2566767614 AccelPedal2Channel3 1;
BA_ "SPN" SG_ 2566767614 AccelPedal2Channel3 2626;
BA_ "SigType" SG_ 2566767614 AccelPedal2Channel2 1;
BA_ "SPN" SG_ 2566767614 AccelPedal2Channel2 2625;
BA_ "SigType" SG_ 2566767614 AccelPedal1Channel3 1;
BA_ "SPN" SG_ 2566767614 AccelPedal1Channel3 2624;
BA_ "SigType" SG_ 2566767614 AccelPedal1Channel2 1;
BA_ "SPN" SG_ 2566767614 AccelPedal1Channel2 2623;
BA_ "SigType" SG_ 2559049470 DesiredEngFuelingState 5;
BA_ "SPN" SG_ 2559049470 DesiredEngFuelingState 5793;
BA_ "SPN" SG_ 2349596414 AEBS2MessageChecksum 5683;
BA_ "SPN" SG_ 2349596414 AEBS2MessageCounter 5682;
BA_ "SigType" SG_ 2349596414 DrvrActvtnDmndFrAdvncdEmrgncyBrk 5;
BA_ "SPN" SG_ 2349596414 DrvrActvtnDmndFrAdvncdEmrgncyBrk 5681;
BA_ "SPN" SG_ 2566767358 FuelType 5837;
BA_ "SigType" SG_ 2566767358 EngFuelMassFlowRate 1;
BA_ "SPN" SG_ 2566767358 EngFuelMassFlowRate 5833;
BA_ "SPN" SG_ 2566767358 EngExhstGsRcrcltn1Valve2PosError 5830;
BA_ "SPN" SG_ 2566767358 EngExhstGsRcrcltn1Valve1PosError 5829;
BA_ "SigType" SG_ 2566706686 Aftrtrtmnt1DslExhstFldPumpHeater 1;
BA_ "SPN" SG_ 2566706686 Aftrtrtmnt1DslExhstFldPumpHeater 5706;
BA_ "SigType" SG_ 2566705406 Aftertreatment2ParticulateSensor 1;
BA_ "SPN" SG_ 2566705406 Aftertreatment2ParticulateSensor 5836;
BA_ "SigType" SG_ 2566705406 Aftertreatment1ParticulateSensor 1;
BA_ "SPN" SG_ 2566705406 Aftertreatment1ParticulateSensor 5835;
BA_ "SPN" SG_ 2566705150 NOxSnsorATI2SelfdiagnosisTrigger 5712;
BA_ "SPN" SG_ 2566705150 NOxSnsorATO2SelfdiagnosisTrigger 5711;
BA_ "SPN" SG_ 2566705150 NOxSnsorATI1SelfdiagnosisTrigger 5710;
BA_ "SPN" SG_ 2566705150 NOxSnsorATO1SelfdiagnosisTrigger 5709;
BA_ "SigType" SG_ 2566704382 Aftrtrtmnt2OtltGsSnsrPowerSupply 5;
BA_ "SPN" SG_ 2566704382 Aftrtrtmnt2OtltGsSnsrPowerSupply 5761;
BA_ "SigType" SG_ 2566704382 Aftrtrtmnt2IntkGsSnsrPowerSupply 5;
BA_ "SPN" SG_ 2566704382 Aftrtrtmnt2IntkGsSnsrPowerSupply 5760;
BA_ "SigType" SG_ 2566704382 Aftrtrtmnt1OtltGsSnsrPowerSupply 5;
BA_ "SPN" SG_ 2566704382 Aftrtrtmnt1OtltGsSnsrPowerSupply 5759;
BA_ "SigType" SG_ 2566704382 Aftrtrtmnt1IntkGsSnsrPowerSupply 5;
BA_ "SPN" SG_ 2566704382 Aftrtrtmnt1IntkGsSnsrPowerSupply 5758;
BA_ "SPN" SG_ 2566704126 EngExhstGsRcrcltn1Acttr2PrlmnryF 5767;
BA_ "SPN" SG_ 2566704126 EngExhstGsRcrcltn1Acttr2OprtnStt 5772;
BA_ "SPN" SG_ 2566704126 EngExhstGsRcrcltn1Acttr1OprtnStt 5771;
BA_ "SPN" SG_ 2566704126 EngExhstGsRcrcltn1Acttr2DsredPos 5770;
BA_ "SigType" SG_ 2566704126 EngExhstGsRcrclton1Actuator2Temp 1;
BA_ "SPN" SG_ 2566704126 EngExhstGsRcrclton1Actuator2Temp 5769;
BA_ "SPN" SG_ 2566704126 EngExhstGsRcrcltn1Acttr2TmpSttus 5768;
BA_ "SPN" SG_ 2566704126 EngExhstGsRcrcltn1Acttr1DsredPos 5766;
BA_ "SigType" SG_ 2566704126 EngExhstGsRcrclton1Actuator1Temp 1;
BA_ "SPN" SG_ 2566704126 EngExhstGsRcrclton1Actuator1Temp 5765;
BA_ "SPN" SG_ 2566704126 EngExhstGsRcrcltn1Acttr1TmpSttus 5764;
BA_ "SPN" SG_ 2566704126 EngExhstGsRcrcltn1Acttr1PrlmnryF 5763;
BA_ "SPN" SG_ 2566703870 EngExhstGsRcrcltn2Acttr2OprtnStt 5782;
BA_ "SPN" SG_ 2566703870 EngExhstGsRcrcltn2Acttr1OprtnStt 5781;
BA_ "SPN" SG_ 2566703870 EngExhstGsRcrcltn2Acttr2DsredPos 5780;
BA_ "SigType" SG_ 2566703870 EngExhstGsRcrclton2Actuator2Temp 1;
BA_ "SPN" SG_ 2566703870 EngExhstGsRcrclton2Actuator2Temp 5779;
BA_ "SPN" SG_ 2566703870 EngExhstGsRcrcltn2Acttr2TmpSttus 5778;
BA_ "SPN" SG_ 2566703870 EngExhstGsRcrcltn2Acttr2PrlmnryF 5777;
BA_ "SPN" SG_ 2566703870 EngExhstGsRcrcltn2Acttr1DsredPos 5776;
BA_ "SigType" SG_ 2566703870 EngExhstGsRcrclton2Actuator1Temp 1;
BA_ "SPN" SG_ 2566703870 EngExhstGsRcrclton2Actuator1Temp 5775;
BA_ "SPN" SG_ 2566703870 EngExhstGsRcrcltn2Acttr1TmpSttus 5774;
BA_ "SPN" SG_ 2566703870 EngExhstGsRcrcltn2Acttr1PrlmnryF 5773;
BA_ "SigType" SG_ 2566703614 EngTurboWastegateActuator2Temp 1;
BA_ "SPN" SG_ 2566703614 EngTurboWastegateActuator2Temp 5787;
BA_ "SigType" SG_ 2566703614 EngFuelValve2Temp 1;
BA_ "SPN" SG_ 2566703614 EngFuelValve2Temp 5786;
BA_ "SigType" SG_ 2566703614 EngFuelValve1Temp 1;
BA_ "SPN" SG_ 2566703614 EngFuelValve1Temp 5785;
BA_ "SigType" SG_ 2566703614 EngThrottleValve2Temp 1;
BA_ "SPN" SG_ 2566703614 EngThrottleValve2Temp 5784;
BA_ "SigType" SG_ 2566703614 EngThrottleValve1Temp 1;
BA_ "SPN" SG_ 2566703614 EngThrottleValve1Temp 5783;
BA_ "SPN" SG_ 2566703358 EngFuelingInhibitPreventedReason 5866;
BA_ "SigType" SG_ 2566703358 EngFuelingInhibitAllowed 5;
BA_ "SPN" SG_ 2566703358 EngFuelingInhibitAllowed 5795;
BA_ "SigType" SG_ 2566703358 FeedbackEngFuelingState 5;
BA_ "SPN" SG_ 2566703358 FeedbackEngFuelingState 5794;
BA_ "SPN" SG_ 2566702590 Aftrtrtmnt1SCRIntrmdtGsTmpPrlmnr 5863;
BA_ "SigType" SG_ 2566702590 Aftrtrtmnt1SCRIntrmediateGasTemp 1;
BA_ "SPN" SG_ 2566702590 Aftrtrtmnt1SCRIntrmediateGasTemp 5862;
BA_ "SPN" SG_ 2566702334 Aftrtrtmnt2SCRIntrmdtGsTmpPrlmnr 5865;
BA_ "SigType" SG_ 2566702334 Aftrtrtmnt2SCRIntrmediateGasTemp 1;
BA_ "SPN" SG_ 2566702334 Aftrtrtmnt2SCRIntrmediateGasTemp 5864;
BA_ "SigType" SG_ 2566702078 SupplyGasMethanePercentage 1;
BA_ "SPN" SG_ 2566702078 SupplyGasMethanePercentage 5867;
BA_ "SigType" SG_ 2566701822 HybridSystemStopIndicator 5;
BA_ "SPN" SG_ 2566701822 HybridSystemStopIndicator 5874;
BA_ "SigType" SG_ 2566701822 HybridSystemOverheatIndicator 5;
BA_ "SPN" SG_ 2566701822 HybridSystemOverheatIndicator 5873;
BA_ "SigType" SG_ 2566701822 HybridSystemWarningIndicator 5;
BA_ "SPN" SG_ 2566701822 HybridSystemWarningIndicator 5872;
BA_ "SigType" SG_ 2431661310 Aftrtrtmnt2SCRIntrmdtNH3GsSn5861 5;
BA_ "SPN" SG_ 2431661310 Aftrtrtmnt2SCRIntrmdtNH3GsSn5861 5861;
BA_ "SPN" SG_ 2431661310 Aftrtrtmnt2SCRIntrmdtNH3GsSnsrHt 5860;
BA_ "SPN" SG_ 2431661310 Aftrtrtmnt2SCRIntrmdtNH3GsSnsrAt 5859;
BA_ "SigType" SG_ 2431661310 Aftrtrtmnt2SCRIntrmdtNH3GsSnsrPw 5;
BA_ "SPN" SG_ 2431661310 Aftrtrtmnt2SCRIntrmdtNH3GsSnsrPw 5858;
BA_ "SigType" SG_ 2431661310 Aftrtrtmnt2SCRIntrmdtNH3RdngStbl 5;
BA_ "SPN" SG_ 2431661310 Aftrtrtmnt2SCRIntrmdtNH3RdngStbl 5857;
BA_ "SPN" SG_ 2431661310 Aftrtrtmnt2SCRIntrmdtNH3SnsrPrlm 5856;
BA_ "SigType" SG_ 2431661310 Aftrtreatment2SCRIntermediateNH3 1;
BA_ "SPN" SG_ 2431661310 Aftrtreatment2SCRIntermediateNH3 5855;
BA_ "SigType" SG_ 2431661054 Aftrtrtmnt1SCRIntrmdtNH3GsSn5854 5;
BA_ "SPN" SG_ 2431661054 Aftrtrtmnt1SCRIntrmdtNH3GsSn5854 5854;
BA_ "SPN" SG_ 2431661054 Aftrtrtmnt1SCRIntrmdtNH3GsSnsrHt 5853;
BA_ "SigType" SG_ 2431661054 Aftrtrtmnt1SCRIntrmdtNH3GsSnsrAt 5;
BA_ "SPN" SG_ 2431661054 Aftrtrtmnt1SCRIntrmdtNH3GsSnsrAt 5852;
BA_ "SigType" SG_ 2431661054 Aftrtrtmnt1SCRIntrmdtNH3GsSnsrPw 5;
BA_ "SPN" SG_ 2431661054 Aftrtrtmnt1SCRIntrmdtNH3GsSnsrPw 5851;
BA_ "SigType" SG_ 2431661054 Aftrtrtmnt1SCRIntrmdtNH3RdngStbl 5;
BA_ "SPN" SG_ 2431661054 Aftrtrtmnt1SCRIntrmdtNH3RdngStbl 5850;
BA_ "SPN" SG_ 2431661054 Aftrtrtmnt1SCRIntrmdtNH3SnsrPrlm 5849;
BA_ "SigType" SG_ 2431661054 Aftrtreatment1SCRIntermediateNH3 1;
BA_ "SPN" SG_ 2431661054 Aftrtreatment1SCRIntermediateNH3 5848;
BA_ "SigType" SG_ 2230334206 LnrDsplcmntSnsrSnsrFigureOfMerit 5;
BA_ "SPN" SG_ 2230334206 LnrDsplcmntSnsrSnsrFigureOfMerit 5824;
BA_ "SigType" SG_ 2230334206 MeasuredLinearDisplacement 1;
BA_ "SPN" SG_ 2230334206 MeasuredLinearDisplacement 5823;
BA_ "SigType" SG_ 2230333950 WandSensorFigureOfMerit 5;
BA_ "SPN" SG_ 2230333950 WandSensorFigureOfMerit 5822;
BA_ "SigType" SG_ 2230333950 WandAngle 1;
BA_ "SPN" SG_ 2230333950 WandAngle 5821;
BA_ "SigType" SG_ 2364551422 WirelessSignalStrength1 1;
BA_ "SPN" SG_ 2364551422 WirelessSignalStrength1 5753;
BA_ "SPN" SG_ 2364551422 TransmitterID1 5752;
BA_ "SPN" SG_ 2364551422 TransmitterCmdState 5751;
BA_ "SPN" SG_ 2364551422 WirelessRollingMessageCounter 5750;
BA_ "SPN" SG_ 2364551166 TmeToCollisionWithRelevantObject 5680;
BA_ "SPN" SG_ 2364551166 BndOffPrbabilityOfRelevantObject 5679;
BA_ "SPN" SG_ 2364551166 RlvntObjctDtctdFrAdvncdEmrgncyBr 5678;
BA_ "SPN" SG_ 2364551166 CollisionWarningLevel 5677;
BA_ "SPN" SG_ 2364551166 AdvncdEmrgencyBrakingSystemState 5676;
BA_ "SPN" SG_ 2566730238 Fan2DriveBypassCmdStatus 1708;
BA_ "SigType" SG_ 2566730238 HydFan2MotorPress 1;
BA_ "SPN" SG_ 2566730238 HydFan2MotorPress 1707;
BA_ "SigType" SG_ 2566730238 Fan2Speed 1;
BA_ "SPN" SG_ 2566730238 Fan2Speed 1598;
BA_ "SPN" SG_ 2566730238 Fan2DriveState 1557;
BA_ "SPN" SG_ 2566730238 EstPercentFan2Speed 1550;
BA_ "SigType" SG_ 2566711038 LubricationTimingCycleStatus 5;
BA_ "SPN" SG_ 2566711038 LubricationTimingCycleStatus 5520;
BA_ "SigType" SG_ 2566711038 LubricationReservoirLevel 4;
BA_ "SPN" SG_ 2566711038 LubricationReservoirLevel 5519;
BA_ "SigType" SG_ 2566711038 LubricationPumpEnableStatus 5;
BA_ "SPN" SG_ 2566711038 LubricationPumpEnableStatus 5518;
BA_ "SPN" SG_ 2566711038 LubricationOperationModeStatus 5517;
BA_ "SPN" SG_ 2566711038 LubricationCycleModeStatus 5516;
BA_ "SigType" SG_ 2566711038 LubricationCycleModeLockStatus 5;
BA_ "SPN" SG_ 2566711038 LubricationCycleModeLockStatus 5515;
BA_ "SigType" SG_ 2566710782 HydOilTemp 1;
BA_ "SPN" SG_ 2566710782 HydOilTemp 5536;
BA_ "SigType" SG_ 2566710782 HydOilRelativeDielectricity 1;
BA_ "SPN" SG_ 2566710782 HydOilRelativeDielectricity 5535;
BA_ "SigType" SG_ 2566710782 HydOilDensity 1;
BA_ "SPN" SG_ 2566710782 HydOilDensity 5534;
BA_ "SigType" SG_ 2566710782 HydOilDynamicViscosity 1;
BA_ "SPN" SG_ 2566710782 HydOilDynamicViscosity 5533;
BA_ "SigType" SG_ 2566710526 EngFuelTemp 1;
BA_ "SPN" SG_ 2566710526 EngFuelTemp 5540;
BA_ "SigType" SG_ 2566710526 EngFuelDielectricity 1;
BA_ "SPN" SG_ 2566710526 EngFuelDielectricity 5539;
BA_ "SigType" SG_ 2566710526 EngFuelDensity 1;
BA_ "SPN" SG_ 2566710526 EngFuelDensity 5538;
BA_ "SigType" SG_ 2566710526 EngFuelDynamicViscosity 1;
BA_ "SPN" SG_ 2566710526 EngFuelDynamicViscosity 5537;
BA_ "SigType" SG_ 2432492542 DsredEngTurbo2TurbineOutletPress 1;
BA_ "SPN" SG_ 2432492542 DsredEngTurbo2TurbineOutletPress 5545;
BA_ "SigType" SG_ 2432492542 EngTurbo2TurbineOutletPress 1;
BA_ "SPN" SG_ 2432492542 EngTurbo2TurbineOutletPress 5544;
BA_ "SigType" SG_ 2432492542 EngExhaustBrakeActuatorCmd 1;
BA_ "SPN" SG_ 2432492542 EngExhaustBrakeActuatorCmd 5543;
BA_ "SigType" SG_ 2432492542 DsredEngTurbo1TurbineOutletPress 1;
BA_ "SPN" SG_ 2432492542 DsredEngTurbo1TurbineOutletPress 5542;
BA_ "SigType" SG_ 2432492542 EngTurbo1TurbineOutletPress 1;
BA_ "SPN" SG_ 2432492542 EngTurbo1TurbineOutletPress 5541;
BA_ "SigType" SG_ 2566710014 SupplementalFanPower 1;
BA_ "SPN" SG_ 2566710014 SupplementalFanPower 5564;
BA_ "SigType" SG_ 2566710014 SupplementalFanCurrent 1;
BA_ "SPN" SG_ 2566710014 SupplementalFanCurrent 5563;
BA_ "SigType" SG_ 2566710014 SupplementalFanSpeed 1;
BA_ "SPN" SG_ 2566710014 SupplementalFanSpeed 5562;
BA_ "SigType" SG_ 2566710014 SupplementalFanCtrlECUTemp 1;
BA_ "SPN" SG_ 2566710014 SupplementalFanCtrlECUTemp 5561;
BA_ "SPN" SG_ 2566710014 SupplementalFanDriveStatus 5560;
BA_ "SPN" SG_ 2566710014 SupplementalFanCtrlTempStatus 5559;
BA_ "SPN" SG_ 2566710014 SupplementalFanVelocityStatus 5558;
BA_ "SigType" SG_ 2566710014 SupplementalFanDirectionStatus 5;
BA_ "SPN" SG_ 2566710014 SupplementalFanDirectionStatus 5557;
BA_ "SigType" SG_ 2566710014 SupplementalFanEnableStatus 5;
BA_ "SPN" SG_ 2566710014 SupplementalFanEnableStatus 5556;
BA_ "SigType" SG_ 2566709758 HighResolutionEngFuelRate 1;
BA_ "SPN" SG_ 2566709758 HighResolutionEngFuelRate 1600;
BA_ "SigType" SG_ 2566709502 Aftertreatment2FuelMassRate 1;
BA_ "SPN" SG_ 2566709502 Aftertreatment2FuelMassRate 5834;
BA_ "SigType" SG_ 2566709502 Aftertreatment1FuelMassRate 1;
BA_ "SPN" SG_ 2566709502 Aftertreatment1FuelMassRate 5503;
BA_ "SigType" SG_ 2566709502 RelativeUnburnedFuelMassFromEng 1;
BA_ "SPN" SG_ 2566709502 RelativeUnburnedFuelMassFromEng 5502;
BA_ "SPN" SG_ 2566709502 Aftrtrtmnt1DslPrtcltFltrIntkTmpS 5501;
BA_ "SPN" SG_ 2566709246 EngFuelFilterDegradation 5584;
BA_ "SigType" SG_ 2566709246 EngFilteredFuelDeliveryAbsPress 1;
BA_ "SPN" SG_ 2566709246 EngFilteredFuelDeliveryAbsPress 5580;
BA_ "SigType" SG_ 2566709246 EngFilteredFuelDeliveryPress 1;
BA_ "SPN" SG_ 2566709246 EngFilteredFuelDeliveryPress 5579;
BA_ "SigType" SG_ 2566709246 EngFuelDeliveryAbsPress 1;
BA_ "SPN" SG_ 2566709246 EngFuelDeliveryAbsPress 5578;
BA_ "SigType" SG_ 2566708990 Aftertreatment1SecondAirAbsPress 1;
BA_ "SPN" SG_ 2566708990 Aftertreatment1SecondAirAbsPress 5589;
BA_ "SigType" SG_ 2566708734 Aftertreatment2SecondAirAbsPress 1;
BA_ "SPN" SG_ 2566708734 Aftertreatment2SecondAirAbsPress 5590;
BA_ "SPN" SG_ 2566708478 SrcAddrssOfCntrllngDvcFrPsngCrsC 5609;
BA_ "SPN" SG_ 2566708478 SrcAddrssOfCntrllngDvcFrDsblngCr 5608;
BA_ "SPN" SG_ 2566708478 CruiseCtrlSystemCmdState 5607;
BA_ "SigType" SG_ 2566708478 AdptiveCruiseCtrlReadinessStatus 5;
BA_ "SPN" SG_ 2566708478 AdptiveCruiseCtrlReadinessStatus 5606;
BA_ "SPN" SG_ 2566708222 Aftrtrtmnt1DslPrtcltFltr1StS5635 5635;
BA_ "SPN" SG_ 2566708222 Aftrtrtmnt1DslPrtcltFltr1StS5634 5634;
BA_ "SPN" SG_ 2566708222 Aftrtrtmnt1DslPrtcltFltr1StS5633 5633;
BA_ "SPN" SG_ 2566708222 Aftrtrtmnt1DslPrtcltFltr1StSnsrA 5632;
BA_ "SPN" SG_ 2566707966 Aftrtrtmnt1DslPrtcltFltr1StS5639 5639;
BA_ "SPN" SG_ 2566707966 Aftrtrtmnt1DslPrtcltFltr1StS5638 5638;
BA_ "SPN" SG_ 2566707966 Aftrtrtmnt1DslPrtcltFltr1StSnsrF 5637;
BA_ "SPN" SG_ 2566707966 Aftrtrtmnt1DslPrtcltFltr1StSnsrA 5636;
BA_ "SPN" SG_ 2566707710 Aftrtrtmnt1DslPrtcltFltr1StS5643 5643;
BA_ "SPN" SG_ 2566707710 Aftrtrtmnt1DslPrtcltFltr1StS5642 5642;
BA_ "SPN" SG_ 2566707710 Aftrtrtmnt1DslPrtcltFltr1StSnsrF 5641;
BA_ "SPN" SG_ 2566707710 Aftrtrtmnt1DslPrtcltFltr1StSnsrA 5640;
BA_ "SigType" SG_ 2297441790 SpprtVrblTrnsRpttnRtFrAcclrtnSns 5;
BA_ "SPN" SG_ 2297441790 SpprtVrblTrnsRpttnRtFrAcclrtnSns 5353;
BA_ "SigType" SG_ 2297441790 VrtclAcclrtnExRangeFigureOfMerit 5;
BA_ "SPN" SG_ 2297441790 VrtclAcclrtnExRangeFigureOfMerit 5352;
BA_ "SigType" SG_ 2297441790 LngtdnlAcclrtnExRngFigureOfMerit 5;
BA_ "SPN" SG_ 2297441790 LngtdnlAcclrtnExRngFigureOfMerit 5351;
BA_ "SigType" SG_ 2297441790 LtrlAcclrtonExRangeFigureOfMerit 5;
BA_ "SPN" SG_ 2297441790 LtrlAcclrtonExRangeFigureOfMerit 5350;
BA_ "SigType" SG_ 2297441790 VerticalAccelerationExRange 1;
BA_ "SPN" SG_ 2297441790 VerticalAccelerationExRange 5349;
BA_ "SigType" SG_ 2297441790 LongitudinalAccelerationExRange 1;
BA_ "SPN" SG_ 2297441790 LongitudinalAccelerationExRange 5348;
BA_ "SigType" SG_ 2297441790 LateralAccelerationExRange 1;
BA_ "SPN" SG_ 2297441790 LateralAccelerationExRange 5347;
BA_ "SigType" SG_ 2566712062 HybridBatteryPackRemainingCharge 1;
BA_ "SPN" SG_ 2566712062 HybridBatteryPackRemainingCharge 5464;
BA_ "SigType" SG_ 2364549630 RllAndPtchExRngMasurementLatency 1;
BA_ "SPN" SG_ 2364549630 RllAndPtchExRngMasurementLatency 4982;
BA_ "SigType" SG_ 2364549630 RollAngleExRangeFigureOfMerit 5;
BA_ "SPN" SG_ 2364549630 RollAngleExRangeFigureOfMerit 4981;
BA_ "SigType" SG_ 2364549630 RollAngleExRangeCompensation 5;
BA_ "SPN" SG_ 2364549630 RollAngleExRangeCompensation 4980;
BA_ "SigType" SG_ 2364549630 PitchAngleExRangeFigureOfMerit 5;
BA_ "SPN" SG_ 2364549630 PitchAngleExRangeFigureOfMerit 4979;
BA_ "SigType" SG_ 2364549630 PitchAngleExRangeCompensation 5;
BA_ "SPN" SG_ 2364549630 PitchAngleExRangeCompensation 4978;
BA_ "SPN" SG_ 2364549630 RollAngleExRange 4977;
BA_ "SPN" SG_ 2364549630 PitchAngleExRange 4976;
BA_ "SigType" SG_ 2499614462 OccpntClssficationSystem10Status 5;
BA_ "SPN" SG_ 2499614462 OccpntClssficationSystem10Status 4972;
BA_ "SigType" SG_ 2499614462 OccpntClssificationSystem9Status 5;
BA_ "SPN" SG_ 2499614462 OccpntClssificationSystem9Status 4971;
BA_ "SigType" SG_ 2499614462 OccpntClssificationSystem8Status 5;
BA_ "SPN" SG_ 2499614462 OccpntClssificationSystem8Status 4970;
BA_ "SigType" SG_ 2499614462 OccpntClssificationSystem7Status 5;
BA_ "SPN" SG_ 2499614462 OccpntClssificationSystem7Status 4969;
BA_ "SigType" SG_ 2499614462 OccpntClssificationSystem6Status 5;
BA_ "SPN" SG_ 2499614462 OccpntClssificationSystem6Status 4968;
BA_ "SigType" SG_ 2499614462 OccpntClssificationSystem5Status 5;
BA_ "SPN" SG_ 2499614462 OccpntClssificationSystem5Status 4967;
BA_ "SigType" SG_ 2499614462 OccpntClssificationSystem4Status 5;
BA_ "SPN" SG_ 2499614462 OccpntClssificationSystem4Status 4966;
BA_ "SigType" SG_ 2499614462 OccpntClssificationSystem3Status 5;
BA_ "SPN" SG_ 2499614462 OccpntClssificationSystem3Status 4965;
BA_ "SPN" SG_ 2499614462 PssngrOccpntClssfctnSystemStatus 4964;
BA_ "SPN" SG_ 2499614462 DrvrOccpntClssfctionSystemStatus 4963;
BA_ "SPN" SG_ 2560098046 CabNoiseCtrlTuningStatus 5060;
BA_ "SigType" SG_ 2560098046 CabNoiseCtrlStatus 5;
BA_ "SPN" SG_ 2560098046 CabNoiseCtrlStatus 5059;
BA_ "SPN" SG_ 2560163582 CabNoiseCtrlTuningCmd 5058;
BA_ "SigType" SG_ 2560163582 CabNoiseCtrlCmd 5;
BA_ "SPN" SG_ 2560163582 CabNoiseCtrlCmd 5057;
BA_ "SigType" SG_ 2297441534 MagnetGeneratorCtrl 5;
BA_ "SPN" SG_ 2297441534 MagnetGeneratorCtrl 5551;
BA_ "SigType" SG_ 2297441534 DropRelayCtrl 5;
BA_ "SPN" SG_ 2297441534 DropRelayCtrl 5403;
BA_ "SigType" SG_ 2297441534 LiftRelayCtrl 5;
BA_ "SPN" SG_ 2297441534 LiftRelayCtrl 5402;
BA_ "SigType" SG_ 2297441534 MaterialDropActiveStatus 5;
BA_ "SPN" SG_ 2297441534 MaterialDropActiveStatus 5014;
BA_ "SigType" SG_ 2297441534 MaterialLiftActiveStatus 5;
BA_ "SPN" SG_ 2297441534 MaterialLiftActiveStatus 5013;
BA_ "SigType" SG_ 2297441534 GneratorCurrentBoostActiveStatus 5;
BA_ "SPN" SG_ 2297441534 GneratorCurrentBoostActiveStatus 5012;
BA_ "SigType" SG_ 2297441534 MaterialDropSwitch 5;
BA_ "SPN" SG_ 2297441534 MaterialDropSwitch 5011;
BA_ "SigType" SG_ 2297441534 MaterialLiftSwitch 5;
BA_ "SPN" SG_ 2297441534 MaterialLiftSwitch 5010;
BA_ "SPN" SG_ 2297441534 MagnetReverseCurrent 5009;
BA_ "SPN" SG_ 2297441534 MagnetForwardCurrent 5008;
VAL_ 3221225472 TirePressThresholdDetection 7 "Not available" 6 "Error indicator" 5 "Not defined" 4 "Extreme under pressure  The tire pressure is at a level where the safety of the vehicle may be jeopardised" 3 "Under pressure  The tire pressure is lower than the pressure defined by the vehicle or tire manufacturer" 2 "No warning pressure  The tire pressure is within the thresholds defined by the vehicle or tire manufacturer" 1 "Over pressure  The tire pressure is higher than the pressure defined by the vehicle or tire manufacturer" 0 "Extreme over pressure  The tire pressure is at a level where the safety of the vehicle may be jeopardised" ;
VAL_ 3221225472 CTIWheelEndElectricalFault 3 "Not Supported" 2 "Error" 1 "Not Defined" 0 "Ok  No Fault" ;
VAL_ 3221225472 CTITireStatus 3 "Not Supported" 2 "Error" 1 "Tire leak detected" 0 "Ok no fault" ;
VAL_ 3221225472 CTIWheelSensorStatus 3 "Not Supported" 2 "Not Defined" 1 "On tire is polled" 0 "Off / isolated from CTI Pressure Controller" ;
VAL_ 3221225472 EngTurningGearEngaged 1 "Engaged" 0 "Not engaged" 3 "Not available" 2 "Error" ;
VAL_ 3221225472 FlashRedStopLamp 3 "Unavailable / Do Not Flash" 2 "Reserved" 1 "Fast Flash" 0 "Slow Flash" ;
VAL_ 3221225472 FlashProtectLamp 3 "Unavailable / Do Not Flash" 2 "Reserved" 1 "Fast Flash" 0 "Slow Flash" ;
VAL_ 3221225472 FlashMalfuncIndicatorLamp 3 "Unavailable / Do Not Flash" 2 "Reserved" 1 "Fast Flash" 0 "Slow Flash" ;
VAL_ 3221225472 FlashAmberWarningLamp 3 "Unavailable / Do Not Flash" 2 "Reserved" 1 "Fast Flash" 0 "Slow Flash" ;
VAL_ 3221225472 MalfunctionIndicatorLampStatus 3 "Not available" 2 "Reserved" 1 "Lamp on" 0 "Lamp off" ;
VAL_ 3221225472 AmberWarningLampStatus 3 "Not available" 2 "Reserved" 1 "Lamp on" 0 "Lamp off" ;
VAL_ 3221225472 RedStopLampState 3 "Not available" 2 "Reserved" 1 "Lamp on" 0 "Lamp off" ;
VAL_ 3221225472 ProtectLampStatus 3 "Not available" 2 "Reserved" 1 "Lamp on" 0 "Lamp off" ;
VAL_ 2566834691 FlashRedStopLamp 3 "Unavailable / Do Not Flash" 2 "Reserved" 1 "Fast Flash" 0 "Slow Flash" ;
VAL_ 2566834691 FlashProtectLamp 3 "Unavailable / Do Not Flash" 2 "Reserved" 1 "Fast Flash" 0 "Slow Flash" ;
VAL_ 2566834691 FlashMalfuncIndicatorLamp 3 "Unavailable / Do Not Flash" 2 "Reserved" 1 "Fast Flash" 0 "Slow Flash" ;
VAL_ 2566834691 FlashAmberWarningLamp 3 "Unavailable / Do Not Flash" 2 "Reserved" 1 "Fast Flash" 0 "Slow Flash" ;
VAL_ 2566834691 MalfunctionIndicatorLampStatus 3 "Not available" 2 "Reserved" 1 "Lamp on" 0 "Lamp off" ;
VAL_ 2566834691 AmberWarningLampStatus 3 "Not available" 2 "Reserved" 1 "Lamp on" 0 "Lamp off" ;
VAL_ 2566834691 RedStopLampState 3 "Not available" 2 "Reserved" 1 "Lamp on" 0 "Lamp off" ;
VAL_ 2566834691 ProtectLampStatus 3 "Not available" 2 "Reserved" 1 "Lamp on" 0 "Lamp off" ;
VAL_ 2566834699 FlashRedStopLamp 3 "Unavailable / Do Not Flash" 2 "Reserved" 1 "Fast Flash" 0 "Slow Flash" ;
VAL_ 2566834699 FlashProtectLamp 3 "Unavailable / Do Not Flash" 2 "Reserved" 1 "Fast Flash" 0 "Slow Flash" ;
VAL_ 2566834699 FlashMalfuncIndicatorLamp 3 "Unavailable / Do Not Flash" 2 "Reserved" 1 "Fast Flash" 0 "Slow Flash" ;
VAL_ 2566834699 FlashAmberWarningLamp 3 "Unavailable / Do Not Flash" 2 "Reserved" 1 "Fast Flash" 0 "Slow Flash" ;
VAL_ 2566834699 MalfunctionIndicatorLampStatus 3 "Not available" 2 "Reserved" 1 "Lamp on" 0 "Lamp off" ;
VAL_ 2566834699 AmberWarningLampStatus 3 "Not available" 2 "Reserved" 1 "Lamp on" 0 "Lamp off" ;
VAL_ 2566834699 RedStopLampState 3 "Not available" 2 "Reserved" 1 "Lamp on" 0 "Lamp off" ;
VAL_ 2566834699 ProtectLampStatus 3 "Not available" 2 "Reserved" 1 "Lamp on" 0 "Lamp off" ;
VAL_ 2566834688 FlashRedStopLamp 3 "Unavailable / Do Not Flash" 2 "Reserved" 1 "Fast Flash" 0 "Slow Flash" ;
VAL_ 2566834688 FlashProtectLamp 3 "Unavailable / Do Not Flash" 2 "Reserved" 1 "Fast Flash" 0 "Slow Flash" ;
VAL_ 2566834688 FlashMalfuncIndicatorLamp 3 "Unavailable / Do Not Flash" 2 "Reserved" 1 "Fast Flash" 0 "Slow Flash" ;
VAL_ 2566834688 FlashAmberWarningLamp 3 "Unavailable / Do Not Flash" 2 "Reserved" 1 "Fast Flash" 0 "Slow Flash" ;
VAL_ 2566834688 MalfunctionIndicatorLampStatus 3 "Not available" 2 "Reserved" 1 "Lamp on" 0 "Lamp off" ;
VAL_ 2566834688 AmberWarningLampStatus 3 "Not available" 2 "Reserved" 1 "Lamp on" 0 "Lamp off" ;
VAL_ 2566834688 RedStopLampState 3 "Not available" 2 "Reserved" 1 "Lamp on" 0 "Lamp off" ;
VAL_ 2566834688 ProtectLampStatus 3 "Not available" 2 "Reserved" 1 "Lamp on" 0 "Lamp off" ;
VAL_ 2566910720 WaterInFuelIndicator 3 "Not available" 2 "Error" 1 "Yes" 0 "No" ;
VAL_ 2566844672 EngShutdownOverrideSwitch 3 "Not available" 2 "Error" 1 "On" 0 "Off" ;
VAL_ 2566844672 EngTestModeSwitch 3 "Not available" 2 "Error" 1 "On" 0 "Off" ;
VAL_ 2566844672 EngIdleDecrementSwitch 3 "Not available" 2 "Error" 1 "On" 0 "Off" ;
VAL_ 2566844672 EngIdleIncrementSwitch 3 "Not available" 2 "Error" 1 "On" 0 "Off" ;
VAL_ 2566844672 CruiseCtrlStates 7 "Not available" 6 "Accelerator Override" 5 "Set" 4 "Resume" 3 "Decelerate" 2 "Accelerate" 1 "Hold" 0 "Off/Disabled" ;
VAL_ 2566844672 PTOGovernorState 31 "Not available" 19 "PTO set speed memory 2" 18 "PTO set speed memory 1" 17 "Preprogrammed set speed 8" 16 "Preprogrammed set speed 7" 15 "Preprogrammed set speed 6" 14 "Preprogrammed set speed 5" 13 "Preprogrammed set speed 4" 12 "Preprogrammed set speed 3" 11 "Preprogrammed set speed 2" 10 "Preprogrammed set speed 1" 9 "Accelerator Override" 8 "Accelerate" 7 "Resume" 6 "Decelerate/Coast" 5 "Set" 4 "Remote Standby" 3 "Standby" 2 "Remote Hold" 1 "Hold" 0 "Off/Disabled" ;
VAL_ 2566844672 CruiseCtrlAccelerateSwitch 3 "Not available" 2 "Error" 1 "Cruise control activator in position accelerate" 0 "Cruise control activator not in the position accelerate" ;
VAL_ 2566844672 CruiseCtrlResumeSwitch 3 "Not available" 2 "Error" 1 "Cruise control activator in position resume" 0 "Cruise control activator not in the position resume" ;
VAL_ 2566844672 CruiseCtrlCoastSwitch 3 "Not available" 2 "Error" 1 "Cruise control activator in position coast" 0 "Cruise control activator not in the position coast" ;
VAL_ 2566844672 CruiseCtrlSetSwitch 3 "Not available" 2 "Error" 1 "Cruise control activator in position set" 0 "Cruise control activator not in the position set" ;
VAL_ 2566844672 ClutchSwitch 3 "Not available" 2 "Error" 1 "Clutch pedal depressed" 0 "Clutch pedal released" ;
VAL_ 2566844672 BrakeSwitch 3 "Not Available" 2 "Error" 1 "Brake pedal depressed" 0 "Brake pedal released" ;
VAL_ 2566844672 CruiseCtrlEnableSwitch 3 "Not available" 2 "Error" 1 "Cruise control enabled" 0 "Cruise control disabled" ;
VAL_ 2566844672 CruiseCtrlActive 3 "Not available" 2 "Error" 1 "Cruise control switched on" 0 "Cruise control switched off" ;
VAL_ 2566844672 ParkBrakeReleaseInhibitRq 3 "Unavailable" 2 "SAEReserved" 1 "ParkBrakeReleaseInhibitRqed" 0 "ParkBrakeReleaseInhibitNotRqed" ;
VAL_ 2566844672 CruiseCtrlPauseSwitch 3 "Take No Action" 2 "Error Indicator" 1 "On" 0 "Off" ;
VAL_ 2566844672 ParkingBrakeSwitch 3 "Not available" 2 "Error" 1 "Parking brake set" 0 "Parking brake not set" ;
VAL_ 2566844672 TwoSpeedAxleSwitch 3 "Not available" 2 "Error" 1 "High speed range" 0 "Low speed range" ;
VAL_ 2566841344 ClntLvlEngPrtctionShutdownStatus 3 "Not Available" 2 "Reserved" 1 "Enabled  calibration allows engine protection due to low coolant level and the override is currently not active" 0 "Disabled  calibration does not allow engine protection due to low coolant level or the override is currently active" ;
VAL_ 2566841344 PTOShutdownHasShutdownEng 3 "Not available" 2 "Error" 1 "Yes" 0 "No" ;
VAL_ 2566841344 EngAirShutoffStatus 3 "Not Available" 2 "Error" 1 "Air flow restricted" 0 "Air flow allowed to engine" ;
VAL_ 2566841344 EngOverspeedTest 3 "Not Available" 2 "Reserved" 1 "Engine Overspeed Test Active" 0 "Engine Overspeed Test Not Active" ;
VAL_ 2566841344 EngAirShutoffCmdStatus 0 "Air Shutoff Disabled not attempting to shutoff engine air supply" 3 "Not Available" 2 "Reserved" 1 "Air Shutoff Enabled attempting to shutoff engine air supply" ;
VAL_ 2566841344 EngAlarmOutputCmdStatus 3 "Not Available" 2 "Reserved" 1 "Engine Alarm Output Command Active" 0 "Engine Alarm Output Command Not Active" ;
VAL_ 2566841344 EngAlarmAcknowledge 3 "Not Available" 2 "Error" 1 "Engine Alarm Acknowledge Active" 0 "Engine Alarm Acknowledge Not Active" ;
VAL_ 2566841344 EngProtectionSystemConfig 3 "Not available" 2 "Error" 1 "Enabled in calibration" 0 "Disabled in calibration" ;
VAL_ 2566841344 EngProtectionSystemTimerState 3 "Not available" 2 "Error" 1 "Active" 0 "Inactive" ;
VAL_ 2566841344 EngProtectionSystemTimerOverride 3 "Not available" 2 "Error" 1 "Active" 0 "Inactive" ;
VAL_ 2566841344 EngPrtctnSystmApprachingShutdown 3 "Not available" 2 "Error" 1 "Approaching" 0 "Not approaching" ;
VAL_ 2566841344 EngPrtectionSystemHasShutdownEng 3 "Not available" 2 "Error" 1 "Yes" 0 "No" ;
VAL_ 2566841344 EngWaitToStartLamp 3 "Not available" 2 "Error" 1 "On" 0 "Off" ;
VAL_ 2566841344 RefrigerantHighPressSwitch 3 "Not available" 2 "Error" 1 "Pressure too high compressor clutch may be disengaged" 0 "Pressure normal" ;
VAL_ 2566841344 RefrigerantLowPressSwitch 3 "Not available" 2 "Error" 1 "Pressure too low compressor clutch may be disengaged" 0 "Pressure normal" ;
VAL_ 2566841344 A_CHighPressFanSwitch 3 "Not available" 2 "Error" 1 "Pressure high fan may be engaged" 0 "Pressure normal" ;
VAL_ 2566841344 EngIdleShutdownTimerFunction 3 "Not available" 2 "Error" 1 "Enabled in calibration" 0 "Disabled in calibration" ;
VAL_ 2566841344 EngIdleShutdownTimerState 3 "Not available" 2 "Error" 1 "Active" 0 "Inactive" ;
VAL_ 2566841344 EngIdleShutdownTimerOverride 3 "Not available" 2 "Error" 1 "Active" 0 "Inactive" ;
VAL_ 2566841344 EngIdleShutdownDriverAlertMode 3 "Not available" 2 "Error" 1 "Active" 0 "Inactive" ;
VAL_ 2566841344 EngIdleShutdownHasShutdownEng 3 "Not available" 2 "Error" 1 "Yes" 0 "No" ;
VAL_ 2566803211 TrailerVDCActive 3 "Not availble or not installed" 2 "Reserved" 1 "VDC active" 0 "VDC passive but installed" ;
VAL_ 2566803211 YCBrakeCtrlActive 3 "Dont care/Take no action" 2 "Reserved" 1 "YC brake control active" 0 "YC brake control passive but installed" ;
VAL_ 2566803211 YCEngCtrlActive 3 "Dont care/Take no action" 2 "Reserved" 1 "YC engine control active" 0 "YC engine control passive but installed" ;
VAL_ 2566803211 ROPBrakeCtrlActive 3 "Dont care/Take no action" 2 "Reserved" 1 "ROP brake control active" 0 "ROP brake control passive but installed" ;
VAL_ 2566803211 ROPEngCtrlActive 3 "Dont care/Take no action" 2 "Reserved" 1 "ROP engine control active" 0 "ROP engine control passive but installed" ;
VAL_ 2566803211 VDCBrakeLightRq 3 "Dont care/Take no action" 2 "Reserved" 1 "Turn brake light on" 0 "Turn brake light not on" ;
VAL_ 2566803211 VDCFullyOperational 3 "Dont care/Take no action" 2 "Reserved" 1 "Fully operational" 0 "Not fully operational" ;
VAL_ 2566803211 VDCInformationSignal 3 "Dont care/Take no action" 2 "Reserved" 1 "On" 0 "Off" ;
VAL_ 2566848256 EmssnCtrlSystmOprtrIndcmntSvrity 7 "Not Available / Not Supported" 6 "Temporary Override of Inducement" 5 "Inducement Level 5  Euro VI defined Severe Inducement Active  FMI 0" 4 "Inducement Level 4  Euro VI defined Severe Inducement Enabled  FMI 16" 3 "Inducement Level 3  Euro VI defined LowLevel Inducement Active  FMI 16" 2 "Inducement Level 2  Euro VI defined LowLevel Inducement Enabled  FMI 15" 1 "Inducement Level 1 Euro VI defined Driver Warning System Active  FMI 15" 0 "Driver Warning LowLevel Inducement and Severe Inducement NonActive" ;
VAL_ 2566848256 DrvrWarningSystemIndicatorStatus 7 "not available" 6 "reserved for SAE assignment" 5 "reserved for SAE assignment" 4 "On  fast blink 1 Hz  Used for the second driver warning system detection threshold for diesel exhaust fluid level" 3 "reserved for SAE assignment" 2 "reserved for SAE assignment" 1 "On  solid  Used when driver warning system is activated for any relevant malfunction" 0 "Off  Used when driver warning system is nonactive  which by requirement means the lowlevel and severe" ;
VAL_ 2566848256 OperatorShiftPrompt 3 "dont care/take no action" 2 "downshift indicator active" 1 "upshift indicator active" 0 "indicators inactive" ;
VAL_ 2566848256 WaterInFuelIndicator 3 "Not available" 2 "Error" 1 "Yes" 0 "No" ;
VAL_ 2364539904 EngStarterMode 11 "Reserved" 10 "starter inhibited due to active SCR inducement" 9 "starter inhibited due to intake air shutoff valve being active" 13 "error legacy implementation only use 1110" 15 "not available" 14 "error" 12 "starter inhibited  reason unknown" 8 "starter inhibited due to starter overtemp" 7 "starter inhibited due to active immobilizer" 6 "starter inhibited due to driveline engaged or other transmission inhibit" 5 "starter inhibited due to engine not ready for start preheating" 4 "starter inhibited due to engine already running" 3 "start finished starter not active after having been actively engaged after 50ms mode goes to 0000" 2 "starter active gear engaged" 1 "starter active gear not engaged" 0 "start not requested" ;
VAL_ 2364539904 ActlEngPrcntTorqueHighResolution 8 "1111  not available" 7 "0875" 1 "0125" 0 "0000" ;
VAL_ 2559835902 ErrorCode 5 "Other" 255 "Not Available" 4 "Pending Name not set" 3 "Checksum does not match" 2 "Item conflict" 1 "Item(s) not allowed to change" 0 "Security not satisfied" ;
VAL_ 2559835902 NMControlModeIndicator 8 "ReqNameAddressClaim" 7 "AdoptPendingName" 6 "ReqCurrentName" 5 "ReqPendingName" 4 "NameNACK" 3 "NameACK" 2 "CurrentName" 1 "PendingName" 0 "SetPendingName" ;
VAL_ 2559770366 HydrocarbonDoserPurgingRequired 3 "Not available" 2 "Purging required  urgent" 1 "Purging required  less urgent" 0 "Purging not required" ;
VAL_ 2559770366 DiagnosticStatusOfHCDoser 7 "Not available" 6 "Error    System test has failed" 2 "101  SAE reserved" 1 "Internal system test is in process" 0 "System test has executed and passed or System test has not yet executed" ;
VAL_ 2559770366 HCDoserInjectingStatus 3 "Not available" 2 "Error" 1 "Injecting active" 0 "Injecting not active" ;
VAL_ 2559770366 HCDoserStatus 7 "Not available" 6 "Error" 5 "SAE reserved" 4 "SAE reserved" 3 "HC doser enabled waiting for regeneration" 2 "SAE reserved" 1 "HC doser active" 0 "HC doser disabled" ;
VAL_ 2559704830 LubricationTimingCycleCmd 3 "Take no action" 2 "Reserved" 1 "Enable" 0 "Pause" ;
VAL_ 2559704830 LubricationPumpEnableCmd 3 "Take no action" 2 "Reserved" 1 "Reset pump operation" 0 "No action Normal pump operation" ;
VAL_ 2559704830 LubricationOperationModeSetCmd 7 "Take no action" 4 "Test Mode  3" 3 "Test Mode  2" 2 "Test Mode  1" 1 "Manual Service Mode" 0 "Automatic Mode" ;
VAL_ 2559704830 LubricationCycleSetCmd 7 "No action" 3 "to 110  Reserved" 2 "Cycle mode  3 Highest Lubrication Frequency" 1 "Cycle mode  2" 0 "Cycle mode  1 Lowest Lubrication Frequency" ;
VAL_ 2559704830 LubricationCycleModeLockCmd 3 "No action" 2 "Reserved" 1 "Locked" 0 "Not Locked" ;
VAL_ 2559639294 SupplementalFanPowerHold 3 "Dont Care/Take no action" 2 "Reserved" 1 "Enable" 0 "Disable" ;
VAL_ 2559639294 SupplementalFanDirectionCmd 3 "Dont care/take no action leave function as is" 2 "Reserved" 1 "Reverse" 0 "Forward" ;
VAL_ 2559639294 SupplementalFanEnableCmd 3 "Dont Care/Take no action" 2 "Reserved" 1 "Enable" 0 "Disable" ;
VAL_ 2559573758 ClntLvlEngPrtctnShtdwnOvrrideCmd 3 "Dont care/take no action" 2 "Reserved" 1 "Enable engine protection shutdown override due to low coolant level" 0 "Disable engine protection shutdown override due to low coolant level" ;
VAL_ 2349530878 CruiseCtrlPauseCmd 3 "Dont care/take no action" 2 "Reserved" 1 "Cruise Control is not allowed" 0 "Cruise Control is allowed" ;
VAL_ 2349530878 CruiseCtrlResumeCmd 3 "Dont Care/take no action" 2 "Reserved" 1 "Cruise Control Resume Requested" 0 "Cruise Control Resume not Requested" ;
VAL_ 2349530878 CruiseCtrlDisableCmd 3 "Dont care/take no action" 2 "Reserved" 1 "Cruise Control is not allowed" 0 "Cruise Control is allowed" ;
VAL_ 2365428734 GenFrequencySelection 14 "Unknown" 13 "SAE Reserved" 12 "SAE Reserved" 11 "SAE Reserved" 10 "SAE Reserved" 9 "SAE Reserved" 8 "SAE Reserved" 7 "SAE Reserved" 6 "SAE Reserved" 5 "SAE Reserved" 4 "SAE Reserved" 3 "SAE Reserved" 2 "400 Hz" 1 "60 Hz" 0 "50 Hz" ;
VAL_ 2566702846 EngOBDWarmUpSequence 3 "Not supported or not available" 2 "SAE reserved" 1 "A warm-up cycle has occurred on this engine start" 0 "A warm-up cycle has not occurred on this engine start" ;
VAL_ 2566705918 FlashProtectLamp 3 "Unavailable / Do Not Flash" 2 "Reserved" 1 "Fast Flash" 0 "Slow Flash" ;
VAL_ 2566705918 FlashAmberWarningLamp 3 "Unavailable / Do Not Flash" 2 "Reserved" 1 "Fast Flash" 0 "Slow Flash" ;
VAL_ 2566705918 FlashRedStopLamp 3 "Unavailable / Do Not Flash" 2 "Reserved" 1 "Fast Flash" 0 "Slow Flash" ;
VAL_ 2566705918 FlashMalfuncIndicatorLamp 3 "Unavailable / Do Not Flash" 2 "Reserved" 1 "Fast Flash" 0 "Slow Flash" ;
VAL_ 2566705918 ProtectLampStatus 3 "Not available" 2 "Reserved" 1 "Lamp on" 0 "Lamp off" ;
VAL_ 2566705918 AmberWarningLampStatus 3 "Not available" 2 "Reserved" 1 "Lamp on" 0 "Lamp off" ;
VAL_ 2566705918 RedStopLampState 3 "Not available" 2 "Reserved" 1 "Lamp on" 0 "Lamp off" ;
VAL_ 2566705918 MalfunctionIndicatorLampStatus 3 "Not available" 2 "Reserved" 1 "Lamp on" 0 "Lamp off" ;
VAL_ 2566705662 FlashProtectLamp 3 "Unavailable / Do Not Flash" 2 "Reserved" 1 "Fast Flash" 0 "Slow Flash" ;
VAL_ 2566705662 FlashAmberWarningLamp 3 "Unavailable / Do Not Flash" 2 "Reserved" 1 "Fast Flash" 0 "Slow Flash" ;
VAL_ 2566705662 FlashRedStopLamp 3 "Unavailable / Do Not Flash" 2 "Reserved" 1 "Fast Flash" 0 "Slow Flash" ;
VAL_ 2566705662 FlashMalfuncIndicatorLamp 3 "Unavailable / Do Not Flash" 2 "Reserved" 1 "Fast Flash" 0 "Slow Flash" ;
VAL_ 2566705662 ProtectLampStatus 3 "Not available" 2 "Reserved" 1 "Lamp on" 0 "Lamp off" ;
VAL_ 2566705662 AmberWarningLampStatus 3 "Not available" 2 "Reserved" 1 "Lamp on" 0 "Lamp off" ;
VAL_ 2566705662 RedStopLampState 3 "Not available" 2 "Reserved" 1 "Lamp on" 0 "Lamp off" ;
VAL_ 2566705662 MalfunctionIndicatorLampStatus 3 "Not available" 2 "Reserved" 1 "Lamp on" 0 "Lamp off" ;
VAL_ 2349465342 StaticRollAngleStatus 7 "Not available" 6 "Error" 5 "Reserved" 4 "Angle Data Invalid" 3 "Sensor Reboots" 2 "Sensor Defect" 1 "Sensor OK" 0 "Sensor Busy" ;
VAL_ 2559049470 DesiredEngFuelingState 3 "Dont care / Take no action" 2 "Parameter supported but no request" 1 "Fueling desired keep engine running" 0 "Fueling not desired shut off engine fueling" ;
VAL_ 2349596414 DrvrActvtnDmndFrAdvncdEmrgncyBrk 3 "dont care / take no action" 2 "reserved" 1 "the driver wants the Advanced Emergency Braking System to warn or intervene if necessary no deactivation of" 0 "the driver does not want the Advanced Emergency Braking System to warn or intervene at any time deactivation of" ;
VAL_ 2566705150 NOxSnsorATI2SelfdiagnosisTrigger 15 "Not supported" 5 "1110 Reserved" 4 "NOx Sensor ATI2 Self Diagnosis Request at After Run" 3 "NOx Sensor ATI2 Self Diagnosis Request at fuel cut" 2 "NOx Sensor ATI2 Self Diagnosis Request at partial load" 1 "NOx Sensor ATI2 Self Diagnosis Request at Lambda10" 0 "Diagnostic mode disabled" ;
VAL_ 2566705150 NOxSnsorATO2SelfdiagnosisTrigger 15 "Not supported" 5 "1110 Reserved" 4 "NOx Sensor ATO2 Self Diagnosis Request at After Run" 3 "NOx Sensor ATO2 Self Diagnosis Request at fuel cut" 2 "NOx Sensor ATO2 Self Diagnosis Request at partial load" 1 "NOx Sensor ATO2 Self Diagnosis Request at Lambda10" 0 "Diagnostic mode disabled" ;
VAL_ 2566705150 NOxSnsorATI1SelfdiagnosisTrigger 15 "Not supported" 5 "1110 Reserved" 4 "NOx Sensor ATI1 Self Diagnosis Request at After Run" 3 "NOx Sensor ATI1 Self Diagnosis Request at fuel cut" 2 "NOx Sensor ATI1 Self Diagnosis Request at partial load" 1 "NOx Sensor ATI1 Self Diagnosis Request at Lambda10" 0 "Diagnostic mode disabled" ;
VAL_ 2566705150 NOxSnsorATO1SelfdiagnosisTrigger 15 "Not supported" 5 "1110 Reserved" 4 "NOx Sensor ATO1 Self Diagnosis Request at After Run" 3 "NOx Sensor ATO1 Self Diagnosis Request at fuel cut" 2 "NOx Sensor ATO1 Self Diagnosis Request at partial load" 1 "NOx Sensor ATO1 Self Diagnosis Request at Lambda10" 0 "Diagnostic mode disabled" ;
VAL_ 2566704382 Aftrtrtmnt2OtltGsSnsrPowerSupply 3 "Unavailable" 2 "Error" 1 "On The ECU is powering the Aftertreatment 2 Outlet Gas Sensor" 0 "Off" ;
VAL_ 2566704382 Aftrtrtmnt2IntkGsSnsrPowerSupply 3 "Unavailable" 2 "Error" 1 "On The ECU is powering the Aftertreatment 2 Intake Gas Sensor" 0 "Off" ;
VAL_ 2566704382 Aftrtrtmnt1OtltGsSnsrPowerSupply 3 "Unavailable" 2 "Error" 1 "On The ECU is powering the Aftertreatment 1 Outlet Gas Sensor" 0 "Off" ;
VAL_ 2566704382 Aftrtrtmnt1IntkGsSnsrPowerSupply 3 "Unavailable" 2 "Error" 1 "On The ECU is powering the Aftertreatment 1 Intake Gas Sensor" 0 "Off" ;
VAL_ 2566704126 EngExhstGsRcrcltn1Acttr2OprtnStt 15 "Not available" 14 "Error" 6 "1101 Reserved for future assignment" 5 "Uncontrolled Shutdown Active actuator current is off so it is limp" 4 "Controlled Shutdown Active driving to the default position  usually this means closed" 3 "Derate Active torque output reduced due to environmental conditions" 2 "Alarm High Severity functional but transient performance may be reduced" 1 "Alarm fully operational but needs service" 0 "Normal" ;
VAL_ 2566704126 EngExhstGsRcrcltn1Acttr1OprtnStt 15 "Not available" 14 "Error" 6 "1101 Reserved for future assignment" 5 "Uncontrolled Shutdown Active actuator current is off so it is limp" 4 "Controlled Shutdown Active driving to the default position  usually this means closed" 3 "Derate Active torque output reduced due to environmental conditions" 2 "Alarm High Severity functional but transient performance may be reduced" 1 "Alarm fully operational but needs service" 0 "Normal" ;
VAL_ 2566704126 EngExhstGsRcrcltn1Acttr2TmpSttus 7 "Not available" 6 "Error" 5 "Not Defined" 4 "Low Most severe" 3 "Low Least severe" 2 "In Range" 1 "High Least severe" 0 "High Most severe" ;
VAL_ 2566704126 EngExhstGsRcrcltn1Acttr1TmpSttus 7 "Not available" 6 "Error" 5 "Not Defined" 4 "Low Most severe" 3 "Low Least severe" 2 "In Range" 1 "High Least severe" 0 "High Most severe" ;
VAL_ 2566703870 EngExhstGsRcrcltn2Acttr2OprtnStt 15 "Not available" 14 "Error" 6 "1101 Reserved for future assignment" 5 "Uncontrolled Shutdown Active actuator current is off so it is limp" 4 "Controlled Shutdown Active driving to the default position  usually this means closed" 3 "Derate Active torque output reduced due to environmental conditions" 2 "Alarm High Severity functional but transient performance may be reduced" 1 "Alarm fully operational but needs service" 0 "Normal" ;
VAL_ 2566703870 EngExhstGsRcrcltn2Acttr1OprtnStt 5 "Uncontrolled Shutdown Active actuator current is off so it is limp" 4 "Controlled Shutdown Active driving to the default position  usually this means closed" 3 "Derate Active torque output reduced due to environmental conditions" 2 "Alarm High Severity functional but transient performance may be reduced" 1 "Alarm fully operational but needs service" 0 "Normal" 15 "Not available" 14 "Error" 6 "1101 Reserved for future assignment" ;
VAL_ 2566703870 EngExhstGsRcrcltn2Acttr2TmpSttus 7 "Not available" 6 "Error" 5 "Not Defined" 4 "Low Most severe" 3 "Low Least severe" 2 "In Range" 1 "High Least severe" 0 "High Most severe" ;
VAL_ 2566703870 EngExhstGsRcrcltn2Acttr1TmpSttus 7 "Not available" 6 "Error" 5 "Not Defined" 4 "Low Most severe" 3 "Low Least severe" 2 "In Range" 1 "High Least severe" 0 "High Most severe" ;
VAL_ 2566703358 EngFuelingInhibitAllowed 3 "Not Supported" 2 "SAE Reserved" 1 "Engine will stop fueling in response to SPN 5793 Desired Engine Fueling State" 0 "Engine currently will not stop fueling in response to SPN 5793 Desired Engine Fueling State" ;
VAL_ 2566703358 FeedbackEngFuelingState 3 "Not Supported" 2 "No active request per SPN 5793 Desired Engine Fueling State" 1 "Engine will be kept running SPN 5793 Desired Engine Fueling State  01" 0 "Fueling is or will be inhibited SPN 5793 Desired Engine Fueling State  00" ;
VAL_ 2566701822 HybridSystemStopIndicator 3 "Not available" 2 "Hybrid System Stop Indicator is flashing" 1 "Hybrid System Stop Indicator is on continuously" 0 "Hybrid System Stop Indicator is off" ;
VAL_ 2566701822 HybridSystemOverheatIndicator 3 "Not available" 2 "Hybrid System Temperature Indicator is flashing" 1 "Hybrid System Temperature Indicator is on continuously" 0 "Hybrid System Temperature Indicator is off" ;
VAL_ 2566701822 HybridSystemWarningIndicator 3 "Not available" 2 "Hybrid System Warning Indicator is flashing" 1 "Hybrid System Warning Indicator is on continuously" 0 "Hybrid System Warning Indicator is off" ;
VAL_ 2431661310 Aftrtrtmnt2SCRIntrmdtNH3GsSn5861 3 "Heater off or Not available" 2 "Preheat 1" 1 "Preheat 2" 0 "Automatic" ;
VAL_ 2431661310 Aftrtrtmnt2SCRIntrmdtNH3GsSnsrAt 3 "Not available" 2 "Error" 1 "Heater element is in range" 0 "Heater element is not in range" ;
VAL_ 2431661310 Aftrtrtmnt2SCRIntrmdtNH3GsSnsrPw 3 "Not available" 2 "Error" 1 "Heater element is in range" 0 "Heater element is not in range" ;
VAL_ 2431661310 Aftrtrtmnt2SCRIntrmdtNH3RdngStbl 3 "Not available" 2 "Error" 1 "Reading is stable" 0 "Reading is not stable" ;
VAL_ 2431661054 Aftrtrtmnt1SCRIntrmdtNH3GsSn5854 3 "Heater off or not available" 2 "Preheat 1" 1 "Preheat 2" 0 "Automatic" ;
VAL_ 2431661054 Aftrtrtmnt1SCRIntrmdtNH3GsSnsrAt 3 "Not available" 2 "Error" 1 "Heater element is in range" 0 "Heater element is not in range" ;
VAL_ 2431661054 Aftrtrtmnt1SCRIntrmdtNH3GsSnsrPw 3 "Not available" 2 "Error" 1 "Power is in range" 0 "Power is not in range" ;
VAL_ 2431661054 Aftrtrtmnt1SCRIntrmdtNH3RdngStbl 3 "Not available" 2 "Error" 1 "Reading is stable" 0 "Reading is not stable" ;
VAL_ 2230334206 LnrDsplcmntSnsrSnsrFigureOfMerit 3 "Sensor not available" 2 "Sensor failed" 1 "Sensor degraded" 0 "Sensor fully functional" ;
VAL_ 2230333950 WandSensorFigureOfMerit 3 "Sensor not available" 2 "Sensor failed" 1 "Sensor degraded" 0 "Sensor fully functional" ;
VAL_ 2364551166 BndOffPrbabilityOfRelevantObject 7 "signal not available / not installed" 6 "error indication" 5 "relevant object is already in a turning maneuver" 4 "highest probability for a bend off maneuver of the relevant object" 3 "high probability for a bend off maneuver of the relevant object" 2 "medium probability for a bend off maneuver of the relevant object" 1 "low probability for a bend off maneuver of the relevant object" 0 "no indication for a bend off maneuver of the relevant object" ;
VAL_ 2364551166 RlvntObjctDtctdFrAdvncdEmrgncyBr 7 "signal not available / not installed" 6 "error indication" 2 "relevant object is not being detected reliably" 1 "relevant object is being monitored" 0 "no relevant object monitored" ;
VAL_ 2364551166 CollisionWarningLevel 15 "dont care / take no action" 7 "warning level 7  highest" 6 "warning level 6" 5 "warning level 5" 4 "warning level 4" 3 "warning level 3" 2 "warning level 2" 1 "warning level 1  lowest" 0 "no warning" ;
VAL_ 2364551166 AdvncdEmrgencyBrakingSystemState 15 "not available / not installed" 14 "error indication" 7 "emergency braking active" 6 "collision warning with braking eg brake jerk or partial braking" 5 "collision warning active not affecting vehicle dynamics" 4 "driver overrides system" 3 "system is ready no warning and no braking active" 2 "system is deactivated by driver" 1 "system is temporarily not available eg due to boundary conditions necessary for operation" 0 "system is not ready initialization not finished" ;
VAL_ 2566730238 Fan2DriveState 15 "Not available" 14 "Other" 13 "Engine brake" 12 "Timer" 11 "A/C system" 10 "Transmission retarder" 9 "Manual control" 8 "Reverse Operation" 7 "Default Operation" 6 "Excessive hydraulic oil temperature" 5 "Excessive transmission oil temperature" 4 "Excessive engine coolant temperature" 3 "Excessive engine oil temperature" 2 "Excessive engine air temperature" 1 "Engine systemGeneral" 0 "Fan off" ;
VAL_ 2566711038 LubricationTimingCycleStatus 3 "Not available or not installed" 2 "Error" 1 "Enabled" 0 "Paused" ;
VAL_ 2566711038 LubricationReservoirLevel 3 "Not available or not installed" 2 "Error" 1 "Reservoir Low" 0 "Reservoir Not Low" ;
VAL_ 2566711038 LubricationPumpEnableStatus 3 "Not available" 2 "Error" 1 "Enabled" 0 "Disabled" ;
VAL_ 2566711038 LubricationOperationModeStatus 7 "Not Available" 6 "Error" 5 "Reserved" 4 "Test Mode  3" 3 "Test Mode  2" 2 "Test Mode  1" 1 "Manual Service Mode" 0 "Automatic Mode" ;
VAL_ 2566711038 LubricationCycleModeStatus 7 "Not available" 6 "Error" 3 "to 101  Reserved" 2 "Cycle mode  3 Highest Lubrication Frequency" 1 "Cycle mode  2" 0 "Cycle mode  1 Lowest Lubrication Frequency" ;
VAL_ 2566711038 LubricationCycleModeLockStatus 3 "Not available" 2 "Error" 1 "Locked" 0 "Not Locked" ;
VAL_ 2566710014 SupplementalFanDriveStatus 15 "Not available" 14 "Error" 6 "1101   Reserved for future assignment  Not used" 5 "Uncontrolled Shutdown Active  Actuator current is off so it is limp" 4 "Controlled Shutdown Active  Driving to the default position  usually this means closed" 3 "Derate Active  Torque output reduced due to environmental conditions" 2 "Alarm High Severity  Functional but transient performance may be reduced" 1 "Alarm  Fully operational but needs service" 0 "Normal  OK" ;
VAL_ 2566710014 SupplementalFanCtrlTempStatus 7 "Not available" 6 "Error" 5 "Not Defined" 4 "Low Most severe" 3 "Low Least severe" 2 "In Range" 1 "High Least severe" 0 "High most severe" ;
VAL_ 2566710014 SupplementalFanVelocityStatus 15 "Not available" 14 "Error" 4 "Fan Stall" 3 "Fan Spin Down" 2 "Fan Spin Up" 1 "Velocity Error  unable to achieve commanded speed" 0 "At Velocity Fan OK" ;
VAL_ 2566710014 SupplementalFanDirectionStatus 3 "Not available/Not installed" 2 "Error" 1 "Reverse" 0 "Forward" ;
VAL_ 2566710014 SupplementalFanEnableStatus 3 "Not available/Not installed" 2 "Error" 1 "Enabled" 0 "Disabled" ;
VAL_ 2566708478 CruiseCtrlSystemCmdState 3 "Cruise control has been reactivated by Cruise Control Resume Command SPN 5604 and Cruise Control States" 2 "Cruise control  has been disabled by Cruise Control Pause Command SPN 5605" 1 "Cruise control has been disabled by Cruise Control Disable Command SPN 5603" 0 "No Cruise Control System Command" 7 "Not Supported" 5 "110  SAE Reserved" 4 "Cruise control device has received a Cruise Control Resume Command SPN 5604 but there is no previous set" ;
VAL_ 2566708478 AdptiveCruiseCtrlReadinessStatus 3 "Not Available/Not Supported" 2 "Error Condition  Prevents system from responding to adaptive cruise controller commands even though it is" 1 "On  Cruise Control System is configured to accept commands from an adaptive cruise controller" 0 "Off  Cruise Control System is not configured to accept commands from an adaptive cruise controller" ;
VAL_ 2297441790 VrtclAcclrtnExRangeFigureOfMerit 3 "not available" 2 "error" 1 "verticalacceleration is degraded Data is suspect due to enviromental conditions" 0 "vertical acceleration is fully functional Data is within sensor specification" ;
VAL_ 2297441790 LngtdnlAcclrtnExRngFigureOfMerit 3 "not available" 2 "error" 1 "longitudinal acceleration is degraded Data is suspect due to enviromental conditions" 0 "longitudinal acceleration is fully functional Data is within sensor specification" ;
VAL_ 2297441790 LtrlAcclrtonExRangeFigureOfMerit 3 "not available" 2 "error" 1 "lateral acceleration is degraded Data is suspect due to enviromental conditions" 0 "lateral acceleration is fully functional Data is within sensor specification" ;
VAL_ 2364549630 RollAngleExRangeFigureOfMerit 3 "Not available" 2 "Error" 1 "Roll rate degraded Data is suspect due to environmental conditions" 0 "Roll rate fully functional Data is within sensor specification" ;
VAL_ 2364549630 RollAngleExRangeCompensation 3 "Not Available" 2 "Error" 1 "Off" 0 "On" ;
VAL_ 2364549630 PitchAngleExRangeFigureOfMerit 3 "Not available" 2 "Error" 1 "Pitch rate degraded Data is suspect due to environmental conditions" 0 "Pitch rate fully functional Data is within sensor specification" ;
VAL_ 2364549630 PitchAngleExRangeCompensation 3 "Not Available" 2 "Error" 1 "Off" 0 "On" ;
VAL_ 2499614462 OccpntClssficationSystem10Status 3 "not available" 2 "Error  Classification cannot be determined" 1 "occupied" 0 "empty" ;
VAL_ 2499614462 OccpntClssificationSystem9Status 3 "not available" 2 "Error  Classification cannot be determined" 1 "occupied" 0 "empty" ;
VAL_ 2499614462 OccpntClssificationSystem8Status 3 "not available" 2 "Error  Classification cannot be determined" 1 "occupied" 0 "empty" ;
VAL_ 2499614462 OccpntClssificationSystem7Status 3 "not available" 2 "Error  Classification cannot be determined" 1 "occupied" 0 "empty" ;
VAL_ 2499614462 OccpntClssificationSystem6Status 3 "not available" 2 "Error  Classification cannot be determined" 1 "occupied" 0 "empty" ;
VAL_ 2499614462 OccpntClssificationSystem5Status 3 "not available" 2 "Error  Classification cannot be determined" 1 "occupied" 0 "empty" ;
VAL_ 2499614462 OccpntClssificationSystem4Status 3 "not available" 2 "Error  Classification cannot be determined" 1 "occupied" 0 "empty" ;
VAL_ 2499614462 OccpntClssificationSystem3Status 3 "not available" 2 "Error  Classification cannot be determined" 1 "occupied" 0 "empty" ;
VAL_ 2499614462 PssngrOccpntClssfctnSystemStatus 7 "not available" 5 "Error  Classification of occupant cannot be determined" 3 "adult" 4 "large adult" 2 "small adult" 1 "child" 0 "empty" ;
VAL_ 2499614462 DrvrOccpntClssfctionSystemStatus 7 "not available" 6 "Error  Classification of occupant cannot be determined" 5 "reserved" 4 "large adult" 3 "adult" 2 "small adult" 1 "child" 0 "empty" ;
VAL_ 2560098046 CabNoiseCtrlTuningStatus 12 "Reserved" 11 "Reserved" 6 "Reserved" 5 "Reserved" 4 "Reserved" 3 "Reserved" 15 "Not Available/Not Tuning/Not Requested" 14 "Tuning Mode  Error" 10 "Automatic Tuning Mode  Saving Data" 9 "Automatic Tuning Mode  Command Complete" 8 "Automatic Tuning Mode" 7 "Manual Tuning Denied  Requires Security Verification" 13 "Reserved" 2 "Manual Tuning Mode  Saving Data" 1 "Manual Tuning Mode  Command Complete" 0 "Manual Tuning Mode" ;
VAL_ 2560098046 CabNoiseCtrlStatus 3 "Not Available/Not Requested" 2 "Error Indicator" 1 "Cab Noise Control System OFFLine" 0 "Cab Noise Control System ONLine" ;
VAL_ 2560163582 CabNoiseCtrlTuningCmd 7 "Dont Care NOT Commanded" 6 "Reserved" 5 "Exit Tuning Saving Parameters" 4 "Exit Tuning Not Saving Parameters" 3 "Remain In Tuning Save Current Parameters" 2 "Activate Automatic Tuning State Saveing Parameters Exit on Completion" 1 "Activate Automatic Tuning Wait for Save and Exit Commands" 0 "Activate Manual Tuning Wait for Save and Exit Commands" ;
VAL_ 2560163582 CabNoiseCtrlCmd 3 "Dont Care/Not Commanded" 2 "Reserved" 1 "Bring Cab Noise Control System On Line" 0 "Take Cab Noise Control System Off Line" ;
VAL_ 2297441534 MagnetGeneratorCtrl 3 "Take No Action" 2 "Reserved" 1 "On Enable Generator" 0 "Off Disable Generator" ;
VAL_ 2297441534 DropRelayCtrl 3 "Take No Action" 2 "Reserved" 1 "On Enable Drop Relay Request" 0 "Off Disable Drop Relay Request" ;
VAL_ 2297441534 LiftRelayCtrl 3 "Take No Action" 2 "Reserved" 1 "On Enable Lift Relay Request" 0 "Off Disable Lift Relay Request" ;
VAL_ 2297441534 MaterialDropActiveStatus 3 "Not Available" 2 "Error" 1 "On" 0 "Off" ;
VAL_ 2297441534 MaterialLiftActiveStatus 3 "Not Available" 2 "Error" 1 "On" 0 "Off" ;
VAL_ 2297441534 GneratorCurrentBoostActiveStatus 3 "Not Available" 2 "Error" 1 "On" 0 "Off" ;
VAL_ 2297441534 MaterialDropSwitch 3 "Not Available" 2 "Error" 1 "Drop" 0 "Dont Drop" ;
VAL_ 2297441534 MaterialLiftSwitch 3 "Not Available" 2 "Error" 1 "Lift" 0 "Dont Lift" ;

SG_MUL_VAL_ 2559835902 CommandArbitraryAddressCapable NMControlModeIndicator 0-3, 8-8;
SG_MUL_VAL_ 2559835902 CommandVehicleSystemInstance NMControlModeIndicator 0-3, 8-8;
SG_MUL_VAL_ 2559835902 CommandIndustryGroup NMControlModeIndicator 0-3, 8-8;
SG_MUL_VAL_ 2559835902 CommandVehicleSystem NMControlModeIndicator 0-3, 8-8;
SG_MUL_VAL_ 2559835902 CommandFunction NMControlModeIndicator 0-3, 8-8;
SG_MUL_VAL_ 2559835902 CommandFunctionInstance NMControlModeIndicator 0-3, 8-8;
SG_MUL_VAL_ 2559835902 CommandECUInstance NMControlModeIndicator 0-3, 8-8;
SG_MUL_VAL_ 2559835902 CommandManufacturerCode NMControlModeIndicator 0-3, 8-8;
SG_MUL_VAL_ 2559835902 ArbitraryAddressCapableQualifier NMControlModeIndicator 0-0, 4-4, 8-8;
SG_MUL_VAL_ 2559835902 IndustryGroupQualifierFlag NMControlModeIndicator 0-0, 4-4, 8-8;
SG_MUL_VAL_ 2559835902 VehicleSystemInstanceQualifierFl NMControlModeIndicator 0-0, 4-4, 8-8;
SG_MUL_VAL_ 2559835902 VehicleSystemQualifierFlag NMControlModeIndicator 0-0, 4-4, 8-8;
SG_MUL_VAL_ 2559835902 FunctionQualifierFlag NMControlModeIndicator 0-0, 4-4, 8-8;
SG_MUL_VAL_ 2559835902 FunctionInstanceQualifierFlag NMControlModeIndicator 0-0, 4-4, 8-8;
SG_MUL_VAL_ 2559835902 ECUInstanceQualifierFlag NMControlModeIndicator 0-0, 4-4, 8-8;
SG_MUL_VAL_ 2559835902 ManufacturerCodeQualifierFlag NMControlModeIndicator 0-0, 4-4, 8-8;
